VERSION "dbc-export 1 2025.20.8"

NS_ :

BS_:

BU_: ADSP APB APP APS APSB BB BMS CC CMP CMPD CP DAS DI DIF DIR DPB EPAS3P EPAS3S EPASTP EPASTS EPBL EPBR ESP EVSE FC GTW HCML HCMR HVP IBST ICR IDB LS OCS1P PARK PCS PM PMF PMR PNCD PTC RADC RCM RCM2 RCM3 RCU SCCM SCM SCS SDCR TAS TCU TPMS TRCM UI UIS UMC USM VC VCFRONT VCLEFT VCRIGHT VCSEC VEH

BO_ 1835 TAS_alertLog: 8 TAS
 SG_ TAS_alertID M : 0|9@1+ (1,0) [0|511] "" Vector__XXX
 SG_ TAS_alertState : 15|1@1+ (1,0) [0|1] "" Vector__XXX
 SG_ TAS_a001_InternalWatchdog m1 : 16|1@1+ (1,0) [0|1] "" Vector__XXX
 SG_ TAS_a002_CPUUndervoltage m2 : 16|1@1+ (1,0) [0|1] "" Vector__XXX
 SG_ TAS_a002_PowerOnReset m2 : 17|1@1+ (1,0) [0|1] "" Vector__XXX
 SG_ TAS_a003_AssertID m3 : 16|16@1+ (1,0) [0|65535] "" Vector__XXX
 SG_ TAS_a003_LineNumber m3 : 32|16@1+ (1,0) [0|65535] "" Vector__XXX
 SG_ TAS_a003_Data m3 : 48|16@1+ (1,0) [0|65535] "" Vector__XXX
 SG_ TAS_a012_ClockError m12 : 16|1@1+ (1,0) [0|1] "" Vector__XXX
 SG_ TAS_a012_FlashError m12 : 17|1@1+ (1,0) [0|1] "" Vector__XXX
 SG_ TAS_a012_SoftwareReset m12 : 18|1@1+ (1,0) [0|1] "" Vector__XXX
 SG_ TAS_a012_CheckstopReset m12 : 19|1@1+ (1,0) [0|1] "" Vector__XXX
 SG_ TAS_a012_DebugReset m12 : 20|1@1+ (1,0) [0|1] "" Vector__XXX
 SG_ TAS_a012_ExternalReset m12 : 21|1@1+ (1,0) [0|1] "" Vector__XXX
 SG_ TAS_a021_Task1msLate m21 : 16|1@1+ (1,0) [0|1] "" Vector__XXX
 SG_ TAS_a021_Task1msStarved m21 : 17|1@1+ (1,0) [0|1] "" Vector__XXX
 SG_ TAS_a021_Task1msMissed m21 : 18|1@1+ (1,0) [0|1] "" Vector__XXX
 SG_ TAS_a021_Task10msLate m21 : 19|1@1+ (1,0) [0|1] "" Vector__XXX
 SG_ TAS_a021_Task10msStarved m21 : 20|1@1+ (1,0) [0|1] "" Vector__XXX
 SG_ TAS_a021_Task10msMissed m21 : 21|1@1+ (1,0) [0|1] "" Vector__XXX
 SG_ TAS_a021_Task100msLate m21 : 22|1@1+ (1,0) [0|1] "" Vector__XXX
 SG_ TAS_a021_Task100msStarved m21 : 23|1@1+ (1,0) [0|1] "" Vector__XXX
 SG_ TAS_a021_Task100msMissed m21 : 24|1@1+ (1,0) [0|1] "" Vector__XXX
 SG_ TAS_a021_Task1000msLate m21 : 25|1@1+ (1,0) [0|1] "" Vector__XXX
 SG_ TAS_a021_Task1000msStarved m21 : 26|1@1+ (1,0) [0|1] "" Vector__XXX
 SG_ TAS_a021_Task1000msMissed m21 : 27|1@1+ (1,0) [0|1] "" Vector__XXX
 SG_ TAS_a022_TaskInitErrorCount m22 : 16|8@1+ (1,0) [0|255] "" Vector__XXX
 SG_ TAS_a022_TaskInitError0 m22 : 24|8@1+ (1,0) [0|255] "" Vector__XXX
 SG_ TAS_a022_TaskInitError1 m22 : 32|8@1+ (1,0) [0|255] "" Vector__XXX
 SG_ TAS_a022_TaskInitError2 m22 : 40|8@1+ (1,0) [0|255] "" Vector__XXX
 SG_ TAS_a022_TaskInitError3 m22 : 48|8@1+ (1,0) [0|255] "" Vector__XXX
 SG_ TAS_a022_TaskInitError4 m22 : 56|8@1+ (1,0) [0|255] "" Vector__XXX
 SG_ TAS_a025_vehicleLockAtCrash m25 : 16|1@1+ (1,0) [0|1] "" Vector__XXX
 SG_ TAS_a025_CANCrashIsActive m25 : 17|1@1+ (1,0) [0|1] "" Vector__XXX
 SG_ TAS_a025_appCrashIsActive m25 : 18|1@1+ (1,0) [0|1] "" Vector__XXX
 SG_ TAS_a025_lastCrashEvent m25 : 24|32@1+ (1,0) [0|4294967295] "" Vector__XXX
 SG_ TAS_a030_PWMdutyCycleFL m30 : 16|16@1+ (0.0025,0) [0|163.8375] "" Vector__XXX
 SG_ TAS_a030_PWMfrequencyFL m30 : 32|16@1+ (0.025,0) [0|1638.375] "" Vector__XXX
 SG_ TAS_a030_PWMfaultFL m30 : 48|4@1+ (1,0) [0|15] "" Vector__XXX
 SG_ TAS_a031_PWMdutyCycleFR m31 : 16|16@1+ (0.0025,0) [0|163.8375] "" Vector__XXX
 SG_ TAS_a031_PWMfrequencyFR m31 : 32|16@1+ (0.025,0) [0|1638.375] "" Vector__XXX
 SG_ TAS_a031_PWMfaultFR m31 : 48|4@1+ (1,0) [0|15] "" Vector__XXX
 SG_ TAS_a032_PWMdutyCycleRL m32 : 16|16@1+ (0.0025,0) [0|163.8375] "" Vector__XXX
 SG_ TAS_a032_PWMfrequencyRL m32 : 32|16@1+ (0.025,0) [0|1638.375] "" Vector__XXX
 SG_ TAS_a032_PWMfaultRL m32 : 48|4@1+ (1,0) [0|15] "" Vector__XXX
 SG_ TAS_a033_PWMdutyCycleRR m33 : 16|16@1+ (0.0025,0) [0|163.8375] "" Vector__XXX
 SG_ TAS_a033_PWMfrequencyRR m33 : 32|16@1+ (0.025,0) [0|1638.375] "" Vector__XXX
 SG_ TAS_a033_PWMfaultRR m33 : 48|4@1+ (1,0) [0|15] "" Vector__XXX
 SG_ TAS_a034_PWMdutyCycleFL m34 : 16|16@1+ (0.0025,0) [0|163.8375] "" Vector__XXX
 SG_ TAS_a034_PWMfrequencyFL m34 : 32|16@1+ (0.025,0) [0|1638.375] "" Vector__XXX
 SG_ TAS_a034_PWMfaultFL m34 : 48|4@1+ (1,0) [0|15] "" Vector__XXX
 SG_ TAS_a035_PWMdutyCycleFR m35 : 16|16@1+ (0.0025,0) [0|163.8375] "" Vector__XXX
 SG_ TAS_a035_PWMfrequencyFR m35 : 32|16@1+ (0.025,0) [0|1638.375] "" Vector__XXX
 SG_ TAS_a035_PWMfaultFR m35 : 48|4@1+ (1,0) [0|15] "" Vector__XXX
 SG_ TAS_a036_PWMdutyCycleRL m36 : 16|16@1+ (0.0025,0) [0|163.8375] "" Vector__XXX
 SG_ TAS_a036_PWMfrequencyRL m36 : 32|16@1+ (0.025,0) [0|1638.375] "" Vector__XXX
 SG_ TAS_a036_PWMfaultRL m36 : 48|4@1+ (1,0) [0|15] "" Vector__XXX
 SG_ TAS_a037_PWMdutyCycleRR m37 : 16|16@1+ (0.0025,0) [0|163.8375] "" Vector__XXX
 SG_ TAS_a037_PWMfrequencyRR m37 : 32|16@1+ (0.025,0) [0|1638.375] "" Vector__XXX
 SG_ TAS_a037_PWMfaultRR m37 : 48|4@1+ (1,0) [0|15] "" Vector__XXX
 SG_ TAS_a038_PWMdutyCycleFL m38 : 16|16@1+ (0.0025,0) [0|163.8375] "" Vector__XXX
 SG_ TAS_a038_PWMfrequencyFL m38 : 32|16@1+ (0.025,0) [0|1638.375] "" Vector__XXX
 SG_ TAS_a038_PWMfaultFL m38 : 48|4@1+ (1,0) [0|15] "" Vector__XXX
 SG_ TAS_a039_PWMdutyCycleFR m39 : 16|16@1+ (0.0025,0) [0|163.8375] "" Vector__XXX
 SG_ TAS_a039_PWMfrequencyFR m39 : 32|16@1+ (0.025,0) [0|1638.375] "" Vector__XXX
 SG_ TAS_a039_PWMfaultFR m39 : 48|4@1+ (1,0) [0|15] "" Vector__XXX
 SG_ TAS_a040_PWMdutyCycleRL m40 : 16|16@1+ (0.0025,0) [0|163.8375] "" Vector__XXX
 SG_ TAS_a040_PWMfrequencyRL m40 : 32|16@1+ (0.025,0) [0|1638.375] "" Vector__XXX
 SG_ TAS_a040_PWMfaultRL m40 : 48|4@1+ (1,0) [0|15] "" Vector__XXX
 SG_ TAS_a041_PWMdutyCycleRR m41 : 16|16@1+ (0.0025,0) [0|163.8375] "" Vector__XXX
 SG_ TAS_a041_PWMfrequencyRR m41 : 32|16@1+ (0.025,0) [0|1638.375] "" Vector__XXX
 SG_ TAS_a041_PWMfaultRR m41 : 48|4@1+ (1,0) [0|15] "" Vector__XXX
 SG_ TAS_a070_voltage12V m70 : 16|16@1+ (0.001,0) [0|65.535] "" Vector__XXX
 SG_ TAS_a071_voltage12V m71 : 16|16@1+ (0.001,0) [0|65.535] "" Vector__XXX
 SG_ TAS_a072_voltage5VOnBoard m72 : 16|16@1+ (0.001,0) [0|65.535] "" Vector__XXX
 SG_ TAS_a073_voltage5VOnBoard m73 : 16|16@1+ (0.001,0) [0|65.535] "" Vector__XXX
 SG_ TAS_a074_voltage5VOffBoard m74 : 16|16@1+ (0.001,0) [0|65.535] "" Vector__XXX
 SG_ TAS_a075_voltage5VOffBoard m75 : 16|16@1+ (0.001,0) [0|65.535] "" Vector__XXX
 SG_ TAS_a076_voltage5VOffBoard m76 : 16|16@1+ (0.001,0) [0|65.535] "" Vector__XXX
 SG_ TAS_a077_sensorVoltage m77 : 16|16@1+ (0.001,0) [0|65.535] "" Vector__XXX
 SG_ TAS_a077_sensorRefVoltage m77 : 32|16@1+ (0.001,0) [0|65.535] "" Vector__XXX
 SG_ TAS_a078_sensorVoltage m78 : 16|16@1+ (0.001,0) [0|65.535] "" Vector__XXX
 SG_ TAS_a078_sensorRefVoltage m78 : 32|16@1+ (0.001,0) [0|65.535] "" Vector__XXX
 SG_ TAS_a080_voltage5VHeight m80 : 16|16@1+ (0.001,0) [0|65.535] "" Vector__XXX
 SG_ TAS_a081_voltage5VHeight m81 : 16|16@1+ (0.001,0) [0|65.535] "" Vector__XXX
 SG_ TAS_a082_voltage5VHeight m82 : 16|16@1+ (0.001,0) [0|65.535] "" Vector__XXX
 SG_ TAS_a083_voltage5VAnalog m83 : 16|16@1+ (0.001,0) [0|65.535] "" Vector__XXX
 SG_ TAS_a084_voltage5VAnalog m84 : 16|16@1+ (0.001,0) [0|65.535] "" Vector__XXX
 SG_ TAS_a085_voltage5VAnalog m85 : 16|16@1+ (0.001,0) [0|65.535] "" Vector__XXX
 SG_ TAS_a086_voltage12VSwitched m86 : 16|16@1+ (0.001,0) [0|65.535] "" Vector__XXX
 SG_ TAS_a087_voltage12VSwitched m87 : 16|16@1+ (0.001,0) [0|65.535] "" Vector__XXX
 SG_ TAS_a093_readError m93 : 16|1@1+ (1,0) [0|1] "" Vector__XXX
 SG_ TAS_a093_IVOR2Exception m93 : 17|1@1+ (1,0) [0|1] "" Vector__XXX
 SG_ TAS_a098_VCFRONT_LVPowerState_MI m98 : 16|1@1+ (1,0) [0|1] "" Vector__XXX
 SG_ TAS_a098_VCFRONT_sensors_MIA m98 : 17|1@1+ (1,0) [0|1] "" Vector__XXX
 SG_ TAS_a098_VCFRONT_status_MIA m98 : 18|1@1+ (1,0) [0|1] "" Vector__XXX
 SG_ TAS_a098_VCFRONT_systemStatus_MI m98 : 19|1@1+ (1,0) [0|1] "" Vector__XXX
 SG_ TAS_a098_VCFRONT_vehNm_MIA m98 : 20|1@1+ (1,0) [0|1] "" Vector__XXX
 SG_ TAS_a099_UI_chassisControl_MIA m99 : 16|1@1+ (1,0) [0|1] "" Vector__XXX
 SG_ TAS_a099_UI_driverAssistMapData_ m99 : 17|1@1+ (1,0) [0|1] "" Vector__XXX
 SG_ TAS_a099_UI_suspensionControl_MI m99 : 18|1@1+ (1,0) [0|1] "" Vector__XXX
 SG_ TAS_a099_UI_vehicleModes_MIA m99 : 19|1@1+ (1,0) [0|1] "" Vector__XXX
 SG_ TAS_a100_RCM_inertial1_MIA m100 : 16|1@1+ (1,0) [0|1] "" Vector__XXX
 SG_ TAS_a100_RCM_inertial2_MIA m100 : 17|1@1+ (1,0) [0|1] "" Vector__XXX
 SG_ TAS_a101_ESP_brakeTorque_MIA m101 : 16|1@1+ (1,0) [0|1] "" Vector__XXX
 SG_ TAS_a101_ESP_status_MIA m101 : 17|1@1+ (1,0) [0|1] "" Vector__XXX
 SG_ TAS_a101_ESP_wheelRotation_MIA m101 : 18|1@1+ (1,0) [0|1] "" Vector__XXX
 SG_ TAS_a102_DI_chassisControl_MIA m102 : 16|1@1+ (1,0) [0|1] "" Vector__XXX
 SG_ TAS_a102_DI_locStatus_MIA m102 : 17|1@1+ (1,0) [0|1] "" Vector__XXX
 SG_ TAS_a102_DI_speed_MIA m102 : 18|1@1+ (1,0) [0|1] "" Vector__XXX
 SG_ TAS_a102_DI_systemStatus_MIA m102 : 19|1@1+ (1,0) [0|1] "" Vector__XXX
 SG_ TAS_a102_DI_vehicleEstimates_MIA m102 : 20|1@1+ (1,0) [0|1] "" Vector__XXX
 SG_ TAS_a102_DIF_torque_MIA m102 : 21|1@1+ (1,0) [0|1] "" Vector__XXX
 SG_ TAS_a102_DIR_torque_MIA m102 : 22|1@1+ (1,0) [0|1] "" Vector__XXX
 SG_ TAS_a103_GTW_carConfig_MIA m103 : 16|1@1+ (1,0) [0|1] "" Vector__XXX
 SG_ TAS_a103_GTW_time_MIA m103 : 17|1@1+ (1,0) [0|1] "" Vector__XXX
 SG_ TAS_a103_GTW_vehNm_MIA m103 : 18|1@1+ (1,0) [0|1] "" Vector__XXX
 SG_ TAS_a103_GTW_vin_MIA m103 : 19|1@1+ (1,0) [0|1] "" Vector__XXX
 SG_ TAS_a164_detectedDamperSolenoid m164 : 16|3@1+ (1,0) [0|7] "" Vector__XXX
 SG_ TAS_a164_expectedDamperSolenoid m164 : 19|3@1+ (1,0) [0|7] "" Vector__XXX
 SG_ TAS_a165_damperValveFault m165 : 16|4@1+ (1,0) [0|15] "" Vector__XXX
 SG_ TAS_a166_damperValveFault m166 : 16|4@1+ (1,0) [0|15] "" Vector__XXX
 SG_ TAS_a167_damperValveFault m167 : 16|4@1+ (1,0) [0|15] "" Vector__XXX
 SG_ TAS_a168_damperValveFault m168 : 16|4@1+ (1,0) [0|15] "" Vector__XXX
 SG_ TAS_a169_damperValveFault m169 : 16|4@1+ (1,0) [0|15] "" Vector__XXX
 SG_ TAS_a170_damperValveFault m170 : 16|4@1+ (1,0) [0|15] "" Vector__XXX
 SG_ TAS_a171_damperValveFault m171 : 16|4@1+ (1,0) [0|15] "" Vector__XXX
 SG_ TAS_a172_damperValveFault m172 : 16|4@1+ (1,0) [0|15] "" Vector__XXX
 SG_ TAS_a173_heightDelta_mm m173 : 16|8@1+ (1,-128) [-128|127] "" Vector__XXX
 SG_ TAS_a174_heightDelta_mm m174 : 16|8@1+ (1,-128) [-128|127] "" Vector__XXX
 SG_ TAS_a175_heightDelta_mm m175 : 16|8@1+ (1,-128) [-128|127] "" Vector__XXX
 SG_ TAS_a176_heightDelta_mm m176 : 16|8@1+ (1,-128) [-128|127] "" Vector__XXX
 SG_ TAS_a190_a2bFaultType m190 : 16|4@1+ (1,0) [0|15] "" Vector__XXX
 SG_ TAS_a190_a2bInterruptType m190 : 24|8@1+ (1,0) [0|255] "" Vector__XXX
 SG_ TAS_a190_a2bFaultSource m190 : 32|2@1+ (1,0) [0|3] "" Vector__XXX
 SG_ TAS_a191_a2bFaultType m191 : 16|4@1+ (1,0) [0|15] "" Vector__XXX
 SG_ TAS_a191_a2bInterruptType m191 : 24|8@1+ (1,0) [0|255] "" Vector__XXX
 SG_ TAS_a191_a2bFaultSource m191 : 32|2@1+ (1,0) [0|3] "" Vector__XXX
 SG_ TAS_a192_rideHeightVelDspFL m192 : 16|5@1- (0.2,0) [-3.2|3] "" Vector__XXX
 SG_ TAS_a192_rideHeightVelDspFR m192 : 24|5@1- (0.2,0) [-3.2|3] "" Vector__XXX
 SG_ TAS_a192_rideHeightVelDspRL m192 : 32|5@1- (0.2,0) [-3.2|3] "" Vector__XXX
 SG_ TAS_a192_rideHeightVelDspRR m192 : 37|5@1- (0.2,0) [-3.2|3] "" Vector__XXX
 SG_ TAS_a192_rideHeightVelObserverFL m192 : 42|5@1- (0.2,0) [-3.2|3] "" Vector__XXX
 SG_ TAS_a192_rideHeightVelObserverFR m192 : 47|5@1- (0.2,0) [-3.2|3] "" Vector__XXX
 SG_ TAS_a192_rideHeightVelObserverRL m192 : 52|5@1- (0.2,0) [-3.2|3] "" Vector__XXX
 SG_ TAS_a192_rideHeightVelObserverRR m192 : 57|5@1- (0.2,0) [-3.2|3] "" Vector__XXX
 SG_ TAS_a192_alertVersion m192 : 62|2@1+ (1,0) [0|3] "" Vector__XXX
 SG_ TAS_a193_EPAS3P_sysStatus_MIA m193 : 16|1@1+ (1,0) [0|1] "" Vector__XXX
 SG_ TAS_a210_heightSensorDeltaFL m210 : 16|8@1+ (1,-128) [-128|127] "" Vector__XXX
 SG_ TAS_a210_heightSensorDeltaFR m210 : 24|8@1+ (1,-128) [-128|127] "" Vector__XXX
 SG_ TAS_a210_heightSensorDeltaRL m210 : 32|8@1+ (1,-128) [-128|127] "" Vector__XXX
 SG_ TAS_a210_heightSensorDeltaRR m210 : 40|8@1+ (1,-128) [-128|127] "" Vector__XXX
 SG_ TAS_a220_galleryPressure m220 : 16|8@1+ (0.1,0) [0|25.5] "" Vector__XXX
 SG_ TAS_a220_timeInExhaust m220 : 24|32@1+ (1,0) [0|4294967295] "" Vector__XXX
 SG_ TAS_a221_galleryPressureDelta m221 : 16|8@1+ (0.1,0) [0|25.5] "" Vector__XXX
 SG_ TAS_a221_timeInIdle m221 : 24|32@1+ (1,0) [0|4294967295] "" Vector__XXX
 SG_ TAS_a222_galleryPressureDelta m222 : 16|8@1+ (0.1,0) [0|25.5] "" Vector__XXX
 SG_ TAS_a223_galleryPressure m223 : 16|8@1+ (0.1,0) [0|25.5] "" Vector__XXX
 SG_ TAS_a223_valveOnFL m223 : 24|1@1+ (1,0) [0|1] "" Vector__XXX
 SG_ TAS_a223_valveOnFR m223 : 25|1@1+ (1,0) [0|1] "" Vector__XXX
 SG_ TAS_a223_valveOnRL m223 : 26|1@1+ (1,0) [0|1] "" Vector__XXX
 SG_ TAS_a223_valveOnRR m223 : 27|1@1+ (1,0) [0|1] "" Vector__XXX
 SG_ TAS_a223_valveOnReservoir m223 : 28|1@1+ (1,0) [0|1] "" Vector__XXX
 SG_ TAS_a224_galleryPressure m224 : 16|8@1+ (0.1,0) [0|25.5] "" Vector__XXX
 SG_ TAS_a224_valveOnFL m224 : 24|1@1+ (1,0) [0|1] "" Vector__XXX
 SG_ TAS_a224_valveOnFR m224 : 25|1@1+ (1,0) [0|1] "" Vector__XXX
 SG_ TAS_a224_valveOnRL m224 : 26|1@1+ (1,0) [0|1] "" Vector__XXX
 SG_ TAS_a224_valveOnRR m224 : 27|1@1+ (1,0) [0|1] "" Vector__XXX
 SG_ TAS_a224_valveOnReservoir m224 : 28|1@1+ (1,0) [0|1] "" Vector__XXX
 SG_ TAS_a225_galleryPressure m225 : 16|8@1+ (0.1,0) [0|25.5] "" Vector__XXX
 SG_ TAS_a226_PWMdutyCycleFL m226 : 16|16@1+ (0.0025,0) [0|163.8375] "" Vector__XXX
 SG_ TAS_a226_PWMfrequencyFL m226 : 32|16@1+ (0.025,0) [0|1638.375] "" Vector__XXX
 SG_ TAS_a226_PWMfaultFL m226 : 48|4@1+ (1,0) [0|15] "" Vector__XXX
 SG_ TAS_a227_PWMdutyCycleFR m227 : 16|16@1+ (0.0025,0) [0|163.8375] "" Vector__XXX
 SG_ TAS_a227_PWMfrequencyFR m227 : 32|16@1+ (0.025,0) [0|1638.375] "" Vector__XXX
 SG_ TAS_a227_PWMfaultFR m227 : 48|4@1+ (1,0) [0|15] "" Vector__XXX
 SG_ TAS_a228_PWMdutyCycleRL m228 : 16|16@1+ (0.0025,0) [0|163.8375] "" Vector__XXX
 SG_ TAS_a228_PWMfrequencyRL m228 : 32|16@1+ (0.025,0) [0|1638.375] "" Vector__XXX
 SG_ TAS_a228_PWMfaultRL m228 : 48|4@1+ (1,0) [0|15] "" Vector__XXX
 SG_ TAS_a229_PWMdutyCycleRR m229 : 16|16@1+ (0.0025,0) [0|163.8375] "" Vector__XXX
 SG_ TAS_a229_PWMfrequencyRR m229 : 32|16@1+ (0.025,0) [0|1638.375] "" Vector__XXX
 SG_ TAS_a229_PWMfaultRR m229 : 48|4@1+ (1,0) [0|15] "" Vector__XXX
 SG_ TAS_a232_detectedSuspensionType m232 : 16|3@1+ (1,0) [0|7] "" Vector__XXX
 SG_ TAS_a232_expectedSuspensionType m232 : 19|3@1+ (1,0) [0|7] "" Vector__XXX
 SG_ TAS_a234_detectedDamperHydraulic m234 : 16|2@1+ (1,0) [0|3] "" Vector__XXX
 SG_ TAS_a234_expectedDamperHydraulic m234 : 18|2@1+ (1,0) [0|3] "" Vector__XXX
 SG_ TAS_a240_highAdjustCountRatio m240 : 16|1@1+ (1,0) [0|1] "" Vector__XXX
 SG_ TAS_a240_highAdjustTimeRatio m240 : 17|1@1+ (1,0) [0|1] "" Vector__XXX
 SG_ TAS_a240_highCrossPressure m240 : 18|1@1+ (1,0) [0|1] "" Vector__XXX
 SG_ TAS_a240_highCompExhTimeRatio m240 : 19|1@1+ (1,0) [0|1] "" Vector__XXX
 SG_ TAS_a240_adjustCountRatioSpring m240 : 20|3@1+ (1,0) [0|7] "" Vector__XXX
 SG_ TAS_a240_adjustCountRatio m240 : 24|8@1+ (0.02952756,0) [0|7.5295278] "" Vector__XXX
 SG_ TAS_a240_adjustTimeRatioSpring m240 : 32|3@1+ (1,0) [0|7] "" Vector__XXX
 SG_ TAS_a240_adjustTimeRatio m240 : 40|8@1+ (0.02952756,0) [0|7.5295278] "" Vector__XXX
 SG_ TAS_a240_compExhTimeRatio m240 : 48|8@1+ (0.0294117648154,0) [0|7.50000002793] "" Vector__XXX
 SG_ TAS_a240_crossPressure m240 : 56|8@1- (0.1,0) [-12.8|12.7] "" Vector__XXX
 SG_ TAS_a285_twistLevel m285 : 16|8@1+ (1,-128) [-128|127] "" Vector__XXX
 SG_ TAS_a290_twistLevel m290 : 16|8@1+ (1,-128) [-128|127] "" Vector__XXX
 SG_ TAS_a291_frontAxleHeight m291 : 16|8@1+ (1,-128) [-128|127] "" Vector__XXX
 SG_ TAS_a292_rearAxleHeight m292 : 16|8@1+ (1,-128) [-128|127] "" Vector__XXX
 SG_ TAS_a293_frontAxleHeight m293 : 16|8@1+ (1,-128) [-128|127] "" Vector__XXX
 SG_ TAS_a294_rearAxleHeight m294 : 16|8@1+ (1,-128) [-128|127] "" Vector__XXX
 SG_ TAS_a295_targetHeight m295 : 16|8@1+ (1,-128) [-128|127] "" Vector__XXX
 SG_ TAS_a296_detectedChassisType m296 : 16|3@1+ (1,0) [0|7] "" Vector__XXX
 SG_ TAS_a296_expectedChassisType m296 : 19|3@1+ (1,0) [0|7] "" Vector__XXX
 SG_ TAS_a319_detectedDrivetrainType m319 : 16|2@1+ (1,0) [0|3] "" Vector__XXX
 SG_ TAS_a319_expectedDrivetrainType m319 : 18|2@1+ (1,0) [0|3] "" Vector__XXX

BO_ 852 TAS_alertMatrix: 8 TAS
 SG_ TAS_matrixIndex M : 0|4@1+ (1,0) [0|15] "" Vector__XXX
 SG_ TAS_a001_WatchdogReset m0 : 4|1@1+ (1,0) [0|1] "" Vector__XXX
 SG_ TAS_a002_PowerLossReset m0 : 5|1@1+ (1,0) [0|1] "" Vector__XXX
 SG_ TAS_a003_SWAssertion m0 : 6|1@1+ (1,0) [0|1] "" Vector__XXX
 SG_ TAS_a012_CPUReset m0 : 15|1@1+ (1,0) [0|1] "" Vector__XXX
 SG_ TAS_a015_NVMMError m0 : 18|1@1+ (1,0) [0|1] "" Vector__XXX
 SG_ TAS_a016_NVMMRecordError m0 : 19|1@1+ (1,0) [0|1] "" Vector__XXX
 SG_ TAS_a021_TaskSchedulerError m0 : 24|1@1+ (1,0) [0|1] "" Vector__XXX
 SG_ TAS_a022_TaskInitError m0 : 25|1@1+ (1,0) [0|1] "" Vector__XXX
 SG_ TAS_a023_rtosResetRequested m0 : 26|1@1+ (1,0) [0|1] "" Vector__XXX
 SG_ TAS_a024_prefetchAbort m0 : 27|1@1+ (1,0) [0|1] "" Vector__XXX
 SG_ TAS_a025_CrashEvent m0 : 28|1@1+ (1,0) [0|1] "" Vector__XXX
 SG_ TAS_a030_PWMerrorFL m0 : 33|1@1+ (1,0) [0|1] "" Vector__XXX
 SG_ TAS_a031_PWMerrorFR m0 : 34|1@1+ (1,0) [0|1] "" Vector__XXX
 SG_ TAS_a032_PWMerrorRL m0 : 35|1@1+ (1,0) [0|1] "" Vector__XXX
 SG_ TAS_a033_PWMerrorRR m0 : 36|1@1+ (1,0) [0|1] "" Vector__XXX
 SG_ TAS_a034_PWMshortFL m0 : 37|1@1+ (1,0) [0|1] "" Vector__XXX
 SG_ TAS_a035_PWMshortFR m0 : 38|1@1+ (1,0) [0|1] "" Vector__XXX
 SG_ TAS_a036_PWMshortRL m0 : 39|1@1+ (1,0) [0|1] "" Vector__XXX
 SG_ TAS_a037_PWMshortRR m0 : 40|1@1+ (1,0) [0|1] "" Vector__XXX
 SG_ TAS_a038_PWMopenFL m0 : 41|1@1+ (1,0) [0|1] "" Vector__XXX
 SG_ TAS_a039_PWMopenFR m0 : 42|1@1+ (1,0) [0|1] "" Vector__XXX
 SG_ TAS_a040_PWMopenRL m0 : 43|1@1+ (1,0) [0|1] "" Vector__XXX
 SG_ TAS_a041_PWMopenRR m0 : 44|1@1+ (1,0) [0|1] "" Vector__XXX
 SG_ TAS_a043_Task1msError m0 : 46|1@1+ (1,0) [0|1] "" Vector__XXX
 SG_ TAS_a044_Task10msError m0 : 47|1@1+ (1,0) [0|1] "" Vector__XXX
 SG_ TAS_a045_Task100msError m0 : 48|1@1+ (1,0) [0|1] "" Vector__XXX
 SG_ TAS_a046_Task1000msError m0 : 49|1@1+ (1,0) [0|1] "" Vector__XXX
 SG_ TAS_a061_XCPConnected m1 : 4|1@1+ (1,0) [0|1] "" Vector__XXX
 SG_ TAS_a062_XCPWasConnected m1 : 5|1@1+ (1,0) [0|1] "" Vector__XXX
 SG_ TAS_a063_abortFault m1 : 6|1@1+ (1,0) [0|1] "" Vector__XXX
 SG_ TAS_a064_abortFaultExt m1 : 7|1@1+ (1,0) [0|1] "" Vector__XXX
 SG_ TAS_a065_ahbWriteFault m1 : 8|1@1+ (1,0) [0|1] "" Vector__XXX
 SG_ TAS_a066_undefinedInstructionAbo m1 : 9|1@1+ (1,0) [0|1] "" Vector__XXX
 SG_ TAS_a067_reservedHandlerAbort m1 : 10|1@1+ (1,0) [0|1] "" Vector__XXX
 SG_ TAS_a070_underVoltage12V m1 : 13|1@1+ (1,0) [0|1] "" Vector__XXX
 SG_ TAS_a071_overVoltage12V m1 : 14|1@1+ (1,0) [0|1] "" Vector__XXX
 SG_ TAS_a072_shortCircuit5VOnBoard m1 : 15|1@1+ (1,0) [0|1] "" Vector__XXX
 SG_ TAS_a073_underVoltage5VOnBoard m1 : 16|1@1+ (1,0) [0|1] "" Vector__XXX
 SG_ TAS_a074_shortCircuit5VOffBoard m1 : 17|1@1+ (1,0) [0|1] "" Vector__XXX
 SG_ TAS_a075_underVoltage5VOffBoard m1 : 18|1@1+ (1,0) [0|1] "" Vector__XXX
 SG_ TAS_a076_overVoltage5VOffBoard m1 : 19|1@1+ (1,0) [0|1] "" Vector__XXX
 SG_ TAS_a077_pressureSigVTooLow m1 : 20|1@1+ (1,0) [0|1] "" Vector__XXX
 SG_ TAS_a078_pressureSigVTooHigh m1 : 21|1@1+ (1,0) [0|1] "" Vector__XXX
 SG_ TAS_a080_shortCircuit5VHeight m1 : 23|1@1+ (1,0) [0|1] "" Vector__XXX
 SG_ TAS_a081_underVoltage5VHeight m1 : 24|1@1+ (1,0) [0|1] "" Vector__XXX
 SG_ TAS_a082_overVoltage5VHeight m1 : 25|1@1+ (1,0) [0|1] "" Vector__XXX
 SG_ TAS_a083_shortCircuit5VAnalog m1 : 26|1@1+ (1,0) [0|1] "" Vector__XXX
 SG_ TAS_a084_underVoltage5VAnalog m1 : 27|1@1+ (1,0) [0|1] "" Vector__XXX
 SG_ TAS_a085_overVoltage5VAnalog m1 : 28|1@1+ (1,0) [0|1] "" Vector__XXX
 SG_ TAS_a086_underVoltage12VSwtchd m1 : 29|1@1+ (1,0) [0|1] "" Vector__XXX
 SG_ TAS_a087_overVoltage12VSwtchd m1 : 30|1@1+ (1,0) [0|1] "" Vector__XXX
 SG_ TAS_a093_OTPError m1 : 36|1@1+ (1,0) [0|1] "" Vector__XXX
 SG_ TAS_a098_VCFRONT_MIA m1 : 41|1@1+ (1,0) [0|1] "" Vector__XXX
 SG_ TAS_a099_UI_MIA m1 : 42|1@1+ (1,0) [0|1] "" Vector__XXX
 SG_ TAS_a100_RCM_MIA m1 : 43|1@1+ (1,0) [0|1] "" Vector__XXX
 SG_ TAS_a101_ESP_MIA m1 : 44|1@1+ (1,0) [0|1] "" Vector__XXX
 SG_ TAS_a102_DI_MIA m1 : 45|1@1+ (1,0) [0|1] "" Vector__XXX
 SG_ TAS_a103_GTW_MIA m1 : 46|1@1+ (1,0) [0|1] "" Vector__XXX
 SG_ TAS_a105_ECUDebugMode m1 : 48|1@1+ (1,0) [0|1] "" Vector__XXX
 SG_ TAS_a106_HighCPULoad m1 : 49|1@1+ (1,0) [0|1] "" Vector__XXX
 SG_ TAS_a107_HighStackUsage m1 : 50|1@1+ (1,0) [0|1] "" Vector__XXX
 SG_ TAS_a150_accelAvgImplausible_FL_ m2 : 33|1@1+ (1,0) [0|1] "" Vector__XXX
 SG_ TAS_a151_accelAvgImplausible_FL_ m2 : 34|1@1+ (1,0) [0|1] "" Vector__XXX
 SG_ TAS_a152_accelAvgImplausible_FL_ m2 : 35|1@1+ (1,0) [0|1] "" Vector__XXX
 SG_ TAS_a153_accelAvgImplausible_FR_ m2 : 36|1@1+ (1,0) [0|1] "" Vector__XXX
 SG_ TAS_a154_accelAvgImplausible_FR_ m2 : 37|1@1+ (1,0) [0|1] "" Vector__XXX
 SG_ TAS_a155_accelAvgImplausible_FR_ m2 : 38|1@1+ (1,0) [0|1] "" Vector__XXX
 SG_ TAS_a156_accelAvgImplausible_RL_ m2 : 39|1@1+ (1,0) [0|1] "" Vector__XXX
 SG_ TAS_a157_accelAvgImplausible_RL_ m2 : 40|1@1+ (1,0) [0|1] "" Vector__XXX
 SG_ TAS_a158_accelAvgImplausible_RL_ m2 : 41|1@1+ (1,0) [0|1] "" Vector__XXX
 SG_ TAS_a159_accelAvgImplausible_RR_ m2 : 42|1@1+ (1,0) [0|1] "" Vector__XXX
 SG_ TAS_a160_accelAvgImplausible_RR_ m2 : 43|1@1+ (1,0) [0|1] "" Vector__XXX
 SG_ TAS_a161_accelAvgImplausible_RR_ m2 : 44|1@1+ (1,0) [0|1] "" Vector__XXX
 SG_ TAS_a164_damperSolenoidMismatch m2 : 47|1@1+ (1,0) [0|1] "" Vector__XXX
 SG_ TAS_a165_damperValveCompFL m2 : 48|1@1+ (1,0) [0|1] "" Vector__XXX
 SG_ TAS_a166_damperValveRbndFL m2 : 49|1@1+ (1,0) [0|1] "" Vector__XXX
 SG_ TAS_a167_damperValveCompFR m2 : 50|1@1+ (1,0) [0|1] "" Vector__XXX
 SG_ TAS_a168_damperValveRbndFR m2 : 51|1@1+ (1,0) [0|1] "" Vector__XXX
 SG_ TAS_a169_damperValveCompRL m2 : 52|1@1+ (1,0) [0|1] "" Vector__XXX
 SG_ TAS_a170_damperValveRbndRL m2 : 53|1@1+ (1,0) [0|1] "" Vector__XXX
 SG_ TAS_a171_damperValveCompRR m2 : 54|1@1+ (1,0) [0|1] "" Vector__XXX
 SG_ TAS_a172_damperValveRbndRR m2 : 55|1@1+ (1,0) [0|1] "" Vector__XXX
 SG_ TAS_a173_staticLeakDetectFL m2 : 56|1@1+ (1,0) [0|1] "" Vector__XXX
 SG_ TAS_a174_staticLeakDetectFR m2 : 57|1@1+ (1,0) [0|1] "" Vector__XXX
 SG_ TAS_a175_staticLeakDetectRL m2 : 58|1@1+ (1,0) [0|1] "" Vector__XXX
 SG_ TAS_a176_staticLeakDetectRR m2 : 59|1@1+ (1,0) [0|1] "" Vector__XXX
 SG_ TAS_a190_a2bFrontAxleFault m3 : 13|1@1+ (1,0) [0|1] "" Vector__XXX
 SG_ TAS_a191_a2bRearAxleFault m3 : 14|1@1+ (1,0) [0|1] "" Vector__XXX
 SG_ TAS_a192_rideHeightObserverDiver m3 : 15|1@1+ (1,0) [0|1] "" Vector__XXX
 SG_ TAS_a193_EPAS3P_MIA m3 : 16|1@1+ (1,0) [0|1] "" Vector__XXX
 SG_ TAS_a194_a2bFrontAxleDataError m3 : 17|1@1+ (1,0) [0|1] "" Vector__XXX
 SG_ TAS_a195_a2bRearAxleDataError m3 : 18|1@1+ (1,0) [0|1] "" Vector__XXX
 SG_ TAS_a196_adaptiveDampingUsingDSP m3 : 19|1@1+ (1,0) [0|1] "" Vector__XXX
 SG_ TAS_a197_invalidAdaptiveModeRequ m3 : 20|1@1+ (1,0) [0|1] "" Vector__XXX
 SG_ TAS_a200_jackModeActive m3 : 23|1@1+ (1,0) [0|1] "" Vector__XXX
 SG_ TAS_a201_low12VBattery m3 : 24|1@1+ (1,0) [0|1] "" Vector__XXX
 SG_ TAS_a210_outOfRangeCalibration m3 : 33|1@1+ (1,0) [0|1] "" Vector__XXX
 SG_ TAS_a211_noRideHeightCalib m3 : 34|1@1+ (1,0) [0|1] "" Vector__XXX
 SG_ TAS_a213_yellowWarningLamp m3 : 36|1@1+ (1,0) [0|1] "" Vector__XXX
 SG_ TAS_a214_redWarningLamp m3 : 37|1@1+ (1,0) [0|1] "" Vector__XXX
 SG_ TAS_a215_limpHomeMode10 m3 : 38|1@1+ (1,0) [0|1] "" Vector__XXX
 SG_ TAS_a216_limpHomeMode20 m3 : 39|1@1+ (1,0) [0|1] "" Vector__XXX
 SG_ TAS_a217_limpHomeMode30 m3 : 40|1@1+ (1,0) [0|1] "" Vector__XXX
 SG_ TAS_a218_limpHomeMode40 m3 : 41|1@1+ (1,0) [0|1] "" Vector__XXX
 SG_ TAS_a220_exhaustGalleryFault m3 : 43|1@1+ (1,0) [0|1] "" Vector__XXX
 SG_ TAS_a221_valveLeakDetected m3 : 44|1@1+ (1,0) [0|1] "" Vector__XXX
 SG_ TAS_a222_compressorPrefillFault m3 : 45|1@1+ (1,0) [0|1] "" Vector__XXX
 SG_ TAS_a223_blockedAirline m3 : 46|1@1+ (1,0) [0|1] "" Vector__XXX
 SG_ TAS_a224_openAirline m3 : 47|1@1+ (1,0) [0|1] "" Vector__XXX
 SG_ TAS_a225_galleryPressureTooHigh m3 : 48|1@1+ (1,0) [0|1] "" Vector__XXX
 SG_ TAS_a226_PWMfastDetectFL m3 : 49|1@1+ (1,0) [0|1] "" Vector__XXX
 SG_ TAS_a227_PWMfastDetectFR m3 : 50|1@1+ (1,0) [0|1] "" Vector__XXX
 SG_ TAS_a228_PWMfastDetectRL m3 : 51|1@1+ (1,0) [0|1] "" Vector__XXX
 SG_ TAS_a229_PWMfastDetectRR m3 : 52|1@1+ (1,0) [0|1] "" Vector__XXX
 SG_ TAS_a230_notifyGeofence m3 : 53|1@1+ (1,0) [0|1] "" Vector__XXX
 SG_ TAS_a231_notifyRoughRoadRaise m3 : 54|1@1+ (1,0) [0|1] "" Vector__XXX
 SG_ TAS_a232_suspensionTypeMismatch m3 : 55|1@1+ (1,0) [0|1] "" Vector__XXX
 SG_ TAS_a233_compressorStuckOn m3 : 56|1@1+ (1,0) [0|1] "" Vector__XXX
 SG_ TAS_a234_damperHydraulicMismatch m3 : 57|1@1+ (1,0) [0|1] "" Vector__XXX
 SG_ TAS_a240_airSpringLeak m3 : 63|1@1+ (1,0) [0|1] "" Vector__XXX
 SG_ TAS_a284_serviceRunModeActive m4 : 47|1@1+ (1,0) [0|1] "" Vector__XXX
 SG_ TAS_a285_twistSustainedUserVis m4 : 48|1@1+ (1,0) [0|1] "" Vector__XXX
 SG_ TAS_a286_driveCycleStats1 m4 : 49|1@1+ (1,0) [0|1] "" Vector__XXX
 SG_ TAS_a287_driveCycleStats2 m4 : 50|1@1+ (1,0) [0|1] "" Vector__XXX
 SG_ TAS_a288_driveCycleStats3 m4 : 51|1@1+ (1,0) [0|1] "" Vector__XXX
 SG_ TAS_a289_driveCycleStats4 m4 : 52|1@1+ (1,0) [0|1] "" Vector__XXX
 SG_ TAS_a290_twistSustainedAtSpeed m4 : 53|1@1+ (1,0) [0|1] "" Vector__XXX
 SG_ TAS_a291_frontAxleTooHigh m4 : 54|1@1+ (1,0) [0|1] "" Vector__XXX
 SG_ TAS_a292_rearAxleTooHigh m4 : 55|1@1+ (1,0) [0|1] "" Vector__XXX
 SG_ TAS_a293_frontAxleTooLow m4 : 56|1@1+ (1,0) [0|1] "" Vector__XXX
 SG_ TAS_a294_rearAxleTooLow m4 : 57|1@1+ (1,0) [0|1] "" Vector__XXX
 SG_ TAS_a295_targetHeightNotMet m4 : 58|1@1+ (1,0) [0|1] "" Vector__XXX
 SG_ TAS_a296_chassisTypeMismatch m4 : 59|1@1+ (1,0) [0|1] "" Vector__XXX
 SG_ TAS_a297_vinMismatch m4 : 60|1@1+ (1,0) [0|1] "" Vector__XXX
 SG_ TAS_a298_vinNotLearned m4 : 61|1@1+ (1,0) [0|1] "" Vector__XXX
 SG_ TAS_a299_offsetEstimateTooLarge m4 : 62|1@1+ (1,0) [0|1] "" Vector__XXX
 SG_ TAS_a300_offsetEstimateData1 m4 : 63|1@1+ (1,0) [0|1] "" Vector__XXX
 SG_ TAS_a301_offsetEstimateData2 m5 : 4|1@1+ (1,0) [0|1] "" Vector__XXX
 SG_ TAS_a303_massEstimateFrozen m5 : 6|1@1+ (1,0) [0|1] "" Vector__XXX
 SG_ TAS_a304_massEstimateFrozenData m5 : 7|1@1+ (1,0) [0|1] "" Vector__XXX
 SG_ TAS_a305_newEndstopPosition m5 : 8|1@1+ (1,0) [0|1] "" Vector__XXX
 SG_ TAS_a306_hardwareProtectFrozen m5 : 9|1@1+ (1,0) [0|1] "" Vector__XXX
 SG_ TAS_a307_endstopBoundaryComp m5 : 10|1@1+ (1,0) [0|1] "" Vector__XXX
 SG_ TAS_a308_endstopBoundaryRbnd m5 : 11|1@1+ (1,0) [0|1] "" Vector__XXX
 SG_ TAS_a309_controlFrozen m5 : 12|1@1+ (1,0) [0|1] "" Vector__XXX
 SG_ TAS_a310_controlFrozenData m5 : 13|1@1+ (1,0) [0|1] "" Vector__XXX
 SG_ TAS_a311_accelsMIA m5 : 14|1@1+ (1,0) [0|1] "" Vector__XXX
 SG_ TAS_a312_rotationalRatesMIA m5 : 15|1@1+ (1,0) [0|1] "" Vector__XXX
 SG_ TAS_a313_dampingCntrlDisabled m5 : 16|1@1+ (1,0) [0|1] "" Vector__XXX
 SG_ TAS_a314_dampingReduced m5 : 17|1@1+ (1,0) [0|1] "" Vector__XXX
 SG_ TAS_a315_pcbaHighTemp m5 : 18|1@1+ (1,0) [0|1] "" Vector__XXX
 SG_ TAS_a316_offsetsAccels m5 : 19|1@1+ (1,0) [0|1] "" Vector__XXX
 SG_ TAS_a317_offsetsRotationalRates m5 : 20|1@1+ (1,0) [0|1] "" Vector__XXX
 SG_ TAS_a318_dampingCntrlInputMIA m5 : 21|1@1+ (1,0) [0|1] "" Vector__XXX
 SG_ TAS_a319_drivetrainTypeMismatch m5 : 22|1@1+ (1,0) [0|1] "" Vector__XXX
 SG_ TAS_a320_offsetsRotationalRates m5 : 23|1@1+ (1,0) [0|1] "" Vector__XXX
 SG_ TAS_a321_speedBumpAttributes1 m5 : 24|1@1+ (1,0) [0|1] "" Vector__XXX
 SG_ TAS_a322_speedBumpAttributes2 m5 : 25|1@1+ (1,0) [0|1] "" Vector__XXX
 SG_ TAS_a332_levelingThresholds1 m5 : 35|1@1+ (1,0) [0|1] "" Vector__XXX
 SG_ TAS_a333_levelingThresholds2 m5 : 36|1@1+ (1,0) [0|1] "" Vector__XXX

BO_ 523 TAS_axleData: 8 TAS
 SG_ TAS_axleIndex M : 0|1@1+ (1,0) [0|1] "" Vector__XXX
 SG_ TAS_rawHeightFL m0 : 4|10@1+ (1,-512) [-512|511] "mm" Vector__XXX
 SG_ TAS_staticHeightEstimateFL m0 : 14|10@1+ (1,-512) [-512|511] "mm" Vector__XXX
 SG_ TAS_componentPressureFL m0 : 24|8@1+ (0.1,0) [0|25.5] "bara" Vector__XXX
 SG_ TAS_rawHeightFR m0 : 32|10@1+ (1,-512) [-512|511] "mm" Vector__XXX
 SG_ TAS_staticHeightEstimateFR m0 : 42|10@1+ (1,-512) [-512|511] "mm" Vector__XXX
 SG_ TAS_componentPressureFR m0 : 52|8@1+ (0.1,0) [0|25.5] "bara" Vector__XXX
 SG_ TAS_rawHeightRL m1 : 4|10@1+ (1,-512) [-512|511] "mm" Vector__XXX
 SG_ TAS_staticHeightEstimateRL m1 : 14|10@1+ (1,-512) [-512|511] "mm" Vector__XXX
 SG_ TAS_componentPressureRL m1 : 24|8@1+ (0.1,0) [0|25.5] "bara" Vector__XXX
 SG_ TAS_rawHeightRR m1 : 32|10@1+ (1,-512) [-512|511] "mm" Vector__XXX
 SG_ TAS_staticHeightEstimateRR m1 : 42|10@1+ (1,-512) [-512|511] "mm" Vector__XXX
 SG_ TAS_componentPressureRR m1 : 52|8@1+ (0.1,0) [0|25.5] "bara" Vector__XXX

BO_ 1398 TAS_dampingStates: 8 TAS
 SG_ TAS_endstopState : 0|1@1+ (1,0) [0|1] "" Vector__XXX
 SG_ TAS_continuousControlState : 1|1@1+ (1,0) [0|1] "" Vector__XXX
 SG_ TAS_activeTireTune : 2|1@1+ (1,0) [0|1] "" Vector__XXX
 SG_ TAS_roughnessRaiseReason : 3|2@1+ (1,0) [0|3] "" Vector__XXX
 SG_ TAS_frontMetricDrivesRear : 5|2@1+ (1,0) [0|3] "" Vector__XXX
 SG_ TAS_roadCondition : 8|8@1+ (0.005,0) [0|1.275] "-" Vector__XXX
 SG_ TAS_bellyProtect : 16|2@1+ (1,0) [0|3] "" Vector__XXX
 SG_ TAS_frontMetricDrivesFront : 18|2@1+ (1,0) [0|3] "" Vector__XXX
 SG_ TAS_speedBumpAxleFront : 20|3@1+ (1,0) [0|7] "" Vector__XXX
 SG_ TAS_speedBumpAxleRear : 23|3@1+ (1,0) [0|7] "" Vector__XXX
 SG_ TAS_holeProtectFL : 26|2@1+ (1,0) [0|3] "" Vector__XXX
 SG_ TAS_holeProtectFR : 28|2@1+ (1,0) [0|3] "" Vector__XXX
 SG_ TAS_holeProtectRL : 30|2@1+ (1,0) [0|3] "" Vector__XXX
 SG_ TAS_holeProtectRR : 32|2@1+ (1,0) [0|3] "" Vector__XXX
 SG_ TAS_stepProtectFL : 34|2@1+ (1,0) [0|3] "" Vector__XXX
 SG_ TAS_stepProtectFR : 36|2@1+ (1,0) [0|3] "" Vector__XXX
 SG_ TAS_stepProtectRL : 38|2@1+ (1,0) [0|3] "" Vector__XXX
 SG_ TAS_stepProtectRR : 40|2@1+ (1,0) [0|3] "" Vector__XXX
 SG_ TAS_FDUTorqueCorruptionScale : 42|4@1+ (0.075,0) [0|1.125] "-" Vector__XXX
 SG_ TAS_sprungMassEstimate : 46|5@1+ (64,1800) [1800|3784] "kg" Vector__XXX
 SG_ TAS_anyDamperActive : 51|1@1+ (1,0) [0|1] "" Vector__XXX
 SG_ TAS_dampingStatesCounter : 52|4@1+ (1,0) [0|15] "" Vector__XXX
 SG_ TAS_dampingStatesChecksum : 56|8@1+ (1,0) [0|255] "" Vector__XXX

BO_ 1357 TAS_info: 8 TAS
 SG_ TAS_infoIndex M : 0|8@1+ (1,0) [0|255] "" Vector__XXX
 SG_ TAS_infoBuildType m10 : 8|8@1+ (1,0) [0|255] "" Vector__XXX
 SG_ TAS_infoBuildConfigId m10 : 16|16@1+ (1,0) [0|65535] "" Vector__XXX
 SG_ TAS_infoHardwareId m10 : 32|1@1+ (1,0) [0|1] "" Vector__XXX
 SG_ TAS_infoComponentId m10 : 48|16@1+ (1,0) [0|65535] "" Vector__XXX
 SG_ TAS_infoPcbaId m11 : 16|8@1+ (1,0) [0|255] "" Vector__XXX
 SG_ TAS_infoAssemblyId m11 : 24|8@1+ (1,0) [0|255] "" Vector__XXX
 SG_ TAS_infoUsageId m11 : 32|16@1+ (1,0) [0|65535] "" Vector__XXX
 SG_ TAS_infoSubUsageId m11 : 48|16@1+ (1,0) [0|65535] "" Vector__XXX
 SG_ TAS_infoAppCrc m13 : 32|32@1+ (1,0) [0|4294967295] "" Vector__XXX
 SG_ TAS_infoAppGitHash m17 : 8|56@1+ (1,0) [0|7.20575940379e+16] "" Vector__XXX
 SG_ TAS_infoBootGitHash m18 : 8|56@1+ (1,0) [0|7.20575940379e+16] "" Vector__XXX
 SG_ TAS_infoPlatformType m19 : 8|8@1+ (1,0) [0|255] "" Vector__XXX
 SG_ TAS_infoMajorVersion m19 : 16|8@1+ (1,0) [0|255] "" Vector__XXX
 SG_ TAS_infoBranchOrigin m19 : 24|8@1+ (1,0) [0|255] "" Vector__XXX
 SG_ TAS_infoMaturity m19 : 32|8@1+ (1,0) [0|255] "" Vector__XXX
 SG_ TAS_infoHardwareRevision m19 : 40|8@1+ (1,0) [0|255] "" Vector__XXX

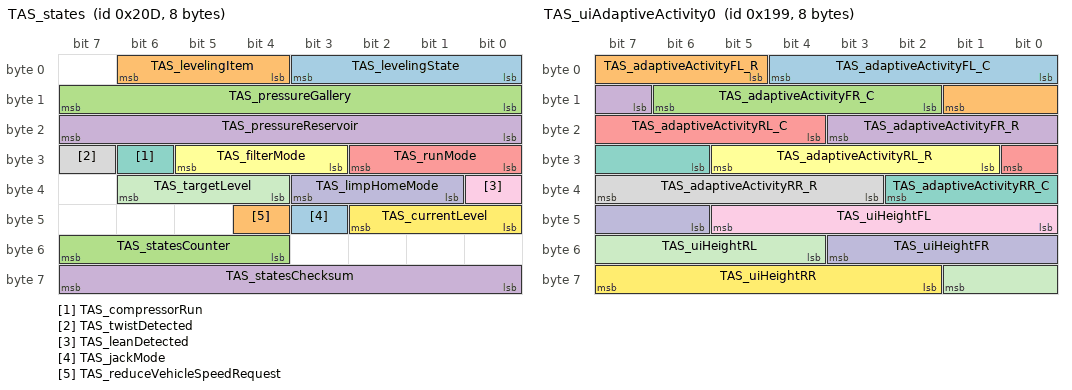
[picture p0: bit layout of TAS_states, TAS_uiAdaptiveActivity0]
BO_ 525 TAS_states: 8 TAS
 SG_ TAS_levelingState : 0|4@1+ (1,0) [0|15] "" Vector__XXX
 SG_ TAS_levelingItem : 4|3@1+ (1,0) [0|7] "" Vector__XXX
 SG_ TAS_pressureGallery : 8|8@1+ (0.1,0) [0|25.5] "bara" Vector__XXX
 SG_ TAS_pressureReservoir : 16|8@1+ (0.1,0) [0|25.5] "bara" Vector__XXX
 SG_ TAS_runMode : 24|3@1+ (1,0) [0|7] "" Vector__XXX
 SG_ TAS_filterMode : 27|3@1+ (1,0) [0|7] "" Vector__XXX
 SG_ TAS_compressorRun : 30|1@1+ (1,0) [0|1] "" Vector__XXX
 SG_ TAS_twistDetected : 31|1@1+ (1,0) [0|1] "" Vector__XXX
 SG_ TAS_leanDetected : 32|1@1+ (1,0) [0|1] "" Vector__XXX
 SG_ TAS_limpHomeMode : 33|3@1+ (1,0) [0|7] "" Vector__XXX
 SG_ TAS_targetLevel : 36|3@1+ (1,0) [0|7] "" Vector__XXX
 SG_ TAS_currentLevel : 40|3@1+ (1,0) [0|7] "" Vector__XXX
 SG_ TAS_jackMode : 43|1@1+ (1,0) [0|1] "" Vector__XXX
 SG_ TAS_reduceVehicleSpeedRequest : 44|1@1+ (1,0) [0|1] "" Vector__XXX
 SG_ TAS_statesCounter : 52|4@1+ (1,0) [0|15] "" Vector__XXX
 SG_ TAS_statesChecksum : 56|8@1+ (1,0) [0|255] "" Vector__XXX

BO_ 409 TAS_uiAdaptiveActivity0: 8 TAS
 SG_ TAS_adaptiveActivityFL_C : 0|5@1+ (0.04,0) [0|1] "-" Vector__XXX
 SG_ TAS_adaptiveActivityFL_R : 5|5@1+ (0.04,0) [0|1] "-" Vector__XXX
 SG_ TAS_adaptiveActivityFR_C : 10|5@1+ (0.04,0) [0|1] "-" Vector__XXX
 SG_ TAS_adaptiveActivityFR_R : 15|5@1+ (0.04,0) [0|1] "-" Vector__XXX
 SG_ TAS_adaptiveActivityRL_C : 20|5@1+ (0.04,0) [0|1] "-" Vector__XXX
 SG_ TAS_adaptiveActivityRL_R : 25|5@1+ (0.04,0) [0|1] "-" Vector__XXX
 SG_ TAS_adaptiveActivityRR_C : 30|5@1+ (0.04,0) [0|1] "-" Vector__XXX
 SG_ TAS_adaptiveActivityRR_R : 35|5@1+ (0.04,0) [0|1] "-" Vector__XXX
 SG_ TAS_uiHeightFL : 40|6@1+ (4,-128) [-128|124] "mm" Vector__XXX
 SG_ TAS_uiHeightFR : 46|6@1+ (4,-128) [-128|124] "mm" Vector__XXX
 SG_ TAS_uiHeightRL : 52|6@1+ (4,-128) [-128|124] "mm" Vector__XXX
 SG_ TAS_uiHeightRR : 58|6@1+ (4,-128) [-128|124] "mm" Vector__XXX

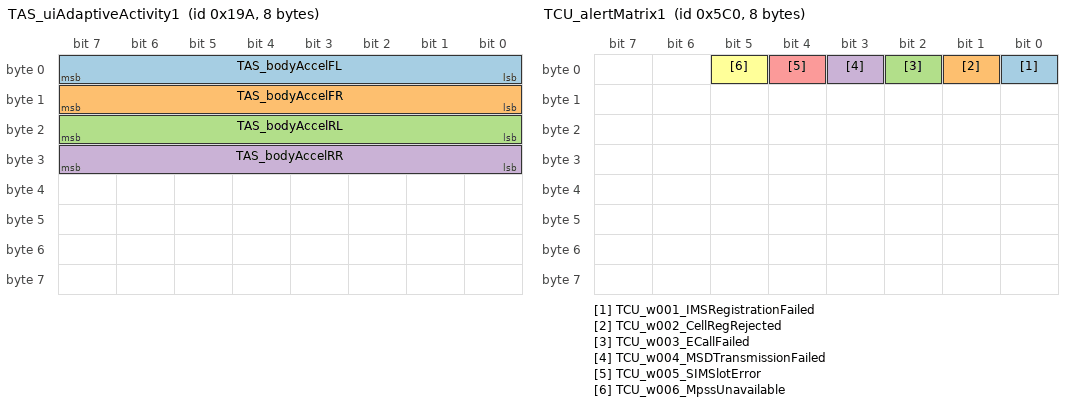
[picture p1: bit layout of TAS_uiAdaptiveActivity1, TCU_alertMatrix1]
BO_ 410 TAS_uiAdaptiveActivity1: 8 TAS
 SG_ TAS_bodyAccelFL : 0|8@1+ (0.05,-5) [-5|5] "g" Vector__XXX
 SG_ TAS_bodyAccelFR : 8|8@1+ (0.05,-5) [-5|5] "g" Vector__XXX
 SG_ TAS_bodyAccelRL : 16|8@1+ (0.05,-5) [-5|5] "g" Vector__XXX
 SG_ TAS_bodyAccelRR : 24|8@1+ (0.05,-5) [-5|5] "g" Vector__XXX

BO_ 538 TAS_uiControl: 8 TAS
 SG_ TAS_yellowWarningLamp : 0|1@1+ (1,0) [0|1] "" Vector__XXX
 SG_ TAS_redWarningLamp : 1|1@1+ (1,0) [0|1] "" Vector__XXX
 SG_ TAS_veryLowAllowed : 2|1@1+ (1,0) [0|1] "" Vector__XXX
 SG_ TAS_lowAllowed : 3|1@1+ (1,0) [0|1] "" Vector__XXX
 SG_ TAS_standardAllowed : 4|1@1+ (1,0) [0|1] "" Vector__XXX
 SG_ TAS_highAllowed : 5|1@1+ (1,0) [0|1] "" Vector__XXX
 SG_ TAS_veryHighAllowed : 6|1@1+ (1,0) [0|1] "" Vector__XXX
 SG_ TAS_extractAllowed : 7|1@1+ (1,0) [0|1] "" Vector__XXX
 SG_ TAS_showSpinner : 9|1@1+ (1,0) [0|1] "" Vector__XXX
 SG_ TAS_adaptiveRideModeOverride : 10|2@1+ (1,0) [0|3] "" Vector__XXX
 SG_ TAS_levelSelectEnabled : 12|1@1+ (1,0) [0|1] "" Vector__XXX
 SG_ TAS_jackModeToggleEnabled : 13|1@1+ (1,0) [0|1] "" Vector__XXX
 SG_ TAS_adaptiveRideSelectEnabled : 14|1@1+ (1,0) [0|1] "" Vector__XXX
 SG_ TAS_launchModeState : 16|3@1+ (1,0) [0|7] "" Vector__XXX
 SG_ TAS_restrictUpLevelingFalcons : 19|1@1+ (1,0) [0|1] "" Vector__XXX
 SG_ TAS_restrictUpLevelingTrunk : 20|1@1+ (1,0) [0|1] "" Vector__XXX
 SG_ TAS_restrictDownLevelingDoors : 21|1@1+ (1,0) [0|1] "" Vector__XXX
 SG_ TAS_restrictLevelingChargeCable : 22|1@1+ (1,0) [0|1] "" Vector__XXX
 SG_ TAS_restrictLevelingSystemCheck : 23|1@1+ (1,0) [0|1] "" Vector__XXX
 SG_ TAS_restrictLevelingTransport : 24|1@1+ (1,0) [0|1] "" Vector__XXX
 SG_ TAS_restrictLevelingShowroom : 25|1@1+ (1,0) [0|1] "" Vector__XXX
 SG_ TAS_uiControlCounter : 28|4@1+ (1,0) [0|15] "" Vector__XXX
 SG_ TAS_uiControlChecksum : 32|8@1+ (1,0) [0|255] "" Vector__XXX

BO_ 1410 TCU_alertLog: 8 TCU
 SG_ TCU_alertID M : 0|3@1+ (1,0) [0|7] "" Vector__XXX
 SG_ TCU_alertState : 15|1@1+ (1,0) [0|1] "" Vector__XXX
 SG_ TCU_w001_FailCode m1 : 16|32@1+ (1,0) [0|4294967295] "" Vector__XXX
 SG_ TCU_w002_RejCause m2 : 16|32@1+ (1,0) [0|4294967295] "" Vector__XXX
 SG_ TCU_w003_CallFailCode m3 : 16|32@1+ (1,0) [0|4294967295] "" Vector__XXX
 SG_ TCU_w004_MSDFailCode m4 : 16|32@1+ (1,0) [0|4294967295] "" Vector__XXX
 SG_ TCU_w006_Count m6 : 16|32@1+ (1,0) [0|4294967295] "" Vector__XXX

BO_ 1472 TCU_alertMatrix1: 8 TCU
 SG_ TCU_w001_IMSRegistrationFailed : 0|1@1+ (1,0) [0|1] "" Vector__XXX
 SG_ TCU_w002_CellRegRejected : 1|1@1+ (1,0) [0|1] "" Vector__XXX
 SG_ TCU_w003_ECallFailed : 2|1@1+ (1,0) [0|1] "" Vector__XXX
 SG_ TCU_w004_MSDTransmissionFailed : 3|1@1+ (1,0) [0|1] "" Vector__XXX
 SG_ TCU_w005_SIMSlotError : 4|1@1+ (1,0) [0|1] "" Vector__XXX
 SG_ TCU_w006_MpssUnavailable : 5|1@1+ (1,0) [0|1] "" Vector__XXX

BO_ 1409 TCU_log: 8 TCU
 SG_ TCU_logMux M : 0|32@1+ (1,0) [0|4294967295] "" Vector__XXX
 SG_ TCU_cpuTemp m0 : 32|32@1+ (1,0) [0|4294967295] "C" Vector__XXX
 SG_ TCU_cpuUsage m1 : 32|32@1+ (1,0) [0|4294967295] "%" Vector__XXX
 SG_ TCU_mdmCoreTemperature m2 : 32|32@1+ (1,0) [0|4294967295] "C" Vector__XXX
 SG_ TCU_availableMemory m3 : 32|32@1+ (1,0) [0|4294967295] "KB" Vector__XXX
 SG_ TCU_pwm m4 : 32|32@1+ (1,0) [0|4294967295] "" Vector__XXX
 SG_ TCU_pwmcap m5 : 32|32@1+ (1,0) [0|4294967295] "" Vector__XXX
 SG_ TCU_totalResumes m6 : 32|32@1+ (1,0) [0|4294967295] "" Vector__XXX
 SG_ TCU_mdmUplinkQueueSize m7 : 32|32@1+ (1,0) [0|4294967295] "bytes" Vector__XXX
 SG_ TCU_mdmRSRP m8 : 32|32@1- (1,0) [-2147483648|2147483647] "dBm" Vector__XXX
 SG_ TCU_mdmSINR m9 : 32|32@1- (1,0) [-2147483648|2147483647] "dBm" Vector__XXX
 SG_ TCU_mdmUplinkAllowedRate m10 : 32|32@1+ (1,0) [0|4294967295] "Kbps" Vector__XXX
 SG_ TCU_mdmUplinkAvgRage m11 : 32|32@1+ (1,0) [0|4294967295] "" Vector__XXX
 SG_ TCU_mdmServiceState m12 : 32|32@1+ (1,0) [0|4294967295] "" Vector__XXX
 SG_ TCU_mdmIMSStatus m13 : 32|32@1+ (1,0) [0|4294967295] "" Vector__XXX
 SG_ TCU_mdmSIMStatus m14 : 32|32@1+ (1,0) [0|4294967295] "" Vector__XXX
 SG_ TCU_mdmBusyActive m15 : 32|32@1+ (1,0) [0|4294967295] "" Vector__XXX

BO_ 1408 TCU_status: 8 TCU
 SG_ TCU_statusMux M : 0|32@1+ (1,0) [0|4294967295] "" Vector__XXX
 SG_ TCU_wakeUpReason m0 : 32|32@1+ (1,0) [0|4294967295] "" Vector__XXX
 SG_ TCU_tcuCmdId m1 : 32|1@1+ (1,0) [0|1] "" Vector__XXX
 SG_ TCU_goingToSleep m2 : 32|32@1+ (1,0) [0|4294967295] "" Vector__XXX

BO_ 879 TPMS_StatusC: 8 TPMS
 SG_ TPMS_c_globalHardWarning : 0|1@1+ (1,0) [0|1] "" Vector__XXX
 SG_ TPMS_c_globalSoftWarning : 1|1@1+ (1,0) [0|1] "" Vector__XXX
 SG_ TPMS_systemMalfunction : 2|1@1+ (1,0) [0|1] "" Vector__XXX
 SG_ TPMS_WA_version : 3|1@1+ (1,0) [0|1] "" Vector__XXX
 SG_ TPMS_globalDeltaPressure : 4|1@1+ (1,0) [0|1] "" Vector__XXX
 SG_ TPMS_newSensorLearnt : 5|3@1+ (1,0) [0|7] "" Vector__XXX
 SG_ TPMS_softWarningRR : 8|1@1+ (1,0) [0|1] "" Vector__XXX
 SG_ TPMS_hardWarningRR : 9|1@1+ (1,0) [0|1] "" Vector__XXX
 SG_ TPMS_softWarningRL : 10|1@1+ (1,0) [0|1] "" Vector__XXX
 SG_ TPMS_hardWarningRL : 11|1@1+ (1,0) [0|1] "" Vector__XXX
 SG_ TPMS_softWarningFR : 12|1@1+ (1,0) [0|1] "" Vector__XXX
 SG_ TPMS_hardWarningFR : 13|1@1+ (1,0) [0|1] "" Vector__XXX
 SG_ TPMS_softWarningFL : 14|1@1+ (1,0) [0|1] "" Vector__XXX
 SG_ TPMS_hardWarningFL : 15|1@1+ (1,0) [0|1] "" Vector__XXX
 SG_ TPMS_learningStatus : 16|2@1+ (1,0) [0|3] "" Vector__XXX
 SG_ TPMS_localisationStatus : 18|2@1+ (1,0) [0|3] "" Vector__XXX
 SG_ TPMS_deltaPressWarningFL : 20|1@1+ (1,0) [0|1] "" Vector__XXX
 SG_ TPMS_deltaPressWarningFR : 21|1@1+ (1,0) [0|1] "" Vector__XXX
 SG_ TPMS_deltaPressWarningRL : 22|1@1+ (1,0) [0|1] "" Vector__XXX
 SG_ TPMS_deltaPressWarningRR : 23|1@1+ (1,0) [0|1] "" Vector__XXX
 SG_ TPMS_sensorNoResponseFL : 24|1@1+ (1,0) [0|1] "" Vector__XXX
 SG_ TPMS_sensorNoResponseFR : 25|1@1+ (1,0) [0|1] "" Vector__XXX
 SG_ TPMS_sensorNoResponseRL : 26|1@1+ (1,0) [0|1] "" Vector__XXX
 SG_ TPMS_sensorNoResponseRR : 27|1@1+ (1,0) [0|1] "" Vector__XXX
 SG_ TPMS_sensorThermShutdownFL : 28|1@1+ (1,0) [0|1] "" Vector__XXX
 SG_ TPMS_sensorThermShutdownFR : 29|1@1+ (1,0) [0|1] "" Vector__XXX
 SG_ TPMS_sensorThermShutdownRL : 30|1@1+ (1,0) [0|1] "" Vector__XXX
 SG_ TPMS_sensorThermShutdownRR : 31|1@1+ (1,0) [0|1] "" Vector__XXX
 SG_ TPMS_sensorBatteryLowFL : 32|1@1+ (1,0) [0|1] "" Vector__XXX
 SG_ TPMS_sensorBatteryLowFR : 33|1@1+ (1,0) [0|1] "" Vector__XXX
 SG_ TPMS_sensorBatteryLowRL : 34|1@1+ (1,0) [0|1] "" Vector__XXX
 SG_ TPMS_sensorBatteryLowRR : 35|1@1+ (1,0) [0|1] "" Vector__XXX
 SG_ TPMS_sensorDefectiveFL : 36|1@1+ (1,0) [0|1] "" Vector__XXX
 SG_ TPMS_sensorDefectiveFR : 37|1@1+ (1,0) [0|1] "" Vector__XXX
 SG_ TPMS_sensorDefectiveRL : 38|1@1+ (1,0) [0|1] "" Vector__XXX
 SG_ TPMS_sensorDefectiveRR : 39|1@1+ (1,0) [0|1] "" Vector__XXX
 SG_ TPMS_ecuUnderVoltage : 40|1@1+ (1,0) [0|1] "" Vector__XXX
 SG_ TPMS_ecuOverVoltage : 41|1@1+ (1,0) [0|1] "" Vector__XXX
 SG_ TPMS_ecuRamRomNvMFail : 42|1@1+ (1,0) [0|1] "" Vector__XXX
 SG_ TPMS_rfReceiverFail : 43|1@1+ (1,0) [0|1] "" Vector__XXX
 SG_ TPMS_wheelPulseMissing : 44|1@1+ (1,0) [0|1] "" Vector__XXX
 SG_ TPMS_vehicleSpeedFail : 45|1@1+ (1,0) [0|1] "" Vector__XXX
 SG_ TPMS_externalTemperatureFail : 46|1@1+ (1,0) [0|1] "" Vector__XXX
 SG_ TPMS_eolNotCompleted : 47|1@1+ (1,0) [0|1] "" Vector__XXX
 SG_ TPMS_rcpFront : 48|8@1+ (0.025,0) [0|6.375] "bar" Vector__XXX
 SG_ TPMS_rcpRear : 56|8@1+ (0.025,0) [0|6.375] "bar" Vector__XXX

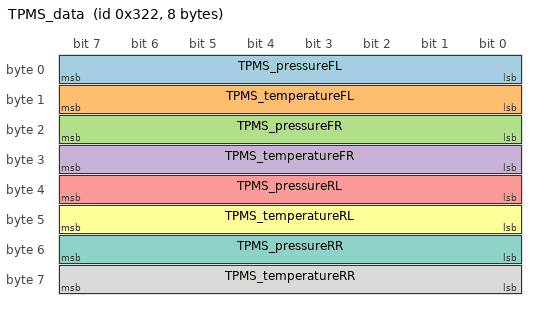
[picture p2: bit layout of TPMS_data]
BO_ 802 TPMS_data: 8 TPMS
 SG_ TPMS_pressureFL : 0|8@1+ (0.025,0) [0|6.375] "bar" Vector__XXX
 SG_ TPMS_temperatureFL : 8|8@1+ (1,-40) [-40|215] "degC" Vector__XXX
 SG_ TPMS_pressureFR : 16|8@1+ (0.025,0) [0|6.375] "bar" Vector__XXX
 SG_ TPMS_temperatureFR : 24|8@1+ (1,-40) [-40|215] "degC" Vector__XXX
 SG_ TPMS_pressureRL : 32|8@1+ (0.025,0) [0|6.375] "bar" Vector__XXX
 SG_ TPMS_temperatureRL : 40|8@1+ (1,-40) [-40|215] "degC" Vector__XXX
 SG_ TPMS_pressureRR : 48|8@1+ (0.025,0) [0|6.375] "bar" Vector__XXX
 SG_ TPMS_temperatureRR : 56|8@1+ (1,-40) [-40|215] "degC" Vector__XXX

BO_ 1519 TPMS_info: 8 TPMS
 SG_ TPMS_infoIndex M : 0|8@1+ (1,0) [0|255] "" Vector__XXX
 SG_ TPMS_infoComponentID m10 : 48|16@1+ (1,0) [0|65535] "" Vector__XXX
 SG_ TPMS_infoPcbaID m11 : 16|8@1+ (1,0) [0|255] "" Vector__XXX
 SG_ TPMS_infoAssemblyID m11 : 24|8@1+ (1,0) [0|255] "" Vector__XXX
 SG_ TPMS_infoUsageID m11 : 32|16@1+ (1,0) [0|65535] "" Vector__XXX
 SG_ TPMS_infoApplicationCRC m13 : 32|32@1+ (1,0) [0|4294967295] "" Vector__XXX
 SG_ TPMS_infoBootUdsProtoVersion m20 : 8|8@1+ (1,0) [0|255] "" Vector__XXX
 SG_ TPMS_infoBootloaderCRC m20 : 32|32@1+ (1,0) [0|4294967295] "" Vector__XXX

BO_ 1298 TRCM_alertLog: 8 TRCM
 SG_ TRCM_alertID M : 0|10@1+ (1,0) [0|1023] "" Vector__XXX
 SG_ TRCM_alertState : 15|1@1+ (1,0) [0|1] "" Vector__XXX
 SG_ TRCM_a015_NVMMMemOverflow m15 : 16|1@1+ (1,0) [0|1] "" Vector__XXX
 SG_ TRCM_a015_NVMMFilesystemError m15 : 17|1@1+ (1,0) [0|1] "" Vector__XXX
 SG_ TRCM_a015_NVMMRecordIDError m15 : 18|1@1+ (1,0) [0|1] "" Vector__XXX
 SG_ TRCM_a057_VEH_cpControl m57 : 16|1@1+ (1,0) [0|1] "" Vector__XXX
 SG_ TRCM_a059_voltageDrop m59 : 16|12@1+ (0.005443676,0) [0|22.29185322] "" Vector__XXX
 SG_ TRCM_a059_resistanceEstimate m59 : 28|12@1+ (0.00244,0) [0|9.9918] "" Vector__XXX
 SG_ TRCM_a059_current m59 : 40|12@1+ (0.05,0) [0|204.75] "" Vector__XXX
 SG_ TRCM_a063_switchChannel m63 : 16|8@1+ (1,0) [0|255] "" Vector__XXX
 SG_ TRCM_a063_switchType m63 : 24|8@1+ (1,0) [0|255] "" Vector__XXX
 SG_ TRCM_a063_ADCVoltage m63 : 32|8@1+ (0.025,0) [0|6.375] "" Vector__XXX
 SG_ TRCM_a063_disconnected m63 : 40|1@1+ (1,0) [0|1] "" Vector__XXX
 SG_ TRCM_a063_indeterminate m63 : 41|1@1+ (1,0) [0|1] "" Vector__XXX
 SG_ TRCM_a063_stuckActive m63 : 42|1@1+ (1,0) [0|1] "" Vector__XXX
 SG_ TRCM_a063_faulted m63 : 43|1@1+ (1,0) [0|1] "" Vector__XXX
 SG_ TRCM_a082_RIPC_epbPrivateState m82 : 16|1@1+ (1,0) [0|1] "" Vector__XXX
 SG_ TRCM_a082_RIPC_remoteHSD m82 : 17|1@1+ (1,0) [0|1] "" Vector__XXX
 SG_ TRCM_a082_RIPC_railStatus m82 : 18|1@1+ (1,0) [0|1] "" Vector__XXX
 SG_ TRCM_a082_RIPC_remoteMux m82 : 19|1@1+ (1,0) [0|1] "" Vector__XXX
 SG_ TRCM_a083_LIPC_epbPrivateState m83 : 16|1@1+ (1,0) [0|1] "" Vector__XXX
 SG_ TRCM_a083_LIPC_remoteHSD m83 : 17|1@1+ (1,0) [0|1] "" Vector__XXX
 SG_ TRCM_a083_LIPC_railStatus m83 : 18|1@1+ (1,0) [0|1] "" Vector__XXX
 SG_ TRCM_a083_LIPC_HSDFaults m83 : 19|1@1+ (1,0) [0|1] "" Vector__XXX
 SG_ TRCM_a084_CH_StatusC m84 : 16|1@1+ (1,0) [0|1] "" Vector__XXX
 SG_ TRCM_a085_PARTY_buttonStatus m85 : 16|1@1+ (1,0) [0|1] "" Vector__XXX
 SG_ TRCM_a086_VEH_LVBMS_statusHigh m86 : 16|1@1+ (1,0) [0|1] "" Vector__XXX
 SG_ TRCM_a086_VEH_LVBMS_statusLow m86 : 17|1@1+ (1,0) [0|1] "" Vector__XXX
 SG_ TRCM_a086_VEH_status m86 : 18|1@1+ (1,0) [0|1] "" Vector__XXX
 SG_ TRCM_a086_VEH_12VBatteryStatus m86 : 19|1@1+ (1,0) [0|1] "" Vector__XXX
 SG_ TRCM_a086_VEH_LVPowerState m86 : 20|1@1+ (1,0) [0|1] "" Vector__XXX
 SG_ TRCM_a086_VEH_lightStatus m86 : 21|1@1+ (1,0) [0|1] "" Vector__XXX
 SG_ TRCM_a086_VEH_systemStatus m86 : 22|1@1+ (1,0) [0|1] "" Vector__XXX
 SG_ TRCM_a086_VEH_thermalStatus m86 : 23|1@1+ (1,0) [0|1] "" Vector__XXX
 SG_ TRCM_a086_VEH_vehNm m86 : 24|1@1+ (1,0) [0|1] "" Vector__XXX
 SG_ TRCM_a087_VEH_temperature m87 : 16|1@1+ (1,0) [0|1] "" Vector__XXX
 SG_ TRCM_a087_VEH_thermalControl m87 : 17|1@1+ (1,0) [0|1] "" Vector__XXX
 SG_ TRCM_a087_VEH_torque m87 : 18|1@1+ (1,0) [0|1] "" Vector__XXX
 SG_ TRCM_a087_VEH_status m87 : 19|1@1+ (1,0) [0|1] "" Vector__XXX
 SG_ TRCM_a087_PARTY_torque m87 : 20|1@1+ (1,0) [0|1] "" Vector__XXX
 SG_ TRCM_a087_PARTY_status m87 : 21|1@1+ (1,0) [0|1] "" Vector__XXX
 SG_ TRCM_a087_PARTY_temperature m87 : 22|1@1+ (1,0) [0|1] "" Vector__XXX
 SG_ TRCM_a087_PARTY_thermalControl m87 : 23|1@1+ (1,0) [0|1] "" Vector__XXX
 SG_ TRCM_a088_VEH_temperature m88 : 16|1@1+ (1,0) [0|1] "" Vector__XXX
 SG_ TRCM_a088_VEH_thermalControl m88 : 17|1@1+ (1,0) [0|1] "" Vector__XXX
 SG_ TRCM_a088_VEH_torque m88 : 18|1@1+ (1,0) [0|1] "" Vector__XXX
 SG_ TRCM_a088_VEH_status m88 : 19|1@1+ (1,0) [0|1] "" Vector__XXX
 SG_ TRCM_a088_PARTY_torque m88 : 20|1@1+ (1,0) [0|1] "" Vector__XXX
 SG_ TRCM_a088_PARTY_status m88 : 21|1@1+ (1,0) [0|1] "" Vector__XXX
 SG_ TRCM_a088_PARTY_temperature m88 : 22|1@1+ (1,0) [0|1] "" Vector__XXX
 SG_ TRCM_a088_PARTY_thermalControl m88 : 23|1@1+ (1,0) [0|1] "" Vector__XXX
 SG_ TRCM_a089_PARTY_party1 m89 : 16|1@1+ (1,0) [0|1] "" Vector__XXX
 SG_ TRCM_a089_PARTY_status m89 : 17|1@1+ (1,0) [0|1] "" Vector__XXX
 SG_ TRCM_a089_VEH_status m89 : 18|1@1+ (1,0) [0|1] "" Vector__XXX
 SG_ TRCM_a089_BDY_party1 m89 : 19|1@1+ (1,0) [0|1] "" Vector__XXX
 SG_ TRCM_a089_BDY_status m89 : 20|1@1+ (1,0) [0|1] "" Vector__XXX
 SG_ TRCM_a089_CH_status m89 : 21|1@1+ (1,0) [0|1] "" Vector__XXX
 SG_ TRCM_a089_CH_party1 m89 : 22|1@1+ (1,0) [0|1] "" Vector__XXX
 SG_ TRCM_a089_CH_party3 m89 : 23|1@1+ (1,0) [0|1] "" Vector__XXX
 SG_ TRCM_a089_VEH_party1 m89 : 24|1@1+ (1,0) [0|1] "" Vector__XXX
 SG_ TRCM_a089_VEH_party3 m89 : 25|1@1+ (1,0) [0|1] "" Vector__XXX
 SG_ TRCM_a091_VEH_faultsAndExtras m91 : 16|1@1+ (1,0) [0|1] "" Vector__XXX
 SG_ TRCM_a091_VEH_info m91 : 17|1@1+ (1,0) [0|1] "" Vector__XXX
 SG_ TRCM_a091_VEH_state m91 : 18|1@1+ (1,0) [0|1] "" Vector__XXX
 SG_ TRCM_a092_VEH_restraintStatus m92 : 16|1@1+ (1,0) [0|1] "" Vector__XXX
 SG_ TRCM_a092_VEH_switchStatus m92 : 17|1@1+ (1,0) [0|1] "" Vector__XXX
 SG_ TRCM_a092_VEH_seatStatus2 m92 : 18|1@1+ (1,0) [0|1] "" Vector__XXX
 SG_ TRCM_a092_VEH_vehNm m92 : 19|1@1+ (1,0) [0|1] "" Vector__XXX
 SG_ TRCM_a093_VEH_restraintStatus m93 : 16|1@1+ (1,0) [0|1] "" Vector__XXX
 SG_ TRCM_a093_VEH_switchStatus m93 : 17|1@1+ (1,0) [0|1] "" Vector__XXX
 SG_ TRCM_a093_VEH_seatStatus2 m93 : 18|1@1+ (1,0) [0|1] "" Vector__XXX
 SG_ TRCM_a093_VEH_vehNm m93 : 19|1@1+ (1,0) [0|1] "" Vector__XXX
 SG_ TRCM_a094_VEH_sysStatus m94 : 16|1@1+ (1,0) [0|1] "" Vector__XXX
 SG_ TRCM_a094_PARTY_sysStatus m94 : 17|1@1+ (1,0) [0|1] "" Vector__XXX
 SG_ TRCM_a095_PT_ptNm m95 : 16|1@1+ (1,0) [0|1] "" Vector__XXX
 SG_ TRCM_a095_PT_status m95 : 17|1@1+ (1,0) [0|1] "" Vector__XXX
 SG_ TRCM_a096_VEH_status m96 : 16|1@1+ (1,0) [0|1] "" Vector__XXX
 SG_ TRCM_a096_CH_status m96 : 17|1@1+ (1,0) [0|1] "" Vector__XXX
 SG_ TRCM_a098_CH_torque m98 : 16|1@1+ (1,0) [0|1] "" Vector__XXX
 SG_ TRCM_a098_VEH_hvStatus m98 : 17|1@1+ (1,0) [0|1] "" Vector__XXX
 SG_ TRCM_a098_VEH_status m98 : 18|1@1+ (1,0) [0|1] "" Vector__XXX
 SG_ TRCM_a098_VEH_thermalControl m98 : 19|1@1+ (1,0) [0|1] "" Vector__XXX
 SG_ TRCM_a098_VEH_temperature m98 : 20|1@1+ (1,0) [0|1] "" Vector__XXX
 SG_ TRCM_a098_VEH_torque m98 : 21|1@1+ (1,0) [0|1] "" Vector__XXX
 SG_ TRCM_a098_PARTY_status m98 : 22|1@1+ (1,0) [0|1] "" Vector__XXX
 SG_ TRCM_a098_PARTY_temperature m98 : 23|1@1+ (1,0) [0|1] "" Vector__XXX
 SG_ TRCM_a098_PARTY_thermalControl m98 : 24|1@1+ (1,0) [0|1] "" Vector__XXX
 SG_ TRCM_a098_PARTY_torque m98 : 25|1@1+ (1,0) [0|1] "" Vector__XXX
 SG_ TRCM_a098_PT_thermalControl m98 : 26|1@1+ (1,0) [0|1] "" Vector__XXX
 SG_ TRCM_a098_PT_temperature m98 : 27|1@1+ (1,0) [0|1] "" Vector__XXX
 SG_ TRCM_a099_VEH_oocStatus m99 : 16|1@1+ (1,0) [0|1] "" Vector__XXX
 SG_ TRCM_a100_VEH m100 : 16|1@1+ (1,0) [0|1] "" Vector__XXX
 SG_ TRCM_a100_PARTY m100 : 17|1@1+ (1,0) [0|1] "" Vector__XXX
 SG_ TRCM_a100_PT m100 : 18|1@1+ (1,0) [0|1] "" Vector__XXX
 SG_ TRCM_a100_CH m100 : 19|1@1+ (1,0) [0|1] "" Vector__XXX
 SG_ TRCM_a100_OBD m100 : 20|1@1+ (1,0) [0|1] "" Vector__XXX
 SG_ TRCM_a101_VEH_state m101 : 16|1@1+ (1,0) [0|1] "" Vector__XXX
 SG_ TRCM_a101_PARTY_locState m101 : 17|1@1+ (1,0) [0|1] "" Vector__XXX
 SG_ TRCM_a101_LIPC_externalWatchdogH m101 : 18|1@1+ (1,0) [0|1] "" Vector__XXX
 SG_ TRCM_a101_VEH_locState m101 : 19|1@1+ (1,0) [0|1] "" Vector__XXX
 SG_ TRCM_a101_BDY_locState m101 : 20|1@1+ (1,0) [0|1] "" Vector__XXX
 SG_ TRCM_a102_VEH_faultsAndExtras m102 : 16|1@1+ (1,0) [0|1] "" Vector__XXX
 SG_ TRCM_a102_VEH_feedbackStatus m102 : 17|1@1+ (1,0) [0|1] "" Vector__XXX
 SG_ TRCM_a102_VEH_sensorStatus m102 : 18|1@1+ (1,0) [0|1] "" Vector__XXX
 SG_ TRCM_a102_VEH_rods m102 : 19|1@1+ (1,0) [0|1] "" Vector__XXX
 SG_ TRCM_a103_VEH_hvsNm m103 : 16|1@1+ (1,0) [0|1] "" Vector__XXX
 SG_ TRCM_a103_VEH_vehNm m103 : 17|1@1+ (1,0) [0|1] "" Vector__XXX
 SG_ TRCM_a103_VEH_status m103 : 18|1@1+ (1,0) [0|1] "" Vector__XXX
 SG_ TRCM_a103_PT_ptNm m103 : 19|1@1+ (1,0) [0|1] "" Vector__XXX
 SG_ TRCM_a103_PT_status m103 : 20|1@1+ (1,0) [0|1] "" Vector__XXX
 SG_ TRCM_a103_VEH_evseStatus m103 : 21|1@1+ (1,0) [0|1] "" Vector__XXX
 SG_ TRCM_a105_VEH_states m105 : 16|1@1+ (1,0) [0|1] "" Vector__XXX
 SG_ TRCM_a105_VEH_chNm m105 : 17|1@1+ (1,0) [0|1] "" Vector__XXX
 SG_ TRCM_a105_VEH_dampingStates m105 : 18|1@1+ (1,0) [0|1] "" Vector__XXX
 SG_ TRCM_a106_VEH_dcdcStatus m106 : 16|1@1+ (1,0) [0|1] "" Vector__XXX
 SG_ TRCM_a106_VEH_thermalControl m106 : 17|1@1+ (1,0) [0|1] "" Vector__XXX
 SG_ TRCM_a106_VEH_thermalInterface m106 : 18|1@1+ (1,0) [0|1] "" Vector__XXX
 SG_ TRCM_a106_VEH_dcdcRailStatus m106 : 19|1@1+ (1,0) [0|1] "" Vector__XXX
 SG_ TRCM_a106_CH_dcdcRailStatus m106 : 20|1@1+ (1,0) [0|1] "" Vector__XXX
 SG_ TRCM_a106_CH_alertMatrix m106 : 21|1@1+ (1,0) [0|1] "" Vector__XXX
 SG_ TRCM_a107_VEH_hvsNm m107 : 16|1@1+ (1,0) [0|1] "" Vector__XXX
 SG_ TRCM_a107_VEH_vehNm m107 : 17|1@1+ (1,0) [0|1] "" Vector__XXX
 SG_ TRCM_a107_VEH_status m107 : 18|1@1+ (1,0) [0|1] "" Vector__XXX
 SG_ TRCM_a107_VEH_thermalStatus m107 : 19|1@1+ (1,0) [0|1] "" Vector__XXX
 SG_ TRCM_a107_VEH_thermalStatus2 m107 : 20|1@1+ (1,0) [0|1] "" Vector__XXX
 SG_ TRCM_a107_VEH_bmbMinMax m107 : 21|1@1+ (1,0) [0|1] "" Vector__XXX
 SG_ TRCM_a107_VEH_powerAvailable m107 : 22|1@1+ (1,0) [0|1] "" Vector__XXX
 SG_ TRCM_a107_PT_ptNm m107 : 23|1@1+ (1,0) [0|1] "" Vector__XXX
 SG_ TRCM_a107_PT_status m107 : 24|1@1+ (1,0) [0|1] "" Vector__XXX
 SG_ TRCM_a107_PT_thermalStatus m107 : 25|1@1+ (1,0) [0|1] "" Vector__XXX
 SG_ TRCM_a107_PT_socStatus m107 : 26|1@1+ (1,0) [0|1] "" Vector__XXX
 SG_ TRCM_a107_VEH_socStatus m107 : 27|1@1+ (1,0) [0|1] "" Vector__XXX
 SG_ TRCM_a107_VEH_packConfig m107 : 28|1@1+ (1,0) [0|1] "" Vector__XXX
 SG_ TRCM_a107_VEH_energyStatus m107 : 29|1@1+ (1,0) [0|1] "" Vector__XXX
 SG_ TRCM_a107_VEH_chargeInfo m107 : 30|1@1+ (1,0) [0|1] "" Vector__XXX
 SG_ TRCM_a108_VEH_hvStatus m108 : 16|1@1+ (1,0) [0|1] "" Vector__XXX
 SG_ TRCM_a108_VEH_temperature m108 : 17|1@1+ (1,0) [0|1] "" Vector__XXX
 SG_ TRCM_a108_VEH_thermalControl m108 : 18|1@1+ (1,0) [0|1] "" Vector__XXX
 SG_ TRCM_a108_VEH_torque m108 : 19|1@1+ (1,0) [0|1] "" Vector__XXX
 SG_ TRCM_a108_VEH_status m108 : 20|1@1+ (1,0) [0|1] "" Vector__XXX
 SG_ TRCM_a108_PARTY_torque m108 : 21|1@1+ (1,0) [0|1] "" Vector__XXX
 SG_ TRCM_a108_PARTY_status m108 : 22|1@1+ (1,0) [0|1] "" Vector__XXX
 SG_ TRCM_a108_PARTY_temperature m108 : 23|1@1+ (1,0) [0|1] "" Vector__XXX
 SG_ TRCM_a108_PARTY_thermalControl m108 : 24|1@1+ (1,0) [0|1] "" Vector__XXX
 SG_ TRCM_a108_PT_temperature m108 : 25|1@1+ (1,0) [0|1] "" Vector__XXX
 SG_ TRCM_a108_PT_thermalControl m108 : 26|1@1+ (1,0) [0|1] "" Vector__XXX
 SG_ TRCM_a109_PARTY_status m109 : 16|1@1+ (1,0) [0|1] "" Vector__XXX
 SG_ TRCM_a109_PARTY_inertial2 m109 : 17|1@1+ (1,0) [0|1] "" Vector__XXX
 SG_ TRCM_a109_PARTY_nearDeploy m109 : 18|1@1+ (1,0) [0|1] "" Vector__XXX
 SG_ TRCM_a109_PARTY_collision m109 : 19|1@1+ (1,0) [0|1] "" Vector__XXX
 SG_ TRCM_a109_VEH_status m109 : 20|1@1+ (1,0) [0|1] "" Vector__XXX
 SG_ TRCM_a109_VEH_imuOffsets m109 : 21|1@1+ (1,0) [0|1] "" Vector__XXX
 SG_ TRCM_a109_PARTY_inertial1 m109 : 22|1@1+ (1,0) [0|1] "" Vector__XXX
 SG_ TRCM_a109_BDY_imuOffsets m109 : 23|1@1+ (1,0) [0|1] "" Vector__XXX
 SG_ TRCM_a109_BDY_inertial1 m109 : 24|1@1+ (1,0) [0|1] "" Vector__XXX
 SG_ TRCM_a109_BDY_inertial2 m109 : 25|1@1+ (1,0) [0|1] "" Vector__XXX
 SG_ TRCM_a109_BDY_status m109 : 26|1@1+ (1,0) [0|1] "" Vector__XXX
 SG_ TRCM_a109_VEH_inertial1 m109 : 27|1@1+ (1,0) [0|1] "" Vector__XXX
 SG_ TRCM_a109_VEH_inertial2 m109 : 28|1@1+ (1,0) [0|1] "" Vector__XXX
 SG_ TRCM_a109_CH_inertial1 m109 : 29|1@1+ (1,0) [0|1] "" Vector__XXX
 SG_ TRCM_a109_CH_inertial2 m109 : 30|1@1+ (1,0) [0|1] "" Vector__XXX
 SG_ TRCM_a109_CH_status m109 : 31|1@1+ (1,0) [0|1] "" Vector__XXX
 SG_ TRCM_a110_VEH_carState m110 : 16|1@1+ (1,0) [0|1] "" Vector__XXX
 SG_ TRCM_a110_VEH_carConfig m110 : 17|1@1+ (1,0) [0|1] "" Vector__XXX
 SG_ TRCM_a110_VEH_time m110 : 18|1@1+ (1,0) [0|1] "" Vector__XXX
 SG_ TRCM_a110_VEH_updateStatus m110 : 19|1@1+ (1,0) [0|1] "" Vector__XXX
 SG_ TRCM_a110_VEH_vehNm m110 : 20|1@1+ (1,0) [0|1] "" Vector__XXX
 SG_ TRCM_a110_VEH_mismatchFault m110 : 21|1@1+ (1,0) [0|1] "" Vector__XXX
 SG_ TRCM_a110_VEH_vin m110 : 22|1@1+ (1,0) [0|1] "" Vector__XXX
 SG_ TRCM_a110_VEH_bmpDebug m110 : 23|1@1+ (1,0) [0|1] "" Vector__XXX
 SG_ TRCM_a110_VEH_gearControl m110 : 24|1@1+ (1,0) [0|1] "" Vector__XXX
 SG_ TRCM_a110_VEH_canLogAvailability m110 : 25|1@1+ (1,0) [0|1] "" Vector__XXX
 SG_ TRCM_a110_CH_airbagCutoffStatus m110 : 26|1@1+ (1,0) [0|1] "" Vector__XXX
 SG_ TRCM_a110_CH_carConfig m110 : 27|1@1+ (1,0) [0|1] "" Vector__XXX
 SG_ TRCM_a110_CH_carState m110 : 28|1@1+ (1,0) [0|1] "" Vector__XXX
 SG_ TRCM_a110_CH_vin m110 : 29|1@1+ (1,0) [0|1] "" Vector__XXX
 SG_ TRCM_a110_CH_chNm m110 : 30|1@1+ (1,0) [0|1] "" Vector__XXX
 SG_ TRCM_a110_CH_epochTimeGtw m110 : 31|1@1+ (1,0) [0|1] "" Vector__XXX
 SG_ TRCM_a111_VEH_internalStatus m111 : 16|1@1+ (1,0) [0|1] "" Vector__XXX
 SG_ TRCM_a111_VEH_status m111 : 17|1@1+ (1,0) [0|1] "" Vector__XXX
 SG_ TRCM_a111_VEH_vehNm m111 : 18|1@1+ (1,0) [0|1] "" Vector__XXX
 SG_ TRCM_a111_RIPC_LVPowerState m111 : 19|1@1+ (1,0) [0|1] "" Vector__XXX
 SG_ TRCM_a111_RIPC_epbPrivateState m111 : 20|1@1+ (1,0) [0|1] "" Vector__XXX
 SG_ TRCM_a111_RIPC_railStatus m111 : 21|1@1+ (1,0) [0|1] "" Vector__XXX
 SG_ TRCM_a111_RIPC_remoteADC m111 : 22|1@1+ (1,0) [0|1] "" Vector__XXX
 SG_ TRCM_a111_RIPC_switchStatus m111 : 23|1@1+ (1,0) [0|1] "" Vector__XXX
 SG_ TRCM_a111_VEH_LVPowerState m111 : 24|1@1+ (1,0) [0|1] "" Vector__XXX
 SG_ TRCM_a111_VEH_seatStatus m111 : 25|1@1+ (1,0) [0|1] "" Vector__XXX
 SG_ TRCM_a111_PARTY_status m111 : 26|1@1+ (1,0) [0|1] "" Vector__XXX
 SG_ TRCM_a111_CH_status m111 : 27|1@1+ (1,0) [0|1] "" Vector__XXX
 SG_ TRCM_a112_VEH_internalStatus m112 : 16|1@1+ (1,0) [0|1] "" Vector__XXX
 SG_ TRCM_a112_VEH_status m112 : 17|1@1+ (1,0) [0|1] "" Vector__XXX
 SG_ TRCM_a112_VEH_vehNm m112 : 18|1@1+ (1,0) [0|1] "" Vector__XXX
 SG_ TRCM_a112_LIPC_LVPowerState m112 : 19|1@1+ (1,0) [0|1] "" Vector__XXX
 SG_ TRCM_a112_LIPC_epbPrivateState m112 : 20|1@1+ (1,0) [0|1] "" Vector__XXX
 SG_ TRCM_a112_LIPC_railStatus m112 : 21|1@1+ (1,0) [0|1] "" Vector__XXX
 SG_ TRCM_a112_LIPC_remoteADC m112 : 22|1@1+ (1,0) [0|1] "" Vector__XXX
 SG_ TRCM_a112_LIPC_switchStatus m112 : 23|1@1+ (1,0) [0|1] "" Vector__XXX
 SG_ TRCM_a112_VEH_LVPowerState m112 : 24|1@1+ (1,0) [0|1] "" Vector__XXX
 SG_ TRCM_a112_PARTY_status m112 : 25|1@1+ (1,0) [0|1] "" Vector__XXX
 SG_ TRCM_a112_CH_status m112 : 26|1@1+ (1,0) [0|1] "" Vector__XXX
 SG_ TRCM_a114_PARTY_status m114 : 16|1@1+ (1,0) [0|1] "" Vector__XXX
 SG_ TRCM_a114_PARTY_wheelSpeeds m114 : 17|1@1+ (1,0) [0|1] "" Vector__XXX
 SG_ TRCM_a114_VEH_wheelSpeeds m114 : 18|1@1+ (1,0) [0|1] "" Vector__XXX
 SG_ TRCM_a114_CH_wheelSpeeds m114 : 19|1@1+ (1,0) [0|1] "" Vector__XXX
 SG_ TRCM_a114_PARTY_party3 m114 : 20|1@1+ (1,0) [0|1] "" Vector__XXX
 SG_ TRCM_a114_VEH_party3 m114 : 21|1@1+ (1,0) [0|1] "" Vector__XXX
 SG_ TRCM_a114_VEH_status m114 : 22|1@1+ (1,0) [0|1] "" Vector__XXX
 SG_ TRCM_a114_PARTY_wheelRotation m114 : 23|1@1+ (1,0) [0|1] "" Vector__XXX
 SG_ TRCM_a114_CH_wheelRotation m114 : 24|1@1+ (1,0) [0|1] "" Vector__XXX
 SG_ TRCM_a114_VEH_wheelRotation m114 : 25|1@1+ (1,0) [0|1] "" Vector__XXX
 SG_ TRCM_a114_PARTY_brakeTorque m114 : 26|1@1+ (1,0) [0|1] "" Vector__XXX
 SG_ TRCM_a114_PARTY_offsets m114 : 27|1@1+ (1,0) [0|1] "" Vector__XXX
 SG_ TRCM_a114_BDY_offsets m114 : 28|1@1+ (1,0) [0|1] "" Vector__XXX
 SG_ TRCM_a114_BDY_party3 m114 : 29|1@1+ (1,0) [0|1] "" Vector__XXX
 SG_ TRCM_a114_BDY_status m114 : 30|1@1+ (1,0) [0|1] "" Vector__XXX
 SG_ TRCM_a114_BDY_wheelRotation m114 : 31|1@1+ (1,0) [0|1] "" Vector__XXX
 SG_ TRCM_a114_BDY_wheelSpeeds m114 : 32|1@1+ (1,0) [0|1] "" Vector__XXX
 SG_ TRCM_a114_CH_party1 m114 : 33|1@1+ (1,0) [0|1] "" Vector__XXX
 SG_ TRCM_a114_CH_party3 m114 : 34|1@1+ (1,0) [0|1] "" Vector__XXX
 SG_ TRCM_a114_CH_status m114 : 35|1@1+ (1,0) [0|1] "" Vector__XXX
 SG_ TRCM_a115_VEH_vehNm m115 : 16|1@1+ (1,0) [0|1] "" Vector__XXX
 SG_ TRCM_a115_VEH_authentication m115 : 17|1@1+ (1,0) [0|1] "" Vector__XXX
 SG_ TRCM_a115_VEH_BLEResetRequest m115 : 18|1@1+ (1,0) [0|1] "" Vector__XXX
 SG_ TRCM_a115_VEH_requests m115 : 19|1@1+ (1,0) [0|1] "" Vector__XXX
 SG_ TRCM_a115_VEH_requests2 m115 : 20|1@1+ (1,0) [0|1] "" Vector__XXX
 SG_ TRCM_a115_REM_authentication m115 : 21|1@1+ (1,0) [0|1] "" Vector__XXX
 SG_ TRCM_a115_UI_corianderVehicleCon m115 : 22|1@1+ (1,0) [0|1] "" Vector__XXX
 SG_ TRCM_a115_CH_TPMSDisplay m115 : 23|1@1+ (1,0) [0|1] "" Vector__XXX
 SG_ TRCM_a116_PARTY_epbmStatus m116 : 16|1@1+ (1,0) [0|1] "" Vector__XXX
 SG_ TRCM_a116_VEH_vehNm m116 : 17|1@1+ (1,0) [0|1] "" Vector__XXX
 SG_ TRCM_a116_VEH_hvacRequest m116 : 18|1@1+ (1,0) [0|1] "" Vector__XXX
 SG_ TRCM_a116_VEH_hvacStatus m116 : 19|1@1+ (1,0) [0|1] "" Vector__XXX
 SG_ TRCM_a116_VEH_LVPowerState m116 : 20|1@1+ (1,0) [0|1] "" Vector__XXX
 SG_ TRCM_a116_VEH_lightStatus m116 : 21|1@1+ (1,0) [0|1] "" Vector__XXX
 SG_ TRCM_a116_VEH_seatStatus m116 : 22|1@1+ (1,0) [0|1] "" Vector__XXX
 SG_ TRCM_a116_VEH_thsStatus m116 : 23|1@1+ (1,0) [0|1] "" Vector__XXX
 SG_ TRCM_a116_VEH_doorStatus m116 : 24|1@1+ (1,0) [0|1] "" Vector__XXX
 SG_ TRCM_a116_VEH_seatHeatStatus m116 : 25|1@1+ (1,0) [0|1] "" Vector__XXX
 SG_ TRCM_a116_VEH_restraintStatus m116 : 26|1@1+ (1,0) [0|1] "" Vector__XXX
 SG_ TRCM_a116_VEH_switchStatus m116 : 27|1@1+ (1,0) [0|1] "" Vector__XXX
 SG_ TRCM_a116_VEH_logging1Hz m116 : 28|1@1+ (1,0) [0|1] "" Vector__XXX
 SG_ TRCM_a116_VEH_seatStatus2 m116 : 29|1@1+ (1,0) [0|1] "" Vector__XXX
 SG_ TRCM_a116_VEH_status m116 : 30|1@1+ (1,0) [0|1] "" Vector__XXX
 SG_ TRCM_a116_VEH_thermalCommand m116 : 31|1@1+ (1,0) [0|1] "" Vector__XXX
 SG_ TRCM_a116_VEH_windowStatus m116 : 32|1@1+ (1,0) [0|1] "" Vector__XXX
 SG_ TRCM_a116_PARTY_restraintStatus m116 : 33|1@1+ (1,0) [0|1] "" Vector__XXX
 SG_ TRCM_a116_PARTY_doorStatus m116 : 34|1@1+ (1,0) [0|1] "" Vector__XXX
 SG_ TRCM_a116_BDY_epbmStatus m116 : 35|1@1+ (1,0) [0|1] "" Vector__XXX
 SG_ TRCM_a116_BDY_restraintStatus m116 : 36|1@1+ (1,0) [0|1] "" Vector__XXX
 SG_ TRCM_a117_BDY_epbmStatus m117 : 16|1@1+ (1,0) [0|1] "" Vector__XXX
 SG_ TRCM_a117_BDY_restraintStatus m117 : 17|1@1+ (1,0) [0|1] "" Vector__XXX
 SG_ TRCM_a117_VEH_prndStatus m117 : 18|1@1+ (1,0) [0|1] "" Vector__XXX
 SG_ TRCM_a117_PARTY_epbmStatus m117 : 19|1@1+ (1,0) [0|1] "" Vector__XXX
 SG_ TRCM_a117_VEH_vehNm m117 : 20|1@1+ (1,0) [0|1] "" Vector__XXX
 SG_ TRCM_a117_VEH_hvacBlowerFdb m117 : 21|1@1+ (1,0) [0|1] "" Vector__XXX
 SG_ TRCM_a117_VEH_LVPowerState m117 : 22|1@1+ (1,0) [0|1] "" Vector__XXX
 SG_ TRCM_a117_VEH_restraintStatus m117 : 23|1@1+ (1,0) [0|1] "" Vector__XXX
 SG_ TRCM_a117_VEH_lightStatus m117 : 24|1@1+ (1,0) [0|1] "" Vector__XXX
 SG_ TRCM_a117_VEH_seatStatus m117 : 25|1@1+ (1,0) [0|1] "" Vector__XXX
 SG_ TRCM_a117_BDY_falconSwitchStatus m117 : 26|1@1+ (1,0) [0|1] "" Vector__XXX
 SG_ TRCM_a117_VEH_doorStatus m117 : 27|1@1+ (1,0) [0|1] "" Vector__XXX
 SG_ TRCM_a117_VEH_doorStatus2 m117 : 28|1@1+ (1,0) [0|1] "" Vector__XXX
 SG_ TRCM_a117_VEH_windowStatus m117 : 29|1@1+ (1,0) [0|1] "" Vector__XXX
 SG_ TRCM_a117_VEH_switchStatus m117 : 30|1@1+ (1,0) [0|1] "" Vector__XXX
 SG_ TRCM_a117_VEH_intrusionSensorSta m117 : 31|1@1+ (1,0) [0|1] "" Vector__XXX
 SG_ TRCM_a117_VEH_liftgateStatus m117 : 32|1@1+ (1,0) [0|1] "" Vector__XXX
 SG_ TRCM_a117_VEH_seatStatus2 m117 : 33|1@1+ (1,0) [0|1] "" Vector__XXX
 SG_ TRCM_a117_PARTY_restraintStatus m117 : 34|1@1+ (1,0) [0|1] "" Vector__XXX
 SG_ TRCM_a117_VEH_thermalStatus m117 : 35|1@1+ (1,0) [0|1] "" Vector__XXX
 SG_ TRCM_a117_PARTY_doorStatus m117 : 36|1@1+ (1,0) [0|1] "" Vector__XXX
 SG_ TRCM_a117_VEH_status m117 : 37|1@1+ (1,0) [0|1] "" Vector__XXX
 SG_ TRCM_a117_PARTY_prndStatus m117 : 38|1@1+ (1,0) [0|1] "" Vector__XXX
 SG_ TRCM_a118_VEH_vehNm m118 : 16|1@1+ (1,0) [0|1] "" Vector__XXX
 SG_ TRCM_a118_VEH_lighting m118 : 17|1@1+ (1,0) [0|1] "" Vector__XXX
 SG_ TRCM_a118_VEH_sensors m118 : 18|1@1+ (1,0) [0|1] "" Vector__XXX
 SG_ TRCM_a118_VEH_status m118 : 19|1@1+ (1,0) [0|1] "" Vector__XXX
 SG_ TRCM_a118_VEH_okToUseHighPwr m118 : 20|1@1+ (1,0) [0|1] "" Vector__XXX
 SG_ TRCM_a118_VEH_LVPowerState m118 : 21|1@1+ (1,0) [0|1] "" Vector__XXX
 SG_ TRCM_a118_VEH_coolant m118 : 22|1@1+ (1,0) [0|1] "" Vector__XXX
 SG_ TRCM_a118_VEH_vehicleStatus m118 : 23|1@1+ (1,0) [0|1] "" Vector__XXX
 SG_ TRCM_a118_VEH_12VBatteryStatus m118 : 24|1@1+ (1,0) [0|1] "" Vector__XXX
 SG_ TRCM_a118_VEH_systemStatus m118 : 25|1@1+ (1,0) [0|1] "" Vector__XXX
 SG_ TRCM_a118_PARTY_LVPowerState m118 : 26|1@1+ (1,0) [0|1] "" Vector__XXX
 SG_ TRCM_a118_PARTY_outputPowerStatu m118 : 27|1@1+ (1,0) [0|1] "" Vector__XXX
 SG_ TRCM_a118_PARTY_vehicleTime m118 : 28|1@1+ (1,0) [0|1] "" Vector__XXX
 SG_ TRCM_a118_VEH_thermalCommand m118 : 29|1@1+ (1,0) [0|1] "" Vector__XXX
 SG_ TRCM_a118_CH_LVPowerState m118 : 30|1@1+ (1,0) [0|1] "" Vector__XXX
 SG_ TRCM_a118_PARTY_sensors m118 : 31|1@1+ (1,0) [0|1] "" Vector__XXX
 SG_ TRCM_a118_CH_sensors m118 : 32|1@1+ (1,0) [0|1] "" Vector__XXX
 SG_ TRCM_a118_VEH_interNodeResistanc m118 : 33|1@1+ (1,0) [0|1] "" Vector__XXX
 SG_ TRCM_a118_CH_lighting m118 : 34|1@1+ (1,0) [0|1] "" Vector__XXX
 SG_ TRCM_a118_VEH_lightStatus m118 : 35|1@1+ (1,0) [0|1] "" Vector__XXX
 SG_ TRCM_a118_PARTY_vehNm m118 : 36|1@1+ (1,0) [0|1] "" Vector__XXX
 SG_ TRCM_a118_CH_12VBatteryStatus m118 : 37|1@1+ (1,0) [0|1] "" Vector__XXX
 SG_ TRCM_a118_CH_LVBMS_statusHigh m118 : 38|1@1+ (1,0) [0|1] "" Vector__XXX
 SG_ TRCM_a118_CH_alertMatrix m118 : 39|1@1+ (1,0) [0|1] "" Vector__XXX
 SG_ TRCM_a118_BDY_outputPowerStatus m118 : 40|1@1+ (1,0) [0|1] "" Vector__XXX
 SG_ TRCM_a118_BDY_vehicleTime m118 : 41|1@1+ (1,0) [0|1] "" Vector__XXX
 SG_ TRCM_a118_PARTY_AP_vehicleState1 m118 : 42|1@1+ (1,0) [0|1] "" Vector__XXX
 SG_ TRCM_a118_BDY_AP_vehicleState1Hz m118 : 43|1@1+ (1,0) [0|1] "" Vector__XXX
 SG_ TRCM_a119_VEH_steerAngle m119 : 16|1@1+ (1,0) [0|1] "" Vector__XXX
 SG_ TRCM_a119_VEH_leftStalk m119 : 17|1@1+ (1,0) [0|1] "" Vector__XXX
 SG_ TRCM_a119_VEH_rightStalk m119 : 18|1@1+ (1,0) [0|1] "" Vector__XXX
 SG_ TRCM_a119_PARTY_rightStalk m119 : 19|1@1+ (1,0) [0|1] "" Vector__XXX
 SG_ TRCM_a119_CH_steerAngle m119 : 20|1@1+ (1,0) [0|1] "" Vector__XXX
 SG_ TRCM_a119_PARTY_steerAngle m119 : 21|1@1+ (1,0) [0|1] "" Vector__XXX
 SG_ TRCM_a120_PARTY_chassisCntl m120 : 16|1@1+ (1,0) [0|1] "" Vector__XXX
 SG_ TRCM_a120_VEH_systemStatus m120 : 17|1@1+ (1,0) [0|1] "" Vector__XXX
 SG_ TRCM_a120_CH_chassisCntl m120 : 18|1@1+ (1,0) [0|1] "" Vector__XXX
 SG_ TRCM_a120_PARTY_systemStatus m120 : 19|1@1+ (1,0) [0|1] "" Vector__XXX
 SG_ TRCM_a120_PARTY_torque m120 : 20|1@1+ (1,0) [0|1] "" Vector__XXX
 SG_ TRCM_a120_VEH_torque m120 : 21|1@1+ (1,0) [0|1] "" Vector__XXX
 SG_ TRCM_a120_PARTY_locStatus m120 : 22|1@1+ (1,0) [0|1] "" Vector__XXX
 SG_ TRCM_a120_PARTY_speed m120 : 23|1@1+ (1,0) [0|1] "" Vector__XXX
 SG_ TRCM_a120_VEH_speed m120 : 24|1@1+ (1,0) [0|1] "" Vector__XXX
 SG_ TRCM_a120_PARTY_status m120 : 25|1@1+ (1,0) [0|1] "" Vector__XXX
 SG_ TRCM_a120_PT_speed m120 : 26|1@1+ (1,0) [0|1] "" Vector__XXX
 SG_ TRCM_a120_PT_systemStatus m120 : 27|1@1+ (1,0) [0|1] "" Vector__XXX
 SG_ TRCM_a120_PARTY_vehicleEstimates m120 : 28|1@1+ (1,0) [0|1] "" Vector__XXX
 SG_ TRCM_a120_VEH_aggregatedAxleSpee m120 : 29|1@1+ (1,0) [0|1] "" Vector__XXX
 SG_ TRCM_a120_PARTY_aggregatedAxleSp m120 : 30|1@1+ (1,0) [0|1] "" Vector__XXX
 SG_ TRCM_a120_VEH_systemPower m120 : 31|1@1+ (1,0) [0|1] "" Vector__XXX
 SG_ TRCM_a120_PT_systemPower m120 : 32|1@1+ (1,0) [0|1] "" Vector__XXX
 SG_ TRCM_a120_PARTY_stalklessInterfa m120 : 33|1@1+ (1,0) [0|1] "" Vector__XXX
 SG_ TRCM_a120_CH_speed m120 : 34|1@1+ (1,0) [0|1] "" Vector__XXX
 SG_ TRCM_a120_VEH_estimatedBrakeTemp m120 : 35|1@1+ (1,0) [0|1] "" Vector__XXX
 SG_ TRCM_a120_PARTY_prndControl m120 : 36|1@1+ (1,0) [0|1] "" Vector__XXX
 SG_ TRCM_a120_PARTY_locStatus2 m120 : 37|1@1+ (1,0) [0|1] "" Vector__XXX
 SG_ TRCM_a120_VEH_chassisCntl m120 : 38|1@1+ (1,0) [0|1] "" Vector__XXX
 SG_ TRCM_a120_VEH_locStatus m120 : 39|1@1+ (1,0) [0|1] "" Vector__XXX
 SG_ TRCM_a120_VEH_locStatus2 m120 : 40|1@1+ (1,0) [0|1] "" Vector__XXX
 SG_ TRCM_a120_VEH_prndControl m120 : 41|1@1+ (1,0) [0|1] "" Vector__XXX
 SG_ TRCM_a120_VEH_vehicleEstimates m120 : 42|1@1+ (1,0) [0|1] "" Vector__XXX

CM_ BO_ 1835 "Air suspension controller message: alert log";
CM_ SG_ 1835 TAS_alertID "Air suspension controller: alert ID";
CM_ SG_ 1835 TAS_alertState "Air suspension controller: alert state";
CM_ SG_ 1835 TAS_a001_InternalWatchdog "Air suspension controller: a001 internal watchdog";
CM_ SG_ 1835 TAS_a002_CPUUndervoltage "Air suspension controller: a002 CPU undervoltage";
CM_ SG_ 1835 TAS_a002_PowerOnReset "Air suspension controller: a002 power on reset";
CM_ SG_ 1835 TAS_a003_AssertID "Air suspension controller: a003 assert ID";
CM_ SG_ 1835 TAS_a003_LineNumber "Air suspension controller: a003 line number";
CM_ SG_ 1835 TAS_a003_Data "Air suspension controller: a003 data";
CM_ SG_ 1835 TAS_a012_ClockError "Air suspension controller: a012 clock error";
CM_ SG_ 1835 TAS_a012_FlashError "Air suspension controller: a012 flash error";
CM_ SG_ 1835 TAS_a012_SoftwareReset "Air suspension controller: a012 software reset";
CM_ SG_ 1835 TAS_a012_CheckstopReset "Air suspension controller: a012 checkstop reset";
CM_ SG_ 1835 TAS_a012_DebugReset "Air suspension controller: a012 debug reset";
CM_ SG_ 1835 TAS_a012_ExternalReset "Air suspension controller: a012 external reset";
CM_ SG_ 1835 TAS_a021_Task1msLate "Air suspension controller: a021 task1ms late";
CM_ SG_ 1835 TAS_a021_Task1msStarved "Air suspension controller: a021 task1ms starved";
CM_ SG_ 1835 TAS_a021_Task1msMissed "Air suspension controller: a021 task1ms missed";
CM_ SG_ 1835 TAS_a021_Task10msLate "Air suspension controller: a021 task10ms late";
CM_ SG_ 1835 TAS_a021_Task10msStarved "Air suspension controller: a021 task10ms starved";
CM_ SG_ 1835 TAS_a021_Task10msMissed "Air suspension controller: a021 task10ms missed";
CM_ SG_ 1835 TAS_a021_Task100msLate "Air suspension controller: a021 task100ms late";
CM_ SG_ 1835 TAS_a021_Task100msStarved "Air suspension controller: a021 task100ms starved";
CM_ SG_ 1835 TAS_a021_Task100msMissed "Air suspension controller: a021 task100ms missed";
CM_ SG_ 1835 TAS_a021_Task1000msLate "Air suspension controller: a021 task1000ms late";
CM_ SG_ 1835 TAS_a021_Task1000msStarved "Air suspension controller: a021 task1000ms starved";
CM_ SG_ 1835 TAS_a021_Task1000msMissed "Air suspension controller: a021 task1000ms missed";
CM_ SG_ 1835 TAS_a022_TaskInitErrorCount "Air suspension controller: a022 task init error count";
CM_ SG_ 1835 TAS_a022_TaskInitError0 "Air suspension controller: a022 task init error0";
CM_ SG_ 1835 TAS_a022_TaskInitError1 "Air suspension controller: a022 task init error1";
CM_ SG_ 1835 TAS_a022_TaskInitError2 "Air suspension controller: a022 task init error2";
CM_ SG_ 1835 TAS_a022_TaskInitError3 "Air suspension controller: a022 task init error3";
CM_ SG_ 1835 TAS_a022_TaskInitError4 "Air suspension controller: a022 task init error4";
CM_ SG_ 1835 TAS_a025_vehicleLockAtCrash "Air suspension controller: a025 vehicle lock at crash";
CM_ SG_ 1835 TAS_a025_CANCrashIsActive "Air suspension controller: a025 CAN crash is active";
CM_ SG_ 1835 TAS_a025_appCrashIsActive "Air suspension controller: a025 app crash is active";
CM_ SG_ 1835 TAS_a025_lastCrashEvent "Air suspension controller: a025 last crash event";
CM_ SG_ 1835 TAS_a030_PWMdutyCycleFL "Air suspension controller: a030 PW mduty cycle FL";
CM_ SG_ 1835 TAS_a030_PWMfrequencyFL "Air suspension controller: a030 PW mfrequency FL";
CM_ SG_ 1835 TAS_a030_PWMfaultFL "Air suspension controller: a030 PW mfault FL";
CM_ SG_ 1835 TAS_a031_PWMdutyCycleFR "Air suspension controller: a031 PW mduty cycle FR";
CM_ SG_ 1835 TAS_a031_PWMfrequencyFR "Air suspension controller: a031 PW mfrequency FR";
CM_ SG_ 1835 TAS_a031_PWMfaultFR "Air suspension controller: a031 PW mfault FR";
CM_ SG_ 1835 TAS_a032_PWMdutyCycleRL "Air suspension controller: a032 PW mduty cycle RL";
CM_ SG_ 1835 TAS_a032_PWMfrequencyRL "Air suspension controller: a032 PW mfrequency RL";
CM_ SG_ 1835 TAS_a032_PWMfaultRL "Air suspension controller: a032 PW mfault RL";
CM_ SG_ 1835 TAS_a033_PWMdutyCycleRR "Air suspension controller: a033 PW mduty cycle RR";
CM_ SG_ 1835 TAS_a033_PWMfrequencyRR "Air suspension controller: a033 PW mfrequency RR";
CM_ SG_ 1835 TAS_a033_PWMfaultRR "Air suspension controller: a033 PW mfault RR";
CM_ SG_ 1835 TAS_a034_PWMdutyCycleFL "Air suspension controller: a034 PW mduty cycle FL";
CM_ SG_ 1835 TAS_a034_PWMfrequencyFL "Air suspension controller: a034 PW mfrequency FL";
CM_ SG_ 1835 TAS_a034_PWMfaultFL "Air suspension controller: a034 PW mfault FL";
CM_ SG_ 1835 TAS_a035_PWMdutyCycleFR "Air suspension controller: a035 PW mduty cycle FR";
CM_ SG_ 1835 TAS_a035_PWMfrequencyFR "Air suspension controller: a035 PW mfrequency FR";
CM_ SG_ 1835 TAS_a035_PWMfaultFR "Air suspension controller: a035 PW mfault FR";
CM_ SG_ 1835 TAS_a036_PWMdutyCycleRL "Air suspension controller: a036 PW mduty cycle RL";
CM_ SG_ 1835 TAS_a036_PWMfrequencyRL "Air suspension controller: a036 PW mfrequency RL";
CM_ SG_ 1835 TAS_a036_PWMfaultRL "Air suspension controller: a036 PW mfault RL";
CM_ SG_ 1835 TAS_a037_PWMdutyCycleRR "Air suspension controller: a037 PW mduty cycle RR";
CM_ SG_ 1835 TAS_a037_PWMfrequencyRR "Air suspension controller: a037 PW mfrequency RR";
CM_ SG_ 1835 TAS_a037_PWMfaultRR "Air suspension controller: a037 PW mfault RR";
CM_ SG_ 1835 TAS_a038_PWMdutyCycleFL "Air suspension controller: a038 PW mduty cycle FL";
CM_ SG_ 1835 TAS_a038_PWMfrequencyFL "Air suspension controller: a038 PW mfrequency FL";
CM_ SG_ 1835 TAS_a038_PWMfaultFL "Air suspension controller: a038 PW mfault FL";
CM_ SG_ 1835 TAS_a039_PWMdutyCycleFR "Air suspension controller: a039 PW mduty cycle FR";
CM_ SG_ 1835 TAS_a039_PWMfrequencyFR "Air suspension controller: a039 PW mfrequency FR";
CM_ SG_ 1835 TAS_a039_PWMfaultFR "Air suspension controller: a039 PW mfault FR";
CM_ SG_ 1835 TAS_a040_PWMdutyCycleRL "Air suspension controller: a040 PW mduty cycle RL";
CM_ SG_ 1835 TAS_a040_PWMfrequencyRL "Air suspension controller: a040 PW mfrequency RL";
CM_ SG_ 1835 TAS_a040_PWMfaultRL "Air suspension controller: a040 PW mfault RL";
CM_ SG_ 1835 TAS_a041_PWMdutyCycleRR "Air suspension controller: a041 PW mduty cycle RR";
CM_ SG_ 1835 TAS_a041_PWMfrequencyRR "Air suspension controller: a041 PW mfrequency RR";
CM_ SG_ 1835 TAS_a041_PWMfaultRR "Air suspension controller: a041 PW mfault RR";
CM_ SG_ 1835 TAS_a070_voltage12V "Air suspension controller: a070 voltage12 v";
CM_ SG_ 1835 TAS_a071_voltage12V "Air suspension controller: a071 voltage12 v";
CM_ SG_ 1835 TAS_a072_voltage5VOnBoard "Air suspension controller: a072 voltage5 v on board";
CM_ SG_ 1835 TAS_a073_voltage5VOnBoard "Air suspension controller: a073 voltage5 v on board";
CM_ SG_ 1835 TAS_a074_voltage5VOffBoard "Air suspension controller: a074 voltage5 v off board";
CM_ SG_ 1835 TAS_a075_voltage5VOffBoard "Air suspension controller: a075 voltage5 v off board";
CM_ SG_ 1835 TAS_a076_voltage5VOffBoard "Air suspension controller: a076 voltage5 v off board";
CM_ SG_ 1835 TAS_a077_sensorVoltage "Air suspension controller: a077 sensor voltage";
CM_ SG_ 1835 TAS_a077_sensorRefVoltage "Air suspension controller: a077 sensor ref voltage";
CM_ SG_ 1835 TAS_a078_sensorVoltage "Air suspension controller: a078 sensor voltage";
CM_ SG_ 1835 TAS_a078_sensorRefVoltage "Air suspension controller: a078 sensor ref voltage";
CM_ SG_ 1835 TAS_a080_voltage5VHeight "Air suspension controller: a080 voltage5 v height";
CM_ SG_ 1835 TAS_a081_voltage5VHeight "Air suspension controller: a081 voltage5 v height";
CM_ SG_ 1835 TAS_a082_voltage5VHeight "Air suspension controller: a082 voltage5 v height";
CM_ SG_ 1835 TAS_a083_voltage5VAnalog "Air suspension controller: a083 voltage5 v analog";
CM_ SG_ 1835 TAS_a084_voltage5VAnalog "Air suspension controller: a084 voltage5 v analog";
CM_ SG_ 1835 TAS_a085_voltage5VAnalog "Air suspension controller: a085 voltage5 v analog";
CM_ SG_ 1835 TAS_a086_voltage12VSwitched "Air suspension controller: a086 voltage12 v switched";
CM_ SG_ 1835 TAS_a087_voltage12VSwitched "Air suspension controller: a087 voltage12 v switched";
CM_ SG_ 1835 TAS_a093_readError "Air suspension controller: a093 read error";
CM_ SG_ 1835 TAS_a093_IVOR2Exception "Air suspension controller: a093 IVOR2 exception";
CM_ SG_ 1835 TAS_a098_VCFRONT_LVPowerState_MI "Air suspension controller: a098 VCFRONT LV power state MIA";
CM_ SG_ 1835 TAS_a098_VCFRONT_sensors_MIA "Air suspension controller: a098 VCFRONT sensors MIA";
CM_ SG_ 1835 TAS_a098_VCFRONT_status_MIA "Air suspension controller: a098 VCFRONT status MIA";
CM_ SG_ 1835 TAS_a098_VCFRONT_systemStatus_MI "Air suspension controller: a098 VCFRONT system status MIA";
CM_ SG_ 1835 TAS_a098_VCFRONT_vehNm_MIA "Air suspension controller: a098 VCFRONT veh nm MIA";
CM_ SG_ 1835 TAS_a099_UI_chassisControl_MIA "Air suspension controller: a099 UI chassis control MIA";
CM_ SG_ 1835 TAS_a099_UI_driverAssistMapData_ "Air suspension controller: a099 UI driver assist map data MIA";
CM_ SG_ 1835 TAS_a099_UI_suspensionControl_MI "Air suspension controller: a099 UI suspension control MIA";
CM_ SG_ 1835 TAS_a099_UI_vehicleModes_MIA "Air suspension controller: a099 UI vehicle modes MIA";
CM_ SG_ 1835 TAS_a100_RCM_inertial1_MIA "Air suspension controller: a100 RCM inertial1 MIA";
CM_ SG_ 1835 TAS_a100_RCM_inertial2_MIA "Air suspension controller: a100 RCM inertial2 MIA";
CM_ SG_ 1835 TAS_a101_ESP_brakeTorque_MIA "Air suspension controller: a101 ESP brake torque MIA";
CM_ SG_ 1835 TAS_a101_ESP_status_MIA "Air suspension controller: a101 ESP status MIA";
CM_ SG_ 1835 TAS_a101_ESP_wheelRotation_MIA "Air suspension controller: a101 ESP wheel rotation MIA";
CM_ SG_ 1835 TAS_a102_DI_chassisControl_MIA "Air suspension controller: a102 DI chassis control MIA";
CM_ SG_ 1835 TAS_a102_DI_locStatus_MIA "Air suspension controller: a102 DI loc status MIA";
CM_ SG_ 1835 TAS_a102_DI_speed_MIA "Air suspension controller: a102 DI speed MIA";
CM_ SG_ 1835 TAS_a102_DI_systemStatus_MIA "Air suspension controller: a102 DI system status MIA";
CM_ SG_ 1835 TAS_a102_DI_vehicleEstimates_MIA "Air suspension controller: a102 DI vehicle estimates MIA";
CM_ SG_ 1835 TAS_a102_DIF_torque_MIA "Air suspension controller: a102 DIF torque MIA";
CM_ SG_ 1835 TAS_a102_DIR_torque_MIA "Air suspension controller: a102 DIR torque MIA";
CM_ SG_ 1835 TAS_a103_GTW_carConfig_MIA "Air suspension controller: a103 GTW car config MIA";
CM_ SG_ 1835 TAS_a103_GTW_time_MIA "Air suspension controller: a103 GTW time MIA";
CM_ SG_ 1835 TAS_a103_GTW_vehNm_MIA "Air suspension controller: a103 GTW veh nm MIA";
CM_ SG_ 1835 TAS_a103_GTW_vin_MIA "Air suspension controller: a103 GTW vin MIA";
CM_ SG_ 1835 TAS_a164_detectedDamperSolenoid "Air suspension controller: a164 detected damper solenoid";
CM_ SG_ 1835 TAS_a164_expectedDamperSolenoid "Air suspension controller: a164 expected damper solenoid";
CM_ SG_ 1835 TAS_a165_damperValveFault "Air suspension controller: a165 damper valve fault";
CM_ SG_ 1835 TAS_a166_damperValveFault "Air suspension controller: a166 damper valve fault";
CM_ SG_ 1835 TAS_a167_damperValveFault "Air suspension controller: a167 damper valve fault";
CM_ SG_ 1835 TAS_a168_damperValveFault "Air suspension controller: a168 damper valve fault";
CM_ SG_ 1835 TAS_a169_damperValveFault "Air suspension controller: a169 damper valve fault";
CM_ SG_ 1835 TAS_a170_damperValveFault "Air suspension controller: a170 damper valve fault";
CM_ SG_ 1835 TAS_a171_damperValveFault "Air suspension controller: a171 damper valve fault";
CM_ SG_ 1835 TAS_a172_damperValveFault "Air suspension controller: a172 damper valve fault";
CM_ SG_ 1835 TAS_a173_heightDelta_mm "Air suspension controller: a173 height delta mm";
CM_ SG_ 1835 TAS_a174_heightDelta_mm "Air suspension controller: a174 height delta mm";
CM_ SG_ 1835 TAS_a175_heightDelta_mm "Air suspension controller: a175 height delta mm";
CM_ SG_ 1835 TAS_a176_heightDelta_mm "Air suspension controller: a176 height delta mm";
CM_ SG_ 1835 TAS_a190_a2bFaultType "Air suspension controller: a190 a2b fault type";
CM_ SG_ 1835 TAS_a190_a2bInterruptType "Air suspension controller: a190 a2b interrupt type";
CM_ SG_ 1835 TAS_a190_a2bFaultSource "Air suspension controller: a190 a2b fault source";
CM_ SG_ 1835 TAS_a191_a2bFaultType "Air suspension controller: a191 a2b fault type";
CM_ SG_ 1835 TAS_a191_a2bInterruptType "Air suspension controller: a191 a2b interrupt type";
CM_ SG_ 1835 TAS_a191_a2bFaultSource "Air suspension controller: a191 a2b fault source";
CM_ SG_ 1835 TAS_a192_rideHeightVelDspFL "Air suspension controller: a192 ride height vel dsp FL";
CM_ SG_ 1835 TAS_a192_rideHeightVelDspFR "Air suspension controller: a192 ride height vel dsp FR";
CM_ SG_ 1835 TAS_a192_rideHeightVelDspRL "Air suspension controller: a192 ride height vel dsp RL";
CM_ SG_ 1835 TAS_a192_rideHeightVelDspRR "Air suspension controller: a192 ride height vel dsp RR";
CM_ SG_ 1835 TAS_a192_rideHeightVelObserverFL "Air suspension controller: a192 ride height vel observer FL";
CM_ SG_ 1835 TAS_a192_rideHeightVelObserverFR "Air suspension controller: a192 ride height vel observer FR";
CM_ SG_ 1835 TAS_a192_rideHeightVelObserverRL "Air suspension controller: a192 ride height vel observer RL";
CM_ SG_ 1835 TAS_a192_rideHeightVelObserverRR "Air suspension controller: a192 ride height vel observer RR";
CM_ SG_ 1835 TAS_a192_alertVersion "Air suspension controller: a192 alert version";
CM_ SG_ 1835 TAS_a193_EPAS3P_sysStatus_MIA "Air suspension controller: a193 EPAS3 p sys status MIA";
CM_ SG_ 1835 TAS_a210_heightSensorDeltaFL "Air suspension controller: a210 height sensor delta FL";
CM_ SG_ 1835 TAS_a210_heightSensorDeltaFR "Air suspension controller: a210 height sensor delta FR";
CM_ SG_ 1835 TAS_a210_heightSensorDeltaRL "Air suspension controller: a210 height sensor delta RL";
CM_ SG_ 1835 TAS_a210_heightSensorDeltaRR "Air suspension controller: a210 height sensor delta RR";
CM_ SG_ 1835 TAS_a220_galleryPressure "Air suspension controller: a220 gallery pressure";
CM_ SG_ 1835 TAS_a220_timeInExhaust "Air suspension controller: a220 time in exhaust";
CM_ SG_ 1835 TAS_a221_galleryPressureDelta "Air suspension controller: a221 gallery pressure delta";
CM_ SG_ 1835 TAS_a221_timeInIdle "Air suspension controller: a221 time in idle";
CM_ SG_ 1835 TAS_a222_galleryPressureDelta "Air suspension controller: a222 gallery pressure delta";
CM_ SG_ 1835 TAS_a223_galleryPressure "Air suspension controller: a223 gallery pressure";
CM_ SG_ 1835 TAS_a223_valveOnFL "Air suspension controller: a223 valve on FL";
CM_ SG_ 1835 TAS_a223_valveOnFR "Air suspension controller: a223 valve on FR";
CM_ SG_ 1835 TAS_a223_valveOnRL "Air suspension controller: a223 valve on RL";
CM_ SG_ 1835 TAS_a223_valveOnRR "Air suspension controller: a223 valve on RR";
CM_ SG_ 1835 TAS_a223_valveOnReservoir "Air suspension controller: a223 valve on reservoir";
CM_ SG_ 1835 TAS_a224_galleryPressure "Air suspension controller: a224 gallery pressure";
CM_ SG_ 1835 TAS_a224_valveOnFL "Air suspension controller: a224 valve on FL";
CM_ SG_ 1835 TAS_a224_valveOnFR "Air suspension controller: a224 valve on FR";
CM_ SG_ 1835 TAS_a224_valveOnRL "Air suspension controller: a224 valve on RL";
CM_ SG_ 1835 TAS_a224_valveOnRR "Air suspension controller: a224 valve on RR";
CM_ SG_ 1835 TAS_a224_valveOnReservoir "Air suspension controller: a224 valve on reservoir";
CM_ SG_ 1835 TAS_a225_galleryPressure "Air suspension controller: a225 gallery pressure";
CM_ SG_ 1835 TAS_a226_PWMdutyCycleFL "Air suspension controller: a226 PW mduty cycle FL";
CM_ SG_ 1835 TAS_a226_PWMfrequencyFL "Air suspension controller: a226 PW mfrequency FL";
CM_ SG_ 1835 TAS_a226_PWMfaultFL "Air suspension controller: a226 PW mfault FL";
CM_ SG_ 1835 TAS_a227_PWMdutyCycleFR "Air suspension controller: a227 PW mduty cycle FR";
CM_ SG_ 1835 TAS_a227_PWMfrequencyFR "Air suspension controller: a227 PW mfrequency FR";
CM_ SG_ 1835 TAS_a227_PWMfaultFR "Air suspension controller: a227 PW mfault FR";
CM_ SG_ 1835 TAS_a228_PWMdutyCycleRL "Air suspension controller: a228 PW mduty cycle RL";
CM_ SG_ 1835 TAS_a228_PWMfrequencyRL "Air suspension controller: a228 PW mfrequency RL";
CM_ SG_ 1835 TAS_a228_PWMfaultRL "Air suspension controller: a228 PW mfault RL";
CM_ SG_ 1835 TAS_a229_PWMdutyCycleRR "Air suspension controller: a229 PW mduty cycle RR";
CM_ SG_ 1835 TAS_a229_PWMfrequencyRR "Air suspension controller: a229 PW mfrequency RR";
CM_ SG_ 1835 TAS_a229_PWMfaultRR "Air suspension controller: a229 PW mfault RR";
CM_ SG_ 1835 TAS_a232_detectedSuspensionType "Air suspension controller: a232 detected suspension type";
CM_ SG_ 1835 TAS_a232_expectedSuspensionType "Air suspension controller: a232 expected suspension type";
CM_ SG_ 1835 TAS_a234_detectedDamperHydraulic "Air suspension controller: a234 detected damper hydraulic";
CM_ SG_ 1835 TAS_a234_expectedDamperHydraulic "Air suspension controller: a234 expected damper hydraulic";
CM_ SG_ 1835 TAS_a240_highAdjustCountRatio "Air suspension controller: a240 high adjust count ratio";
CM_ SG_ 1835 TAS_a240_highAdjustTimeRatio "Air suspension controller: a240 high adjust time ratio";
CM_ SG_ 1835 TAS_a240_highCrossPressure "Air suspension controller: a240 high cross pressure";
CM_ SG_ 1835 TAS_a240_highCompExhTimeRatio "Air suspension controller: a240 high comp exh time ratio";
CM_ SG_ 1835 TAS_a240_adjustCountRatioSpring "Air suspension controller: a240 adjust count ratio spring";
CM_ SG_ 1835 TAS_a240_adjustCountRatio "Air suspension controller: a240 adjust count ratio";
CM_ SG_ 1835 TAS_a240_adjustTimeRatioSpring "Air suspension controller: a240 adjust time ratio spring";
CM_ SG_ 1835 TAS_a240_adjustTimeRatio "Air suspension controller: a240 adjust time ratio";
CM_ SG_ 1835 TAS_a240_compExhTimeRatio "Air suspension controller: a240 comp exh time ratio";
CM_ SG_ 1835 TAS_a240_crossPressure "Air suspension controller: a240 cross pressure";
CM_ SG_ 1835 TAS_a285_twistLevel "Air suspension controller: a285 twist level";
CM_ SG_ 1835 TAS_a290_twistLevel "Air suspension controller: a290 twist level";
CM_ SG_ 1835 TAS_a291_frontAxleHeight "Air suspension controller: a291 front axle height";
CM_ SG_ 1835 TAS_a292_rearAxleHeight "Air suspension controller: a292 rear axle height";
CM_ SG_ 1835 TAS_a293_frontAxleHeight "Air suspension controller: a293 front axle height";
CM_ SG_ 1835 TAS_a294_rearAxleHeight "Air suspension controller: a294 rear axle height";
CM_ SG_ 1835 TAS_a295_targetHeight "Air suspension controller: a295 target height";
CM_ SG_ 1835 TAS_a296_detectedChassisType "Air suspension controller: a296 detected chassis type";
CM_ SG_ 1835 TAS_a296_expectedChassisType "Air suspension controller: a296 expected chassis type";
CM_ SG_ 1835 TAS_a319_detectedDrivetrainType "Air suspension controller: a319 detected drivetrain type";
CM_ SG_ 1835 TAS_a319_expectedDrivetrainType "Air suspension controller: a319 expected drivetrain type";
CM_ BO_ 852 "Air suspension controller message: alert matrix";
CM_ SG_ 852 TAS_matrixIndex "Air suspension controller: matrix index";
CM_ SG_ 852 TAS_a001_WatchdogReset "Air suspension controller: a001 watchdog reset";
CM_ SG_ 852 TAS_a002_PowerLossReset "Air suspension controller: a002 power loss reset";
CM_ SG_ 852 TAS_a003_SWAssertion "Air suspension controller: a003 SW assertion";
CM_ SG_ 852 TAS_a012_CPUReset "Air suspension controller: a012 CPU reset";
CM_ SG_ 852 TAS_a015_NVMMError "Air suspension controller: a015 NVMM error";
CM_ SG_ 852 TAS_a016_NVMMRecordError "Air suspension controller: a016 NVMM record error";
CM_ SG_ 852 TAS_a021_TaskSchedulerError "Air suspension controller: a021 task scheduler error";
CM_ SG_ 852 TAS_a022_TaskInitError "Air suspension controller: a022 task init error";
CM_ SG_ 852 TAS_a023_rtosResetRequested "Air suspension controller: a023 rtos reset requested";
CM_ SG_ 852 TAS_a024_prefetchAbort "Air suspension controller: a024 prefetch abort";
CM_ SG_ 852 TAS_a025_CrashEvent "Air suspension controller: a025 crash event";
CM_ SG_ 852 TAS_a030_PWMerrorFL "Air suspension controller: a030 PW merror FL";
CM_ SG_ 852 TAS_a031_PWMerrorFR "Air suspension controller: a031 PW merror FR";
CM_ SG_ 852 TAS_a032_PWMerrorRL "Air suspension controller: a032 PW merror RL";
CM_ SG_ 852 TAS_a033_PWMerrorRR "Air suspension controller: a033 PW merror RR";
CM_ SG_ 852 TAS_a034_PWMshortFL "Air suspension controller: a034 PW mshort FL";
CM_ SG_ 852 TAS_a035_PWMshortFR "Air suspension controller: a035 PW mshort FR";
CM_ SG_ 852 TAS_a036_PWMshortRL "Air suspension controller: a036 PW mshort RL";
CM_ SG_ 852 TAS_a037_PWMshortRR "Air suspension controller: a037 PW mshort RR";
CM_ SG_ 852 TAS_a038_PWMopenFL "Air suspension controller: a038 PW mopen FL";
CM_ SG_ 852 TAS_a039_PWMopenFR "Air suspension controller: a039 PW mopen FR";
CM_ SG_ 852 TAS_a040_PWMopenRL "Air suspension controller: a040 PW mopen RL";
CM_ SG_ 852 TAS_a041_PWMopenRR "Air suspension controller: a041 PW mopen RR";
CM_ SG_ 852 TAS_a043_Task1msError "Air suspension controller: a043 task1ms error";
CM_ SG_ 852 TAS_a044_Task10msError "Air suspension controller: a044 task10ms error";
CM_ SG_ 852 TAS_a045_Task100msError "Air suspension controller: a045 task100ms error";
CM_ SG_ 852 TAS_a046_Task1000msError "Air suspension controller: a046 task1000ms error";
CM_ SG_ 852 TAS_a061_XCPConnected "Air suspension controller: a061 XCP connected";
CM_ SG_ 852 TAS_a062_XCPWasConnected "Air suspension controller: a062 XCP was connected";
CM_ SG_ 852 TAS_a063_abortFault "Air suspension controller: a063 abort fault";
CM_ SG_ 852 TAS_a064_abortFaultExt "Air suspension controller: a064 abort fault ext";
CM_ SG_ 852 TAS_a065_ahbWriteFault "Air suspension controller: a065 ahb write fault";
CM_ SG_ 852 TAS_a066_undefinedInstructionAbo "Air suspension controller: a066 undefined instruction abort";
CM_ SG_ 852 TAS_a067_reservedHandlerAbort "Air suspension controller: a067 reserved handler abort";
CM_ SG_ 852 TAS_a070_underVoltage12V "Air suspension controller: a070 under voltage12 v";
CM_ SG_ 852 TAS_a071_overVoltage12V "Air suspension controller: a071 over voltage12 v";
CM_ SG_ 852 TAS_a072_shortCircuit5VOnBoard "Air suspension controller: a072 short circuit5 v on board";
CM_ SG_ 852 TAS_a073_underVoltage5VOnBoard "Air suspension controller: a073 under voltage5 v on board";
CM_ SG_ 852 TAS_a074_shortCircuit5VOffBoard "Air suspension controller: a074 short circuit5 v off board";
CM_ SG_ 852 TAS_a075_underVoltage5VOffBoard "Air suspension controller: a075 under voltage5 v off board";
CM_ SG_ 852 TAS_a076_overVoltage5VOffBoard "Air suspension controller: a076 over voltage5 v off board";
CM_ SG_ 852 TAS_a077_pressureSigVTooLow "Air suspension controller: a077 pressure sig v too low";
CM_ SG_ 852 TAS_a078_pressureSigVTooHigh "Air suspension controller: a078 pressure sig v too high";
CM_ SG_ 852 TAS_a080_shortCircuit5VHeight "Air suspension controller: a080 short circuit5 v height";
CM_ SG_ 852 TAS_a081_underVoltage5VHeight "Air suspension controller: a081 under voltage5 v height";
CM_ SG_ 852 TAS_a082_overVoltage5VHeight "Air suspension controller: a082 over voltage5 v height";
CM_ SG_ 852 TAS_a083_shortCircuit5VAnalog "Air suspension controller: a083 short circuit5 v analog";
CM_ SG_ 852 TAS_a084_underVoltage5VAnalog "Air suspension controller: a084 under voltage5 v analog";
CM_ SG_ 852 TAS_a085_overVoltage5VAnalog "Air suspension controller: a085 over voltage5 v analog";
CM_ SG_ 852 TAS_a086_underVoltage12VSwtchd "Air suspension controller: a086 under voltage12 v swtchd";
CM_ SG_ 852 TAS_a087_overVoltage12VSwtchd "Air suspension controller: a087 over voltage12 v swtchd";
CM_ SG_ 852 TAS_a093_OTPError "Air suspension controller: a093 OTP error";
CM_ SG_ 852 TAS_a098_VCFRONT_MIA "Air suspension controller: a098 VCFRONT MIA";
CM_ SG_ 852 TAS_a099_UI_MIA "Air suspension controller: a099 UI MIA";
CM_ SG_ 852 TAS_a100_RCM_MIA "Air suspension controller: a100 RCM MIA";
CM_ SG_ 852 TAS_a101_ESP_MIA "Air suspension controller: a101 ESP MIA";
CM_ SG_ 852 TAS_a102_DI_MIA "Air suspension controller: a102 DI MIA";
CM_ SG_ 852 TAS_a103_GTW_MIA "Air suspension controller: a103 GTW MIA";
CM_ SG_ 852 TAS_a105_ECUDebugMode "Air suspension controller: a105 ECU debug mode";
CM_ SG_ 852 TAS_a106_HighCPULoad "Air suspension controller: a106 high CPU load";
CM_ SG_ 852 TAS_a107_HighStackUsage "Air suspension controller: a107 high stack usage";
CM_ SG_ 852 TAS_a150_accelAvgImplausible_FL_ "Air suspension controller: a150 accel avg implausible FL x";
CM_ SG_ 852 TAS_a151_accelAvgImplausible_FL_ "Air suspension controller: a151 accel avg implausible FL y";
CM_ SG_ 852 TAS_a152_accelAvgImplausible_FL_ "Air suspension controller: a152 accel avg implausible FL z";
CM_ SG_ 852 TAS_a153_accelAvgImplausible_FR_ "Air suspension controller: a153 accel avg implausible FR x";
CM_ SG_ 852 TAS_a154_accelAvgImplausible_FR_ "Air suspension controller: a154 accel avg implausible FR y";
CM_ SG_ 852 TAS_a155_accelAvgImplausible_FR_ "Air suspension controller: a155 accel avg implausible FR z";
CM_ SG_ 852 TAS_a156_accelAvgImplausible_RL_ "Air suspension controller: a156 accel avg implausible RL x";
CM_ SG_ 852 TAS_a157_accelAvgImplausible_RL_ "Air suspension controller: a157 accel avg implausible RL y";
CM_ SG_ 852 TAS_a158_accelAvgImplausible_RL_ "Air suspension controller: a158 accel avg implausible RL z";
CM_ SG_ 852 TAS_a159_accelAvgImplausible_RR_ "Air suspension controller: a159 accel avg implausible RR x";
CM_ SG_ 852 TAS_a160_accelAvgImplausible_RR_ "Air suspension controller: a160 accel avg implausible RR y";
CM_ SG_ 852 TAS_a161_accelAvgImplausible_RR_ "Air suspension controller: a161 accel avg implausible RR z";
CM_ SG_ 852 TAS_a164_damperSolenoidMismatch "Air suspension controller: a164 damper solenoid mismatch";
CM_ SG_ 852 TAS_a165_damperValveCompFL "Air suspension controller: a165 damper valve comp FL";
CM_ SG_ 852 TAS_a166_damperValveRbndFL "Air suspension controller: a166 damper valve rbnd FL";
CM_ SG_ 852 TAS_a167_damperValveCompFR "Air suspension controller: a167 damper valve comp FR";
CM_ SG_ 852 TAS_a168_damperValveRbndFR "Air suspension controller: a168 damper valve rbnd FR";
CM_ SG_ 852 TAS_a169_damperValveCompRL "Air suspension controller: a169 damper valve comp RL";
CM_ SG_ 852 TAS_a170_damperValveRbndRL "Air suspension controller: a170 damper valve rbnd RL";
CM_ SG_ 852 TAS_a171_damperValveCompRR "Air suspension controller: a171 damper valve comp RR";
CM_ SG_ 852 TAS_a172_damperValveRbndRR "Air suspension controller: a172 damper valve rbnd RR";
CM_ SG_ 852 TAS_a173_staticLeakDetectFL "Air suspension controller: a173 static leak detect FL";
CM_ SG_ 852 TAS_a174_staticLeakDetectFR "Air suspension controller: a174 static leak detect FR";
CM_ SG_ 852 TAS_a175_staticLeakDetectRL "Air suspension controller: a175 static leak detect RL";
CM_ SG_ 852 TAS_a176_staticLeakDetectRR "Air suspension controller: a176 static leak detect RR";
CM_ SG_ 852 TAS_a190_a2bFrontAxleFault "Air suspension controller: a190 a2b front axle fault";
CM_ SG_ 852 TAS_a191_a2bRearAxleFault "Air suspension controller: a191 a2b rear axle fault";
CM_ SG_ 852 TAS_a192_rideHeightObserverDiver "Air suspension controller: a192 ride height observer divergence";
CM_ SG_ 852 TAS_a193_EPAS3P_MIA "Air suspension controller: a193 EPAS3 p MIA";
CM_ SG_ 852 TAS_a194_a2bFrontAxleDataError "Air suspension controller: a194 a2b front axle data error";
CM_ SG_ 852 TAS_a195_a2bRearAxleDataError "Air suspension controller: a195 a2b rear axle data error";
CM_ SG_ 852 TAS_a196_adaptiveDampingUsingDSP "Air suspension controller: a196 adaptive damping using DSP";
CM_ SG_ 852 TAS_a197_invalidAdaptiveModeRequ "Air suspension controller: a197 invalid adaptive mode requested";
CM_ SG_ 852 TAS_a200_jackModeActive "Air suspension controller: a200 jack mode active";
CM_ SG_ 852 TAS_a201_low12VBattery "Air suspension controller: a201 low12 v battery";
CM_ SG_ 852 TAS_a210_outOfRangeCalibration "Air suspension controller: a210 out of range calibration";
CM_ SG_ 852 TAS_a211_noRideHeightCalib "Air suspension controller: a211 no ride height calib";
CM_ SG_ 852 TAS_a213_yellowWarningLamp "Air suspension controller: a213 yellow warning lamp";
CM_ SG_ 852 TAS_a214_redWarningLamp "Air suspension controller: a214 red warning lamp";
CM_ SG_ 852 TAS_a215_limpHomeMode10 "Air suspension controller: a215 limp home mode10";
CM_ SG_ 852 TAS_a216_limpHomeMode20 "Air suspension controller: a216 limp home mode20";
CM_ SG_ 852 TAS_a217_limpHomeMode30 "Air suspension controller: a217 limp home mode30";
CM_ SG_ 852 TAS_a218_limpHomeMode40 "Air suspension controller: a218 limp home mode40";
CM_ SG_ 852 TAS_a220_exhaustGalleryFault "Air suspension controller: a220 exhaust gallery fault";
CM_ SG_ 852 TAS_a221_valveLeakDetected "Air suspension controller: a221 valve leak detected";
CM_ SG_ 852 TAS_a222_compressorPrefillFault "Air suspension controller: a222 compressor prefill fault";
CM_ SG_ 852 TAS_a223_blockedAirline "Air suspension controller: a223 blocked airline";
CM_ SG_ 852 TAS_a224_openAirline "Air suspension controller: a224 open airline";
CM_ SG_ 852 TAS_a225_galleryPressureTooHigh "Air suspension controller: a225 gallery pressure too high";
CM_ SG_ 852 TAS_a226_PWMfastDetectFL "Air suspension controller: a226 PW mfast detect FL";
CM_ SG_ 852 TAS_a227_PWMfastDetectFR "Air suspension controller: a227 PW mfast detect FR";
CM_ SG_ 852 TAS_a228_PWMfastDetectRL "Air suspension controller: a228 PW mfast detect RL";
CM_ SG_ 852 TAS_a229_PWMfastDetectRR "Air suspension controller: a229 PW mfast detect RR";
CM_ SG_ 852 TAS_a230_notifyGeofence "Air suspension controller: a230 notify geofence";
CM_ SG_ 852 TAS_a231_notifyRoughRoadRaise "Air suspension controller: a231 notify rough road raise";
CM_ SG_ 852 TAS_a232_suspensionTypeMismatch "Air suspension controller: a232 suspension type mismatch";
CM_ SG_ 852 TAS_a233_compressorStuckOn "Air suspension controller: a233 compressor stuck on";
CM_ SG_ 852 TAS_a234_damperHydraulicMismatch "Air suspension controller: a234 damper hydraulic mismatch";
CM_ SG_ 852 TAS_a240_airSpringLeak "Air suspension controller: a240 air spring leak";
CM_ SG_ 852 TAS_a284_serviceRunModeActive "Air suspension controller: a284 service run mode active";
CM_ SG_ 852 TAS_a285_twistSustainedUserVis "Air suspension controller: a285 twist sustained user vis";
CM_ SG_ 852 TAS_a286_driveCycleStats1 "Air suspension controller: a286 drive cycle stats1";
CM_ SG_ 852 TAS_a287_driveCycleStats2 "Air suspension controller: a287 drive cycle stats2";
CM_ SG_ 852 TAS_a288_driveCycleStats3 "Air suspension controller: a288 drive cycle stats3";
CM_ SG_ 852 TAS_a289_driveCycleStats4 "Air suspension controller: a289 drive cycle stats4";
CM_ SG_ 852 TAS_a290_twistSustainedAtSpeed "Air suspension controller: a290 twist sustained at speed";
CM_ SG_ 852 TAS_a291_frontAxleTooHigh "Air suspension controller: a291 front axle too high";
CM_ SG_ 852 TAS_a292_rearAxleTooHigh "Air suspension controller: a292 rear axle too high";
CM_ SG_ 852 TAS_a293_frontAxleTooLow "Air suspension controller: a293 front axle too low";
CM_ SG_ 852 TAS_a294_rearAxleTooLow "Air suspension controller: a294 rear axle too low";
CM_ SG_ 852 TAS_a295_targetHeightNotMet "Air suspension controller: a295 target height not met";
CM_ SG_ 852 TAS_a296_chassisTypeMismatch "Air suspension controller: a296 chassis type mismatch";
CM_ SG_ 852 TAS_a297_vinMismatch "Air suspension controller: a297 vin mismatch";
CM_ SG_ 852 TAS_a298_vinNotLearned "Air suspension controller: a298 vin not learned";
CM_ SG_ 852 TAS_a299_offsetEstimateTooLarge "Air suspension controller: a299 offset estimate too large";
CM_ SG_ 852 TAS_a300_offsetEstimateData1 "Air suspension controller: a300 offset estimate data1";
CM_ SG_ 852 TAS_a301_offsetEstimateData2 "Air suspension controller: a301 offset estimate data2";
CM_ SG_ 852 TAS_a303_massEstimateFrozen "Air suspension controller: a303 mass estimate frozen";
CM_ SG_ 852 TAS_a304_massEstimateFrozenData "Air suspension controller: a304 mass estimate frozen data";
CM_ SG_ 852 TAS_a305_newEndstopPosition "Air suspension controller: a305 new endstop position";
CM_ SG_ 852 TAS_a306_hardwareProtectFrozen "Air suspension controller: a306 hardware protect frozen";
CM_ SG_ 852 TAS_a307_endstopBoundaryComp "Air suspension controller: a307 endstop boundary comp";
CM_ SG_ 852 TAS_a308_endstopBoundaryRbnd "Air suspension controller: a308 endstop boundary rbnd";
CM_ SG_ 852 TAS_a309_controlFrozen "Air suspension controller: a309 control frozen";
CM_ SG_ 852 TAS_a310_controlFrozenData "Air suspension controller: a310 control frozen data";
CM_ SG_ 852 TAS_a311_accelsMIA "Air suspension controller: a311 accels MIA";
CM_ SG_ 852 TAS_a312_rotationalRatesMIA "Air suspension controller: a312 rotational rates MIA";
CM_ SG_ 852 TAS_a313_dampingCntrlDisabled "Air suspension controller: a313 damping cntrl disabled";
CM_ SG_ 852 TAS_a314_dampingReduced "Air suspension controller: a314 damping reduced";
CM_ SG_ 852 TAS_a315_pcbaHighTemp "Air suspension controller: a315 pcba high temp";
CM_ SG_ 852 TAS_a316_offsetsAccels "Air suspension controller: a316 offsets accels";
CM_ SG_ 852 TAS_a317_offsetsRotationalRates "Air suspension controller: a317 offsets rotational rates";
CM_ SG_ 852 TAS_a318_dampingCntrlInputMIA "Air suspension controller: a318 damping cntrl input MIA";
CM_ SG_ 852 TAS_a319_drivetrainTypeMismatch "Air suspension controller: a319 drivetrain type mismatch";
CM_ SG_ 852 TAS_a320_offsetsRotationalRates "Air suspension controller: a320 offsets rotational rates";
CM_ SG_ 852 TAS_a321_speedBumpAttributes1 "Air suspension controller: a321 speed bump attributes1";
CM_ SG_ 852 TAS_a322_speedBumpAttributes2 "Air suspension controller: a322 speed bump attributes2";
CM_ SG_ 852 TAS_a332_levelingThresholds1 "Air suspension controller: a332 leveling thresholds1";
CM_ SG_ 852 TAS_a333_levelingThresholds2 "Air suspension controller: a333 leveling thresholds2";
CM_ BO_ 523 "Air suspension controller message: axle data";
CM_ SG_ 523 TAS_axleIndex "Air suspension controller: axle index";
CM_ SG_ 523 TAS_rawHeightFL "Current height of the FL air spring.";
CM_ SG_ 523 TAS_staticHeightEstimateFL "Current static height estimate of the FL air spring.";
CM_ SG_ 523 TAS_componentPressureFL "Current static pressure of the FL air spring.";
CM_ SG_ 523 TAS_rawHeightFR "Current height of the FR air spring.";
CM_ SG_ 523 TAS_staticHeightEstimateFR "Current static height estimate of the FR air spring.";
CM_ SG_ 523 TAS_componentPressureFR "Current static pressure of the FR air spring.";
CM_ SG_ 523 TAS_rawHeightRL "Current height of the RL air spring.";
CM_ SG_ 523 TAS_staticHeightEstimateRL "Current static height estimate of the RL air spring.";
CM_ SG_ 523 TAS_componentPressureRL "Current static pressure of the RL air spring.";
CM_ SG_ 523 TAS_rawHeightRR "Current height of the RR air spring.";
CM_ SG_ 523 TAS_staticHeightEstimateRR "Current static height estimate of the RR air spring.";
CM_ SG_ 523 TAS_componentPressureRR "Current static pressure of the RR air spring.";
CM_ BO_ 1398 "Air suspension controller message: damping states";
CM_ SG_ 1398 TAS_endstopState "Air suspension controller: endstop state";
CM_ SG_ 1398 TAS_continuousControlState "SW-237496";
CM_ SG_ 1398 TAS_activeTireTune "Air suspension controller: active tire tune";
CM_ SG_ 1398 TAS_roughnessRaiseReason "Air suspension controller: roughness raise reason";
CM_ SG_ 1398 TAS_frontMetricDrivesRear "Air suspension controller: front metric drives rear";
CM_ SG_ 1398 TAS_roadCondition "Air suspension controller: road condition";
CM_ SG_ 1398 TAS_bellyProtect "Air suspension controller: belly protect";
CM_ SG_ 1398 TAS_frontMetricDrivesFront "Air suspension controller: front metric drives front";
CM_ SG_ 1398 TAS_speedBumpAxleFront "Air suspension controller: speed bump axle front";
CM_ SG_ 1398 TAS_speedBumpAxleRear "Air suspension controller: speed bump axle rear";
CM_ SG_ 1398 TAS_holeProtectFL "Air suspension controller: hole protect FL";
CM_ SG_ 1398 TAS_holeProtectFR "Air suspension controller: hole protect FR";
CM_ SG_ 1398 TAS_holeProtectRL "Air suspension controller: hole protect RL";
CM_ SG_ 1398 TAS_holeProtectRR "Air suspension controller: hole protect RR";
CM_ SG_ 1398 TAS_stepProtectFL "Air suspension controller: step protect FL";
CM_ SG_ 1398 TAS_stepProtectFR "Air suspension controller: step protect FR";
CM_ SG_ 1398 TAS_stepProtectRL "Air suspension controller: step protect RL";
CM_ SG_ 1398 TAS_stepProtectRR "Air suspension controller: step protect RR";
CM_ SG_ 1398 TAS_FDUTorqueCorruptionScale "Air suspension controller: FDU torque corruption scale";
CM_ SG_ 1398 TAS_sprungMassEstimate "Air suspension controller: sprung mass estimate";
CM_ SG_ 1398 TAS_anyDamperActive "Air suspension controller: any damper active";
CM_ SG_ 1398 TAS_dampingStatesCounter "Air suspension controller: damping states counter";
CM_ SG_ 1398 TAS_dampingStatesChecksum "Air suspension controller: damping states checksum";
CM_ BO_ 1357 "Air suspension controller message: info";
CM_ SG_ 1357 TAS_infoIndex "Air suspension controller: info index";
CM_ SG_ 1357 TAS_infoBuildType "Air suspension controller: info build type";
CM_ SG_ 1357 TAS_infoBuildConfigId "Air suspension controller: info build config id";
CM_ SG_ 1357 TAS_infoHardwareId "Air suspension controller: info hardware id";
CM_ SG_ 1357 TAS_infoComponentId "Air suspension controller: info component id";
CM_ SG_ 1357 TAS_infoPcbaId "Air suspension controller: info pcba id";
CM_ SG_ 1357 TAS_infoAssemblyId "Air suspension controller: info assembly id";
CM_ SG_ 1357 TAS_infoUsageId "Air suspension controller: info usage id";
CM_ SG_ 1357 TAS_infoSubUsageId "Air suspension controller: info sub usage id";
CM_ SG_ 1357 TAS_infoAppCrc "Air suspension controller: info app crc";
CM_ SG_ 1357 TAS_infoAppGitHash "Air suspension controller: info app git hash";
CM_ SG_ 1357 TAS_infoBootGitHash "Air suspension controller: info boot git hash";
CM_ SG_ 1357 TAS_infoPlatformType "Air suspension controller: info platform type";
CM_ SG_ 1357 TAS_infoMajorVersion "Air suspension controller: info major version";
CM_ SG_ 1357 TAS_infoBranchOrigin "Air suspension controller: info branch origin";
CM_ SG_ 1357 TAS_infoMaturity "Air suspension controller: info maturity";
CM_ SG_ 1357 TAS_infoHardwareRevision "Air suspension controller: info hardware revision";
CM_ BO_ 525 "Air suspension controller message: states";
CM_ SG_ 525 TAS_levelingState "Indicates air suspension leveling state.";
CM_ SG_ 525 TAS_levelingItem "Indicates the currently active air suspension components.";
CM_ SG_ 525 TAS_pressureGallery "Current air suspension valve block gallery pressure.";
CM_ SG_ 525 TAS_pressureReservoir "Indicates the latest valid reservoir pressure.";
CM_ SG_ 525 TAS_runMode "Indicates the status of run mode.";
CM_ SG_ 525 TAS_filterMode "Indicates the status of filter mode.";
CM_ SG_ 525 TAS_compressorRun "Either an indication that the compressor is running or a request to run the air compressor";
CM_ SG_ 525 TAS_twistDetected "TAS has detected large amount of twist.";
CM_ SG_ 525 TAS_leanDetected "TAS has detected vehicle to be leaning left or right.";
CM_ SG_ 525 TAS_limpHomeMode "Indicates which limp home mode is active.";
CM_ SG_ 525 TAS_targetLevel "Indicates target ride height.";
CM_ SG_ 525 TAS_currentLevel "Indicates current ride height.";
CM_ SG_ 525 TAS_jackMode "Indicates the status of Jack mode.";
CM_ SG_ 525 TAS_reduceVehicleSpeedRequest "Air suspension controller: reduce vehicle speed request";
CM_ SG_ 525 TAS_statesCounter "Air suspension controller: states counter";
CM_ SG_ 525 TAS_statesChecksum "Air suspension controller: states checksum";
CM_ BO_ 409 "Air suspension controller message: ui adaptive activity0";
CM_ SG_ 409 TAS_adaptiveActivityFL_C "Air suspension controller: adaptive activity FL c";
CM_ SG_ 409 TAS_adaptiveActivityFL_R "Air suspension controller: adaptive activity FL r";
CM_ SG_ 409 TAS_adaptiveActivityFR_C "Air suspension controller: adaptive activity FR c";
CM_ SG_ 409 TAS_adaptiveActivityFR_R "Air suspension controller: adaptive activity FR r";
CM_ SG_ 409 TAS_adaptiveActivityRL_C "Air suspension controller: adaptive activity RL c";
CM_ SG_ 409 TAS_adaptiveActivityRL_R "Air suspension controller: adaptive activity RL r";
CM_ SG_ 409 TAS_adaptiveActivityRR_C "Air suspension controller: adaptive activity RR c";
CM_ SG_ 409 TAS_adaptiveActivityRR_R "Air suspension controller: adaptive activity RR r";
CM_ SG_ 409 TAS_uiHeightFL "Air suspension controller: ui height FL";
CM_ SG_ 409 TAS_uiHeightFR "Air suspension controller: ui height FR";
CM_ SG_ 409 TAS_uiHeightRL "Air suspension controller: ui height RL";
CM_ SG_ 409 TAS_uiHeightRR "Air suspension controller: ui height RR";
CM_ BO_ 410 "Air suspension controller message: ui adaptive activity1";
CM_ SG_ 410 TAS_bodyAccelFL "Air suspension controller: body accel FL";
CM_ SG_ 410 TAS_bodyAccelFR "Air suspension controller: body accel FR";
CM_ SG_ 410 TAS_bodyAccelRL "Air suspension controller: body accel RL";
CM_ SG_ 410 TAS_bodyAccelRR "Air suspension controller: body accel RR";
CM_ BO_ 538 "Air suspension controller message: ui control";
CM_ SG_ 538 TAS_yellowWarningLamp "Air suspension controller: yellow warning lamp";
CM_ SG_ 538 TAS_redWarningLamp "Air suspension controller: red warning lamp";
CM_ SG_ 538 TAS_veryLowAllowed "Air suspension controller: very low allowed";
CM_ SG_ 538 TAS_lowAllowed "Air suspension controller: low allowed";
CM_ SG_ 538 TAS_standardAllowed "Air suspension controller: standard allowed";
CM_ SG_ 538 TAS_highAllowed "Air suspension controller: high allowed";
CM_ SG_ 538 TAS_veryHighAllowed "Air suspension controller: very high allowed";
CM_ SG_ 538 TAS_extractAllowed "Air suspension controller: extract allowed";
CM_ SG_ 538 TAS_showSpinner "Air suspension controller: show spinner";
CM_ SG_ 538 TAS_adaptiveRideModeOverride "Air suspension controller: adaptive ride mode override";
CM_ SG_ 538 TAS_levelSelectEnabled "Air suspension controller: level select enabled";
CM_ SG_ 538 TAS_jackModeToggleEnabled "Air suspension controller: jack mode toggle enabled";
CM_ SG_ 538 TAS_adaptiveRideSelectEnabled "Air suspension controller: adaptive ride select enabled";
CM_ SG_ 538 TAS_launchModeState "Air suspension controller: launch mode state";
CM_ SG_ 538 TAS_restrictUpLevelingFalcons "Air suspension controller: restrict up leveling falcons";
CM_ SG_ 538 TAS_restrictUpLevelingTrunk "Air suspension controller: restrict up leveling trunk";
CM_ SG_ 538 TAS_restrictDownLevelingDoors "Air suspension controller: restrict down leveling doors";
CM_ SG_ 538 TAS_restrictLevelingChargeCable "Air suspension controller: restrict leveling charge cable";
CM_ SG_ 538 TAS_restrictLevelingSystemCheck "Air suspension controller: restrict leveling system check";
CM_ SG_ 538 TAS_restrictLevelingTransport "Air suspension controller: restrict leveling transport";
CM_ SG_ 538 TAS_restrictLevelingShowroom "Indication that up and down leveling are restricted while showroom mode is active.";
CM_ SG_ 538 TAS_uiControlCounter "Air suspension controller: ui control counter";
CM_ SG_ 538 TAS_uiControlChecksum "Air suspension controller: ui control checksum";
CM_ BO_ 1410 "TCU ECU message: alert log";
CM_ SG_ 1410 TCU_alertID "TCU ECU: alert ID";
CM_ SG_ 1410 TCU_alertState "TCU ECU: alert state";
CM_ SG_ 1410 TCU_w001_FailCode "TCU ECU: w001 fail code";
CM_ SG_ 1410 TCU_w002_RejCause "TCU ECU: w002 rej cause";
CM_ SG_ 1410 TCU_w003_CallFailCode "TCU ECU: w003 call fail code";
CM_ SG_ 1410 TCU_w004_MSDFailCode "TCU ECU: w004 MSD fail code";
CM_ SG_ 1410 TCU_w006_Count "TCU ECU: w006 count";
CM_ BO_ 1472 "TCU ECU message: alert matrix1";
CM_ SG_ 1472 TCU_w001_IMSRegistrationFailed "TCU ECU: w001 IMS registration failed";
CM_ SG_ 1472 TCU_w002_CellRegRejected "TCU ECU: w002 cell reg rejected";
CM_ SG_ 1472 TCU_w003_ECallFailed "TCU ECU: w003 e call failed";
CM_ SG_ 1472 TCU_w004_MSDTransmissionFailed "TCU ECU: w004 MSD transmission failed";
CM_ SG_ 1472 TCU_w005_SIMSlotError "TCU ECU: w005 SIM slot error";
CM_ SG_ 1472 TCU_w006_MpssUnavailable "TCU ECU: w006 mpss unavailable";
CM_ BO_ 1409 "TCU ECU message: log";
CM_ SG_ 1409 TCU_logMux "TCU ECU: log mux";
CM_ SG_ 1409 TCU_cpuTemp "Indicates the current temperature reported by the Central Processing Unit (CPU) in the modem application processor";
CM_ SG_ 1409 TCU_cpuUsage "Indicates the current CPU usage in percentage reported by the modem application processor";
CM_ SG_ 1409 TCU_mdmCoreTemperature "Indicates the current Communication Processor (CP) temperature reported by the modem CP.";
CM_ SG_ 1409 TCU_availableMemory "Indicates the currently available Random Access Memory in the modem application processor";
CM_ SG_ 1409 TCU_pwm "Indicates the active Pulse Width Modulation (PWM) duty cycle applied to the modem fan.";
CM_ SG_ 1409 TCU_pwmcap "Indicates the active Pulse Width Modulation (PWM) duty cycle restriciton applied to the modem fan.";
CM_ SG_ 1409 TCU_totalResumes "Indicates the total amount of times the modem has been resumed";
CM_ SG_ 1409 TCU_mdmUplinkQueueSize "TCU ECU: mdm uplink queue size";
CM_ SG_ 1409 TCU_mdmRSRP "TCU ECU: mdm RSRP";
CM_ SG_ 1409 TCU_mdmSINR "TCU ECU: mdm SINR";
CM_ SG_ 1409 TCU_mdmUplinkAllowedRate "TCU ECU: mdm uplink allowed rate";
CM_ SG_ 1409 TCU_mdmUplinkAvgRage "TCU ECU: mdm uplink avg rage";
CM_ SG_ 1409 TCU_mdmServiceState "TCU ECU: mdm service state";
CM_ SG_ 1409 TCU_mdmIMSStatus "Indicates the current IP Multimedia System (IMS) registration state.";
CM_ SG_ 1409 TCU_mdmSIMStatus "TCU ECU: mdm SIM status";
CM_ SG_ 1409 TCU_mdmBusyActive "Reports whether the modem busy service is active on the modem application processor.";
CM_ BO_ 1408 "TCU ECU message: status";
CM_ SG_ 1408 TCU_statusMux "TCU ECU: status mux";
CM_ SG_ 1408 TCU_wakeUpReason "TCU ECU: wake up reason";
CM_ SG_ 1408 TCU_tcuCmdId "TCU ECU: tcu cmd id";
CM_ SG_ 1408 TCU_goingToSleep "TCU ECU: going to sleep";
CM_ BO_ 879 "Tire pressure monitoring message: status c";
CM_ SG_ 879 TPMS_c_globalHardWarning "Tire pressure monitoring: c global hard warning";
CM_ SG_ 879 TPMS_c_globalSoftWarning "Tire pressure monitoring: c global soft warning";
CM_ SG_ 879 TPMS_systemMalfunction "Tire pressure monitoring: system malfunction";
CM_ SG_ 879 TPMS_WA_version "Tire pressure monitoring: WA version";
CM_ SG_ 879 TPMS_globalDeltaPressure "Tire pressure monitoring: global delta pressure";
CM_ SG_ 879 TPMS_newSensorLearnt "Tire pressure monitoring: new sensor learnt";
CM_ SG_ 879 TPMS_softWarningRR "Tire pressure monitoring: soft warning RR";
CM_ SG_ 879 TPMS_hardWarningRR "Tire pressure monitoring: hard warning RR";
CM_ SG_ 879 TPMS_softWarningRL "Tire pressure monitoring: soft warning RL";
CM_ SG_ 879 TPMS_hardWarningRL "Tire pressure monitoring: hard warning RL";
CM_ SG_ 879 TPMS_softWarningFR "Tire pressure monitoring: soft warning FR";
CM_ SG_ 879 TPMS_hardWarningFR "Tire pressure monitoring: hard warning FR";
CM_ SG_ 879 TPMS_softWarningFL "Tire pressure monitoring: soft warning FL";
CM_ SG_ 879 TPMS_hardWarningFL "Tire pressure monitoring: hard warning FL";
CM_ SG_ 879 TPMS_learningStatus "Monitors Tire Pressure Monitoring System (TPMS) Learn Status and evaluates issues.";
CM_ SG_ 879 TPMS_localisationStatus "Monitors Tire Pressure Monitoring System (TPMS) Localization Status and evaluates issues.";
CM_ SG_ 879 TPMS_deltaPressWarningFL "Tire pressure monitoring: delta press warning FL";
CM_ SG_ 879 TPMS_deltaPressWarningFR "Tire pressure monitoring: delta press warning FR";
CM_ SG_ 879 TPMS_deltaPressWarningRL "Tire pressure monitoring: delta press warning RL";
CM_ SG_ 879 TPMS_deltaPressWarningRR "Tire pressure monitoring: delta press warning RR";
CM_ SG_ 879 TPMS_sensorNoResponseFL "Count of times Front Left sensor did not respond to message";
CM_ SG_ 879 TPMS_sensorNoResponseFR "Count of times Front Right sensor did not respond to message";
CM_ SG_ 879 TPMS_sensorNoResponseRL "Count of times Rear Left sensor did not respond to message";
CM_ SG_ 879 TPMS_sensorNoResponseRR "Count of times Rear Right sensor did not respond to message";
CM_ SG_ 879 TPMS_sensorThermShutdownFL "Tire pressure monitoring: sensor therm shutdown FL";
CM_ SG_ 879 TPMS_sensorThermShutdownFR "Tire pressure monitoring: sensor therm shutdown FR";
CM_ SG_ 879 TPMS_sensorThermShutdownRL "Tire pressure monitoring: sensor therm shutdown RL";
CM_ SG_ 879 TPMS_sensorThermShutdownRR "Tire pressure monitoring: sensor therm shutdown RR";
CM_ SG_ 879 TPMS_sensorBatteryLowFL "Tracks near end of life sensor batteries in the fleet.";
CM_ SG_ 879 TPMS_sensorBatteryLowFR "Tracks near end of life sensor batteries in the fleet.";
CM_ SG_ 879 TPMS_sensorBatteryLowRL "Tracks near end of life sensor batteries in the fleet.";
CM_ SG_ 879 TPMS_sensorBatteryLowRR "Tracks near end of life sensor batteries in the fleet.";
CM_ SG_ 879 TPMS_sensorDefectiveFL "Tracks malfunctioning sensors in the fleet.";
CM_ SG_ 879 TPMS_sensorDefectiveFR "Tracks malfunctioning sensors in the fleet.";
CM_ SG_ 879 TPMS_sensorDefectiveRL "Tracks malfunctioning sensors in the fleet.";
CM_ SG_ 879 TPMS_sensorDefectiveRR "Tracks malfunctioning sensors in the fleet.";
CM_ SG_ 879 TPMS_ecuUnderVoltage "Tire pressure monitoring: ecu under voltage";
CM_ SG_ 879 TPMS_ecuOverVoltage "Tire pressure monitoring: ecu over voltage";
CM_ SG_ 879 TPMS_ecuRamRomNvMFail "Tire pressure monitoring: ecu ram rom nv m fail";
CM_ SG_ 879 TPMS_rfReceiverFail "Tire pressure monitoring: rf receiver fail";
CM_ SG_ 879 TPMS_wheelPulseMissing "Tire pressure monitoring: wheel pulse missing";
CM_ SG_ 879 TPMS_vehicleSpeedFail "Tire pressure monitoring: vehicle speed fail";
CM_ SG_ 879 TPMS_externalTemperatureFail "Tire pressure monitoring: external temperature fail";
CM_ SG_ 879 TPMS_eolNotCompleted "Monitors sensor completion of End of Line (EOL) routine.";
CM_ SG_ 879 TPMS_rcpFront "Front tire recommended cold pressure";
CM_ SG_ 879 TPMS_rcpRear "Rear tire recommended cold pressure";
CM_ BO_ 802 "Tire pressure monitoring message: data";
CM_ SG_ 802 TPMS_pressureFL "front left tire pressure";
CM_ SG_ 802 TPMS_temperatureFL "front left tire temperature";
CM_ SG_ 802 TPMS_pressureFR "front right tire pressure";
CM_ SG_ 802 TPMS_temperatureFR "front right tire temperature";
CM_ SG_ 802 TPMS_pressureRL "rear left tire pressure";
CM_ SG_ 802 TPMS_temperatureRL "rear left tire temperature";
CM_ SG_ 802 TPMS_pressureRR "rear right tire pressure";
CM_ SG_ 802 TPMS_temperatureRR "rear right tire temperature";
CM_ BO_ 1519 "Tire pressure monitoring message: info";
CM_ SG_ 1519 TPMS_infoIndex "Tire pressure monitoring: info index";
CM_ SG_ 1519 TPMS_infoComponentID "Tire pressure monitoring: info component ID";
CM_ SG_ 1519 TPMS_infoPcbaID "Tire pressure monitoring: info pcba ID";
CM_ SG_ 1519 TPMS_infoAssemblyID "Tire pressure monitoring: info assembly ID";
CM_ SG_ 1519 TPMS_infoUsageID "Tire pressure monitoring: info usage ID";
CM_ SG_ 1519 TPMS_infoApplicationCRC "Tire pressure monitoring: info application CRC";
CM_ SG_ 1519 TPMS_infoBootUdsProtoVersion "Tire pressure monitoring: info boot uds proto version";
CM_ SG_ 1519 TPMS_infoBootloaderCRC "Tire pressure monitoring: info bootloader CRC";
CM_ BO_ 1298 "TRCM ECU message: alert log";
CM_ SG_ 1298 TRCM_alertID "TRCM ECU: alert ID";
CM_ SG_ 1298 TRCM_alertState "TRCM ECU: alert state";
CM_ SG_ 1298 TRCM_a015_NVMMMemOverflow "TRCM ECU: a015 NVMM mem overflow";
CM_ SG_ 1298 TRCM_a015_NVMMFilesystemError "TRCM ECU: a015 NVMM filesystem error";
CM_ SG_ 1298 TRCM_a015_NVMMRecordIDError "TRCM ECU: a015 NVMM record ID error";
CM_ SG_ 1298 TRCM_a057_VEH_cpControl "TRCM ECU: a057 VEH cp control";
CM_ SG_ 1298 TRCM_a059_voltageDrop "TRCM ECU: a059 voltage drop";
CM_ SG_ 1298 TRCM_a059_resistanceEstimate "TRCM ECU: a059 resistance estimate";
CM_ SG_ 1298 TRCM_a059_current "TRCM ECU: a059 current";
CM_ SG_ 1298 TRCM_a063_switchChannel "TRCM ECU: a063 switch channel";
CM_ SG_ 1298 TRCM_a063_switchType "TRCM ECU: a063 switch type";
CM_ SG_ 1298 TRCM_a063_ADCVoltage "TRCM ECU: a063 ADC voltage";
CM_ SG_ 1298 TRCM_a063_disconnected "TRCM ECU: a063 disconnected";
CM_ SG_ 1298 TRCM_a063_indeterminate "TRCM ECU: a063 indeterminate";
CM_ SG_ 1298 TRCM_a063_stuckActive "TRCM ECU: a063 stuck active";
CM_ SG_ 1298 TRCM_a063_faulted "TRCM ECU: a063 faulted";
CM_ SG_ 1298 TRCM_a082_RIPC_epbPrivateState "TRCM ECU: a082 RIPC epb private state";
CM_ SG_ 1298 TRCM_a082_RIPC_remoteHSD "TRCM ECU: a082 RIPC remote HSD";
CM_ SG_ 1298 TRCM_a082_RIPC_railStatus "TRCM ECU: a082 RIPC rail status";
CM_ SG_ 1298 TRCM_a082_RIPC_remoteMux "TRCM ECU: a082 RIPC remote mux";
CM_ SG_ 1298 TRCM_a083_LIPC_epbPrivateState "TRCM ECU: a083 LIPC epb private state";
CM_ SG_ 1298 TRCM_a083_LIPC_remoteHSD "TRCM ECU: a083 LIPC remote HSD";
CM_ SG_ 1298 TRCM_a083_LIPC_railStatus "TRCM ECU: a083 LIPC rail status";
CM_ SG_ 1298 TRCM_a083_LIPC_HSDFaults "TRCM ECU: a083 LIPC HSD faults";
CM_ SG_ 1298 TRCM_a084_CH_StatusC "TRCM ECU: a084 CH status c";
CM_ SG_ 1298 TRCM_a085_PARTY_buttonStatus "TRCM ECU: a085 PARTY button status";
CM_ SG_ 1298 TRCM_a086_VEH_LVBMS_statusHigh "TRCM ECU: a086 VEH LVBMS status high";
CM_ SG_ 1298 TRCM_a086_VEH_LVBMS_statusLow "TRCM ECU: a086 VEH LVBMS status low";
CM_ SG_ 1298 TRCM_a086_VEH_status "TRCM ECU: a086 VEH status";
CM_ SG_ 1298 TRCM_a086_VEH_12VBatteryStatus "TRCM ECU: a086 VEH 12 v battery status";
CM_ SG_ 1298 TRCM_a086_VEH_LVPowerState "TRCM ECU: a086 VEH LV power state";
CM_ SG_ 1298 TRCM_a086_VEH_lightStatus "TRCM ECU: a086 VEH light status";
CM_ SG_ 1298 TRCM_a086_VEH_systemStatus "TRCM ECU: a086 VEH system status";
CM_ SG_ 1298 TRCM_a086_VEH_thermalStatus "TRCM ECU: a086 VEH thermal status";
CM_ SG_ 1298 TRCM_a086_VEH_vehNm "TRCM ECU: a086 VEH veh nm";
CM_ SG_ 1298 TRCM_a087_VEH_temperature "TRCM ECU: a087 VEH temperature";
CM_ SG_ 1298 TRCM_a087_VEH_thermalControl "TRCM ECU: a087 VEH thermal control";
CM_ SG_ 1298 TRCM_a087_VEH_torque "TRCM ECU: a087 VEH torque";
CM_ SG_ 1298 TRCM_a087_VEH_status "TRCM ECU: a087 VEH status";
CM_ SG_ 1298 TRCM_a087_PARTY_torque "TRCM ECU: a087 PARTY torque";
CM_ SG_ 1298 TRCM_a087_PARTY_status "TRCM ECU: a087 PARTY status";
CM_ SG_ 1298 TRCM_a087_PARTY_temperature "TRCM ECU: a087 PARTY temperature";
CM_ SG_ 1298 TRCM_a087_PARTY_thermalControl "TRCM ECU: a087 PARTY thermal control";
CM_ SG_ 1298 TRCM_a088_VEH_temperature "TRCM ECU: a088 VEH temperature";
CM_ SG_ 1298 TRCM_a088_VEH_thermalControl "TRCM ECU: a088 VEH thermal control";
CM_ SG_ 1298 TRCM_a088_VEH_torque "TRCM ECU: a088 VEH torque";
CM_ SG_ 1298 TRCM_a088_VEH_status "TRCM ECU: a088 VEH status";
CM_ SG_ 1298 TRCM_a088_PARTY_torque "TRCM ECU: a088 PARTY torque";
CM_ SG_ 1298 TRCM_a088_PARTY_status "TRCM ECU: a088 PARTY status";
CM_ SG_ 1298 TRCM_a088_PARTY_temperature "TRCM ECU: a088 PARTY temperature";
CM_ SG_ 1298 TRCM_a088_PARTY_thermalControl "TRCM ECU: a088 PARTY thermal control";
CM_ SG_ 1298 TRCM_a089_PARTY_party1 "TRCM ECU: a089 PARTY party1";
CM_ SG_ 1298 TRCM_a089_PARTY_status "TRCM ECU: a089 PARTY status";
CM_ SG_ 1298 TRCM_a089_VEH_status "TRCM ECU: a089 VEH status";
CM_ SG_ 1298 TRCM_a089_BDY_party1 "TRCM ECU: a089 BDY party1";
CM_ SG_ 1298 TRCM_a089_BDY_status "TRCM ECU: a089 BDY status";
CM_ SG_ 1298 TRCM_a089_CH_status "TRCM ECU: a089 CH status";
CM_ SG_ 1298 TRCM_a089_CH_party1 "TRCM ECU: a089 CH party1";
CM_ SG_ 1298 TRCM_a089_CH_party3 "TRCM ECU: a089 CH party3";
CM_ SG_ 1298 TRCM_a089_VEH_party1 "TRCM ECU: a089 VEH party1";
CM_ SG_ 1298 TRCM_a089_VEH_party3 "TRCM ECU: a089 VEH party3";
CM_ SG_ 1298 TRCM_a091_VEH_faultsAndExtras "TRCM ECU: a091 VEH faults and extras";
CM_ SG_ 1298 TRCM_a091_VEH_info "TRCM ECU: a091 VEH info";
CM_ SG_ 1298 TRCM_a091_VEH_state "TRCM ECU: a091 VEH state";
CM_ SG_ 1298 TRCM_a092_VEH_restraintStatus "TRCM ECU: a092 VEH restraint status";
CM_ SG_ 1298 TRCM_a092_VEH_switchStatus "TRCM ECU: a092 VEH switch status";
CM_ SG_ 1298 TRCM_a092_VEH_seatStatus2 "TRCM ECU: a092 VEH seat status2";
CM_ SG_ 1298 TRCM_a092_VEH_vehNm "TRCM ECU: a092 VEH veh nm";
CM_ SG_ 1298 TRCM_a093_VEH_restraintStatus "TRCM ECU: a093 VEH restraint status";
CM_ SG_ 1298 TRCM_a093_VEH_switchStatus "TRCM ECU: a093 VEH switch status";
CM_ SG_ 1298 TRCM_a093_VEH_seatStatus2 "TRCM ECU: a093 VEH seat status2";
CM_ SG_ 1298 TRCM_a093_VEH_vehNm "TRCM ECU: a093 VEH veh nm";
CM_ SG_ 1298 TRCM_a094_VEH_sysStatus "TRCM ECU: a094 VEH sys status";
CM_ SG_ 1298 TRCM_a094_PARTY_sysStatus "TRCM ECU: a094 PARTY sys status";
CM_ SG_ 1298 TRCM_a095_PT_ptNm "TRCM ECU: a095 PT pt nm";
CM_ SG_ 1298 TRCM_a095_PT_status "TRCM ECU: a095 PT status";
CM_ SG_ 1298 TRCM_a096_VEH_status "TRCM ECU: a096 VEH status";
CM_ SG_ 1298 TRCM_a096_CH_status "TRCM ECU: a096 CH status";
CM_ SG_ 1298 TRCM_a098_CH_torque "TRCM ECU: a098 CH torque";
CM_ SG_ 1298 TRCM_a098_VEH_hvStatus "TRCM ECU: a098 VEH hv status";
CM_ SG_ 1298 TRCM_a098_VEH_status "TRCM ECU: a098 VEH status";
CM_ SG_ 1298 TRCM_a098_VEH_thermalControl "TRCM ECU: a098 VEH thermal control";
CM_ SG_ 1298 TRCM_a098_VEH_temperature "TRCM ECU: a098 VEH temperature";
CM_ SG_ 1298 TRCM_a098_VEH_torque "TRCM ECU: a098 VEH torque";
CM_ SG_ 1298 TRCM_a098_PARTY_status "TRCM ECU: a098 PARTY status";
CM_ SG_ 1298 TRCM_a098_PARTY_temperature "TRCM ECU: a098 PARTY temperature";
CM_ SG_ 1298 TRCM_a098_PARTY_thermalControl "TRCM ECU: a098 PARTY thermal control";
CM_ SG_ 1298 TRCM_a098_PARTY_torque "TRCM ECU: a098 PARTY torque";
CM_ SG_ 1298 TRCM_a098_PT_thermalControl "TRCM ECU: a098 PT thermal control";
CM_ SG_ 1298 TRCM_a098_PT_temperature "TRCM ECU: a098 PT temperature";
CM_ SG_ 1298 TRCM_a099_VEH_oocStatus "TRCM ECU: a099 VEH ooc status";
CM_ SG_ 1298 TRCM_a100_VEH "TRCM ECU: a100 VEH";
CM_ SG_ 1298 TRCM_a100_PARTY "TRCM ECU: a100 PARTY";
CM_ SG_ 1298 TRCM_a100_PT "TRCM ECU: a100 PT";
CM_ SG_ 1298 TRCM_a100_CH "TRCM ECU: a100 CH";
CM_ SG_ 1298 TRCM_a100_OBD "TRCM ECU: a100 OBD";
CM_ SG_ 1298 TRCM_a101_VEH_state "TRCM ECU: a101 VEH state";
CM_ SG_ 1298 TRCM_a101_PARTY_locState "TRCM ECU: a101 PARTY loc state";
CM_ SG_ 1298 TRCM_a101_LIPC_externalWatchdogH "TRCM ECU: a101 LIPC external watchdog heart beat";
CM_ SG_ 1298 TRCM_a101_VEH_locState "TRCM ECU: a101 VEH loc state";
CM_ SG_ 1298 TRCM_a101_BDY_locState "TRCM ECU: a101 BDY loc state";
CM_ SG_ 1298 TRCM_a102_VEH_faultsAndExtras "TRCM ECU: a102 VEH faults and extras";
CM_ SG_ 1298 TRCM_a102_VEH_feedbackStatus "TRCM ECU: a102 VEH feedback status";
CM_ SG_ 1298 TRCM_a102_VEH_sensorStatus "TRCM ECU: a102 VEH sensor status";
CM_ SG_ 1298 TRCM_a102_VEH_rods "TRCM ECU: a102 VEH rods";
CM_ SG_ 1298 TRCM_a103_VEH_hvsNm "TRCM ECU: a103 VEH hvs nm";
CM_ SG_ 1298 TRCM_a103_VEH_vehNm "TRCM ECU: a103 VEH veh nm";
CM_ SG_ 1298 TRCM_a103_VEH_status "TRCM ECU: a103 VEH status";
CM_ SG_ 1298 TRCM_a103_PT_ptNm "TRCM ECU: a103 PT pt nm";
CM_ SG_ 1298 TRCM_a103_PT_status "TRCM ECU: a103 PT status";
CM_ SG_ 1298 TRCM_a103_VEH_evseStatus "TRCM ECU: a103 VEH evse status";
CM_ SG_ 1298 TRCM_a105_VEH_states "TRCM ECU: a105 VEH states";
CM_ SG_ 1298 TRCM_a105_VEH_chNm "TRCM ECU: a105 VEH ch nm";
CM_ SG_ 1298 TRCM_a105_VEH_dampingStates "TRCM ECU: a105 VEH damping states";
CM_ SG_ 1298 TRCM_a106_VEH_dcdcStatus "TRCM ECU: a106 VEH dcdc status";
CM_ SG_ 1298 TRCM_a106_VEH_thermalControl "TRCM ECU: a106 VEH thermal control";
CM_ SG_ 1298 TRCM_a106_VEH_thermalInterface "TRCM ECU: a106 VEH thermal interface";
CM_ SG_ 1298 TRCM_a106_VEH_dcdcRailStatus "TRCM ECU: a106 VEH dcdc rail status";
CM_ SG_ 1298 TRCM_a106_CH_dcdcRailStatus "TRCM ECU: a106 CH dcdc rail status";
CM_ SG_ 1298 TRCM_a106_CH_alertMatrix "TRCM ECU: a106 CH alert matrix";
CM_ SG_ 1298 TRCM_a107_VEH_hvsNm "TRCM ECU: a107 VEH hvs nm";
CM_ SG_ 1298 TRCM_a107_VEH_vehNm "TRCM ECU: a107 VEH veh nm";
CM_ SG_ 1298 TRCM_a107_VEH_status "TRCM ECU: a107 VEH status";
CM_ SG_ 1298 TRCM_a107_VEH_thermalStatus "TRCM ECU: a107 VEH thermal status";
CM_ SG_ 1298 TRCM_a107_VEH_thermalStatus2 "TRCM ECU: a107 VEH thermal status2";
CM_ SG_ 1298 TRCM_a107_VEH_bmbMinMax "TRCM ECU: a107 VEH bmb min max";
CM_ SG_ 1298 TRCM_a107_VEH_powerAvailable "TRCM ECU: a107 VEH power available";
CM_ SG_ 1298 TRCM_a107_PT_ptNm "TRCM ECU: a107 PT pt nm";
CM_ SG_ 1298 TRCM_a107_PT_status "TRCM ECU: a107 PT status";
CM_ SG_ 1298 TRCM_a107_PT_thermalStatus "TRCM ECU: a107 PT thermal status";
CM_ SG_ 1298 TRCM_a107_PT_socStatus "TRCM ECU: a107 PT soc status";
CM_ SG_ 1298 TRCM_a107_VEH_socStatus "TRCM ECU: a107 VEH soc status";
CM_ SG_ 1298 TRCM_a107_VEH_packConfig "TRCM ECU: a107 VEH pack config";
CM_ SG_ 1298 TRCM_a107_VEH_energyStatus "TRCM ECU: a107 VEH energy status";
CM_ SG_ 1298 TRCM_a107_VEH_chargeInfo "TRCM ECU: a107 VEH charge info";
CM_ SG_ 1298 TRCM_a108_VEH_hvStatus "TRCM ECU: a108 VEH hv status";
CM_ SG_ 1298 TRCM_a108_VEH_temperature "TRCM ECU: a108 VEH temperature";
CM_ SG_ 1298 TRCM_a108_VEH_thermalControl "TRCM ECU: a108 VEH thermal control";
CM_ SG_ 1298 TRCM_a108_VEH_torque "TRCM ECU: a108 VEH torque";
CM_ SG_ 1298 TRCM_a108_VEH_status "TRCM ECU: a108 VEH status";
CM_ SG_ 1298 TRCM_a108_PARTY_torque "TRCM ECU: a108 PARTY torque";
CM_ SG_ 1298 TRCM_a108_PARTY_status "TRCM ECU: a108 PARTY status";
CM_ SG_ 1298 TRCM_a108_PARTY_temperature "TRCM ECU: a108 PARTY temperature";
CM_ SG_ 1298 TRCM_a108_PARTY_thermalControl "TRCM ECU: a108 PARTY thermal control";
CM_ SG_ 1298 TRCM_a108_PT_temperature "TRCM ECU: a108 PT temperature";
CM_ SG_ 1298 TRCM_a108_PT_thermalControl "TRCM ECU: a108 PT thermal control";
CM_ SG_ 1298 TRCM_a109_PARTY_status "TRCM ECU: a109 PARTY status";
CM_ SG_ 1298 TRCM_a109_PARTY_inertial2 "TRCM ECU: a109 PARTY inertial2";
CM_ SG_ 1298 TRCM_a109_PARTY_nearDeploy "TRCM ECU: a109 PARTY near deploy";
CM_ SG_ 1298 TRCM_a109_PARTY_collision "TRCM ECU: a109 PARTY collision";
CM_ SG_ 1298 TRCM_a109_VEH_status "TRCM ECU: a109 VEH status";
CM_ SG_ 1298 TRCM_a109_VEH_imuOffsets "TRCM ECU: a109 VEH imu offsets";
CM_ SG_ 1298 TRCM_a109_PARTY_inertial1 "TRCM ECU: a109 PARTY inertial1";
CM_ SG_ 1298 TRCM_a109_BDY_imuOffsets "TRCM ECU: a109 BDY imu offsets";
CM_ SG_ 1298 TRCM_a109_BDY_inertial1 "TRCM ECU: a109 BDY inertial1";
CM_ SG_ 1298 TRCM_a109_BDY_inertial2 "TRCM ECU: a109 BDY inertial2";
CM_ SG_ 1298 TRCM_a109_BDY_status "TRCM ECU: a109 BDY status";
CM_ SG_ 1298 TRCM_a109_VEH_inertial1 "TRCM ECU: a109 VEH inertial1";
CM_ SG_ 1298 TRCM_a109_VEH_inertial2 "TRCM ECU: a109 VEH inertial2";
CM_ SG_ 1298 TRCM_a109_CH_inertial1 "TRCM ECU: a109 CH inertial1";
CM_ SG_ 1298 TRCM_a109_CH_inertial2 "TRCM ECU: a109 CH inertial2";
CM_ SG_ 1298 TRCM_a109_CH_status "TRCM ECU: a109 CH status";
CM_ SG_ 1298 TRCM_a110_VEH_carState "TRCM ECU: a110 VEH car state";
CM_ SG_ 1298 TRCM_a110_VEH_carConfig "TRCM ECU: a110 VEH car config";
CM_ SG_ 1298 TRCM_a110_VEH_time "TRCM ECU: a110 VEH time";
CM_ SG_ 1298 TRCM_a110_VEH_updateStatus "TRCM ECU: a110 VEH update status";
CM_ SG_ 1298 TRCM_a110_VEH_vehNm "TRCM ECU: a110 VEH veh nm";
CM_ SG_ 1298 TRCM_a110_VEH_mismatchFault "TRCM ECU: a110 VEH mismatch fault";
CM_ SG_ 1298 TRCM_a110_VEH_vin "TRCM ECU: a110 VEH vin";
CM_ SG_ 1298 TRCM_a110_VEH_bmpDebug "TRCM ECU: a110 VEH bmp debug";
CM_ SG_ 1298 TRCM_a110_VEH_gearControl "TRCM ECU: a110 VEH gear control";
CM_ SG_ 1298 TRCM_a110_VEH_canLogAvailability "TRCM ECU: a110 VEH can log availability";
CM_ SG_ 1298 TRCM_a110_CH_airbagCutoffStatus "TRCM ECU: a110 CH airbag cutoff status";
CM_ SG_ 1298 TRCM_a110_CH_carConfig "TRCM ECU: a110 CH car config";
CM_ SG_ 1298 TRCM_a110_CH_carState "TRCM ECU: a110 CH car state";
CM_ SG_ 1298 TRCM_a110_CH_vin "TRCM ECU: a110 CH vin";
CM_ SG_ 1298 TRCM_a110_CH_chNm "TRCM ECU: a110 CH ch nm";
CM_ SG_ 1298 TRCM_a110_CH_epochTimeGtw "TRCM ECU: a110 CH epoch time gtw";
CM_ SG_ 1298 TRCM_a111_VEH_internalStatus "TRCM ECU: a111 VEH internal status";
CM_ SG_ 1298 TRCM_a111_VEH_status "TRCM ECU: a111 VEH status";
CM_ SG_ 1298 TRCM_a111_VEH_vehNm "TRCM ECU: a111 VEH veh nm";
CM_ SG_ 1298 TRCM_a111_RIPC_LVPowerState "TRCM ECU: a111 RIPC LV power state";
CM_ SG_ 1298 TRCM_a111_RIPC_epbPrivateState "TRCM ECU: a111 RIPC epb private state";
CM_ SG_ 1298 TRCM_a111_RIPC_railStatus "TRCM ECU: a111 RIPC rail status";
CM_ SG_ 1298 TRCM_a111_RIPC_remoteADC "TRCM ECU: a111 RIPC remote ADC";
CM_ SG_ 1298 TRCM_a111_RIPC_switchStatus "TRCM ECU: a111 RIPC switch status";
CM_ SG_ 1298 TRCM_a111_VEH_LVPowerState "TRCM ECU: a111 VEH LV power state";
CM_ SG_ 1298 TRCM_a111_VEH_seatStatus "TRCM ECU: a111 VEH seat status";
CM_ SG_ 1298 TRCM_a111_PARTY_status "TRCM ECU: a111 PARTY status";
CM_ SG_ 1298 TRCM_a111_CH_status "TRCM ECU: a111 CH status";
CM_ SG_ 1298 TRCM_a112_VEH_internalStatus "TRCM ECU: a112 VEH internal status";
CM_ SG_ 1298 TRCM_a112_VEH_status "TRCM ECU: a112 VEH status";
CM_ SG_ 1298 TRCM_a112_VEH_vehNm "TRCM ECU: a112 VEH veh nm";
CM_ SG_ 1298 TRCM_a112_LIPC_LVPowerState "TRCM ECU: a112 LIPC LV power state";
CM_ SG_ 1298 TRCM_a112_LIPC_epbPrivateState "TRCM ECU: a112 LIPC epb private state";
CM_ SG_ 1298 TRCM_a112_LIPC_railStatus "TRCM ECU: a112 LIPC rail status";
CM_ SG_ 1298 TRCM_a112_LIPC_remoteADC "TRCM ECU: a112 LIPC remote ADC";
CM_ SG_ 1298 TRCM_a112_LIPC_switchStatus "TRCM ECU: a112 LIPC switch status";
CM_ SG_ 1298 TRCM_a112_VEH_LVPowerState "TRCM ECU: a112 VEH LV power state";
CM_ SG_ 1298 TRCM_a112_PARTY_status "TRCM ECU: a112 PARTY status";
CM_ SG_ 1298 TRCM_a112_CH_status "TRCM ECU: a112 CH status";
CM_ SG_ 1298 TRCM_a114_PARTY_status "TRCM ECU: a114 PARTY status";
CM_ SG_ 1298 TRCM_a114_PARTY_wheelSpeeds "TRCM ECU: a114 PARTY wheel speeds";
CM_ SG_ 1298 TRCM_a114_VEH_wheelSpeeds "TRCM ECU: a114 VEH wheel speeds";
CM_ SG_ 1298 TRCM_a114_CH_wheelSpeeds "TRCM ECU: a114 CH wheel speeds";
CM_ SG_ 1298 TRCM_a114_PARTY_party3 "TRCM ECU: a114 PARTY party3";
CM_ SG_ 1298 TRCM_a114_VEH_party3 "TRCM ECU: a114 VEH party3";
CM_ SG_ 1298 TRCM_a114_VEH_status "TRCM ECU: a114 VEH status";
CM_ SG_ 1298 TRCM_a114_PARTY_wheelRotation "TRCM ECU: a114 PARTY wheel rotation";
CM_ SG_ 1298 TRCM_a114_CH_wheelRotation "TRCM ECU: a114 CH wheel rotation";
CM_ SG_ 1298 TRCM_a114_VEH_wheelRotation "TRCM ECU: a114 VEH wheel rotation";
CM_ SG_ 1298 TRCM_a114_PARTY_brakeTorque "TRCM ECU: a114 PARTY brake torque";
CM_ SG_ 1298 TRCM_a114_PARTY_offsets "TRCM ECU: a114 PARTY offsets";
CM_ SG_ 1298 TRCM_a114_BDY_offsets "TRCM ECU: a114 BDY offsets";
CM_ SG_ 1298 TRCM_a114_BDY_party3 "TRCM ECU: a114 BDY party3";
CM_ SG_ 1298 TRCM_a114_BDY_status "TRCM ECU: a114 BDY status";
CM_ SG_ 1298 TRCM_a114_BDY_wheelRotation "TRCM ECU: a114 BDY wheel rotation";
CM_ SG_ 1298 TRCM_a114_BDY_wheelSpeeds "TRCM ECU: a114 BDY wheel speeds";
CM_ SG_ 1298 TRCM_a114_CH_party1 "TRCM ECU: a114 CH party1";
CM_ SG_ 1298 TRCM_a114_CH_party3 "TRCM ECU: a114 CH party3";
CM_ SG_ 1298 TRCM_a114_CH_status "TRCM ECU: a114 CH status";
CM_ SG_ 1298 TRCM_a115_VEH_vehNm "TRCM ECU: a115 VEH veh nm";
CM_ SG_ 1298 TRCM_a115_VEH_authentication "TRCM ECU: a115 VEH authentication";
CM_ SG_ 1298 TRCM_a115_VEH_BLEResetRequest "TRCM ECU: a115 VEH BLE reset request";
CM_ SG_ 1298 TRCM_a115_VEH_requests "TRCM ECU: a115 VEH requests";
CM_ SG_ 1298 TRCM_a115_VEH_requests2 "TRCM ECU: a115 VEH requests2";
CM_ SG_ 1298 TRCM_a115_REM_authentication "TRCM ECU: a115 REM authentication";
CM_ SG_ 1298 TRCM_a115_UI_corianderVehicleCon "TRCM ECU: a115 UI coriander vehicle control";
CM_ SG_ 1298 TRCM_a115_CH_TPMSDisplay "TRCM ECU: a115 CH TPMS display";
CM_ SG_ 1298 TRCM_a116_PARTY_epbmStatus "TRCM ECU: a116 PARTY epbm status";
CM_ SG_ 1298 TRCM_a116_VEH_vehNm "TRCM ECU: a116 VEH veh nm";
CM_ SG_ 1298 TRCM_a116_VEH_hvacRequest "TRCM ECU: a116 VEH hvac request";
CM_ SG_ 1298 TRCM_a116_VEH_hvacStatus "TRCM ECU: a116 VEH hvac status";
CM_ SG_ 1298 TRCM_a116_VEH_LVPowerState "TRCM ECU: a116 VEH LV power state";
CM_ SG_ 1298 TRCM_a116_VEH_lightStatus "TRCM ECU: a116 VEH light status";
CM_ SG_ 1298 TRCM_a116_VEH_seatStatus "TRCM ECU: a116 VEH seat status";
CM_ SG_ 1298 TRCM_a116_VEH_thsStatus "TRCM ECU: a116 VEH ths status";
CM_ SG_ 1298 TRCM_a116_VEH_doorStatus "TRCM ECU: a116 VEH door status";
CM_ SG_ 1298 TRCM_a116_VEH_seatHeatStatus "TRCM ECU: a116 VEH seat heat status";
CM_ SG_ 1298 TRCM_a116_VEH_restraintStatus "TRCM ECU: a116 VEH restraint status";
CM_ SG_ 1298 TRCM_a116_VEH_switchStatus "TRCM ECU: a116 VEH switch status";
CM_ SG_ 1298 TRCM_a116_VEH_logging1Hz "TRCM ECU: a116 VEH logging1 hz";
CM_ SG_ 1298 TRCM_a116_VEH_seatStatus2 "TRCM ECU: a116 VEH seat status2";
CM_ SG_ 1298 TRCM_a116_VEH_status "TRCM ECU: a116 VEH status";
CM_ SG_ 1298 TRCM_a116_VEH_thermalCommand "TRCM ECU: a116 VEH thermal command";
CM_ SG_ 1298 TRCM_a116_VEH_windowStatus "TRCM ECU: a116 VEH window status";
CM_ SG_ 1298 TRCM_a116_PARTY_restraintStatus "TRCM ECU: a116 PARTY restraint status";
CM_ SG_ 1298 TRCM_a116_PARTY_doorStatus "TRCM ECU: a116 PARTY door status";
CM_ SG_ 1298 TRCM_a116_BDY_epbmStatus "TRCM ECU: a116 BDY epbm status";
CM_ SG_ 1298 TRCM_a116_BDY_restraintStatus "TRCM ECU: a116 BDY restraint status";
CM_ SG_ 1298 TRCM_a117_BDY_epbmStatus "TRCM ECU: a117 BDY epbm status";
CM_ SG_ 1298 TRCM_a117_BDY_restraintStatus "TRCM ECU: a117 BDY restraint status";
CM_ SG_ 1298 TRCM_a117_VEH_prndStatus "TRCM ECU: a117 VEH prnd status";
CM_ SG_ 1298 TRCM_a117_PARTY_epbmStatus "TRCM ECU: a117 PARTY epbm status";
CM_ SG_ 1298 TRCM_a117_VEH_vehNm "TRCM ECU: a117 VEH veh nm";
CM_ SG_ 1298 TRCM_a117_VEH_hvacBlowerFdb "TRCM ECU: a117 VEH hvac blower fdb";
CM_ SG_ 1298 TRCM_a117_VEH_LVPowerState "TRCM ECU: a117 VEH LV power state";
CM_ SG_ 1298 TRCM_a117_VEH_restraintStatus "TRCM ECU: a117 VEH restraint status";
CM_ SG_ 1298 TRCM_a117_VEH_lightStatus "TRCM ECU: a117 VEH light status";
CM_ SG_ 1298 TRCM_a117_VEH_seatStatus "TRCM ECU: a117 VEH seat status";
CM_ SG_ 1298 TRCM_a117_BDY_falconSwitchStatus "TRCM ECU: a117 BDY falcon switch status";
CM_ SG_ 1298 TRCM_a117_VEH_doorStatus "TRCM ECU: a117 VEH door status";
CM_ SG_ 1298 TRCM_a117_VEH_doorStatus2 "TRCM ECU: a117 VEH door status2";
CM_ SG_ 1298 TRCM_a117_VEH_windowStatus "TRCM ECU: a117 VEH window status";
CM_ SG_ 1298 TRCM_a117_VEH_switchStatus "TRCM ECU: a117 VEH switch status";
CM_ SG_ 1298 TRCM_a117_VEH_intrusionSensorSta "TRCM ECU: a117 VEH intrusion sensor status";
CM_ SG_ 1298 TRCM_a117_VEH_liftgateStatus "TRCM ECU: a117 VEH liftgate status";
CM_ SG_ 1298 TRCM_a117_VEH_seatStatus2 "TRCM ECU: a117 VEH seat status2";
CM_ SG_ 1298 TRCM_a117_PARTY_restraintStatus "TRCM ECU: a117 PARTY restraint status";
CM_ SG_ 1298 TRCM_a117_VEH_thermalStatus "TRCM ECU: a117 VEH thermal status";
CM_ SG_ 1298 TRCM_a117_PARTY_doorStatus "TRCM ECU: a117 PARTY door status";
CM_ SG_ 1298 TRCM_a117_VEH_status "TRCM ECU: a117 VEH status";
CM_ SG_ 1298 TRCM_a117_PARTY_prndStatus "TRCM ECU: a117 PARTY prnd status";
CM_ SG_ 1298 TRCM_a118_VEH_vehNm "TRCM ECU: a118 VEH veh nm";
CM_ SG_ 1298 TRCM_a118_VEH_lighting "TRCM ECU: a118 VEH lighting";
CM_ SG_ 1298 TRCM_a118_VEH_sensors "TRCM ECU: a118 VEH sensors";
CM_ SG_ 1298 TRCM_a118_VEH_status "TRCM ECU: a118 VEH status";
CM_ SG_ 1298 TRCM_a118_VEH_okToUseHighPwr "TRCM ECU: a118 VEH ok to use high pwr";
CM_ SG_ 1298 TRCM_a118_VEH_LVPowerState "TRCM ECU: a118 VEH LV power state";
CM_ SG_ 1298 TRCM_a118_VEH_coolant "TRCM ECU: a118 VEH coolant";
CM_ SG_ 1298 TRCM_a118_VEH_vehicleStatus "TRCM ECU: a118 VEH vehicle status";
CM_ SG_ 1298 TRCM_a118_VEH_12VBatteryStatus "TRCM ECU: a118 VEH 12 v battery status";
CM_ SG_ 1298 TRCM_a118_VEH_systemStatus "TRCM ECU: a118 VEH system status";
CM_ SG_ 1298 TRCM_a118_PARTY_LVPowerState "TRCM ECU: a118 PARTY LV power state";
CM_ SG_ 1298 TRCM_a118_PARTY_outputPowerStatu "TRCM ECU: a118 PARTY output power status";
CM_ SG_ 1298 TRCM_a118_PARTY_vehicleTime "TRCM ECU: a118 PARTY vehicle time";
CM_ SG_ 1298 TRCM_a118_VEH_thermalCommand "TRCM ECU: a118 VEH thermal command";
CM_ SG_ 1298 TRCM_a118_CH_LVPowerState "TRCM ECU: a118 CH LV power state";
CM_ SG_ 1298 TRCM_a118_PARTY_sensors "TRCM ECU: a118 PARTY sensors";
CM_ SG_ 1298 TRCM_a118_CH_sensors "TRCM ECU: a118 CH sensors";
CM_ SG_ 1298 TRCM_a118_VEH_interNodeResistanc "TRCM ECU: a118 VEH inter node resistance";
CM_ SG_ 1298 TRCM_a118_CH_lighting "TRCM ECU: a118 CH lighting";
CM_ SG_ 1298 TRCM_a118_VEH_lightStatus "TRCM ECU: a118 VEH light status";
CM_ SG_ 1298 TRCM_a118_PARTY_vehNm "TRCM ECU: a118 PARTY veh nm";
CM_ SG_ 1298 TRCM_a118_CH_12VBatteryStatus "TRCM ECU: a118 CH 12 v battery status";
CM_ SG_ 1298 TRCM_a118_CH_LVBMS_statusHigh "TRCM ECU: a118 CH LVBMS status high";
CM_ SG_ 1298 TRCM_a118_CH_alertMatrix "TRCM ECU: a118 CH alert matrix";
CM_ SG_ 1298 TRCM_a118_BDY_outputPowerStatus "TRCM ECU: a118 BDY output power status";
CM_ SG_ 1298 TRCM_a118_BDY_vehicleTime "TRCM ECU: a118 BDY vehicle time";
CM_ SG_ 1298 TRCM_a118_PARTY_AP_vehicleState1 "TRCM ECU: a118 PARTY AP vehicle state1 hz muxed";
CM_ SG_ 1298 TRCM_a118_BDY_AP_vehicleState1Hz "TRCM ECU: a118 BDY AP vehicle state1 hz muxed";
CM_ SG_ 1298 TRCM_a119_VEH_steerAngle "TRCM ECU: a119 VEH steer angle";
CM_ SG_ 1298 TRCM_a119_VEH_leftStalk "TRCM ECU: a119 VEH left stalk";
CM_ SG_ 1298 TRCM_a119_VEH_rightStalk "TRCM ECU: a119 VEH right stalk";
CM_ SG_ 1298 TRCM_a119_PARTY_rightStalk "TRCM ECU: a119 PARTY right stalk";
CM_ SG_ 1298 TRCM_a119_CH_steerAngle "TRCM ECU: a119 CH steer angle";
CM_ SG_ 1298 TRCM_a119_PARTY_steerAngle "TRCM ECU: a119 PARTY steer angle";
CM_ SG_ 1298 TRCM_a120_PARTY_chassisCntl "TRCM ECU: a120 PARTY chassis cntl";
CM_ SG_ 1298 TRCM_a120_VEH_systemStatus "TRCM ECU: a120 VEH system status";
CM_ SG_ 1298 TRCM_a120_CH_chassisCntl "TRCM ECU: a120 CH chassis cntl";
CM_ SG_ 1298 TRCM_a120_PARTY_systemStatus "TRCM ECU: a120 PARTY system status";
CM_ SG_ 1298 TRCM_a120_PARTY_torque "TRCM ECU: a120 PARTY torque";
CM_ SG_ 1298 TRCM_a120_VEH_torque "TRCM ECU: a120 VEH torque";
CM_ SG_ 1298 TRCM_a120_PARTY_locStatus "TRCM ECU: a120 PARTY loc status";
CM_ SG_ 1298 TRCM_a120_PARTY_speed "TRCM ECU: a120 PARTY speed";
CM_ SG_ 1298 TRCM_a120_VEH_speed "TRCM ECU: a120 VEH speed";
CM_ SG_ 1298 TRCM_a120_PARTY_status "TRCM ECU: a120 PARTY status";
CM_ SG_ 1298 TRCM_a120_PT_speed "TRCM ECU: a120 PT speed";
CM_ SG_ 1298 TRCM_a120_PT_systemStatus "TRCM ECU: a120 PT system status";
CM_ SG_ 1298 TRCM_a120_PARTY_vehicleEstimates "TRCM ECU: a120 PARTY vehicle estimates";
CM_ SG_ 1298 TRCM_a120_VEH_aggregatedAxleSpee "TRCM ECU: a120 VEH aggregated axle speed";
CM_ SG_ 1298 TRCM_a120_PARTY_aggregatedAxleSp "TRCM ECU: a120 PARTY aggregated axle speed";
CM_ SG_ 1298 TRCM_a120_VEH_systemPower "TRCM ECU: a120 VEH system power";
CM_ SG_ 1298 TRCM_a120_PT_systemPower "TRCM ECU: a120 PT system power";
CM_ SG_ 1298 TRCM_a120_PARTY_stalklessInterfa "TRCM ECU: a120 PARTY stalkless interfaces";
CM_ SG_ 1298 TRCM_a120_CH_speed "TRCM ECU: a120 CH speed";
CM_ SG_ 1298 TRCM_a120_VEH_estimatedBrakeTemp "TRCM ECU: a120 VEH estimated brake temp";
CM_ SG_ 1298 TRCM_a120_PARTY_prndControl "TRCM ECU: a120 PARTY prnd control";
CM_ SG_ 1298 TRCM_a120_PARTY_locStatus2 "TRCM ECU: a120 PARTY loc status2";
CM_ SG_ 1298 TRCM_a120_VEH_chassisCntl "TRCM ECU: a120 VEH chassis cntl";
CM_ SG_ 1298 TRCM_a120_VEH_locStatus "TRCM ECU: a120 VEH loc status";
CM_ SG_ 1298 TRCM_a120_VEH_locStatus2 "TRCM ECU: a120 VEH loc status2";
CM_ SG_ 1298 TRCM_a120_VEH_prndControl "TRCM ECU: a120 VEH prnd control";
CM_ SG_ 1298 TRCM_a120_VEH_vehicleEstimates "TRCM ECU: a120 VEH vehicle estimates";
BA_DEF_ BO_ "GenMsgCycleTime" INT 0 3600000;
BA_DEF_ BO_ "GenMsgSendType" ENUM "Cyclic","NotUsed","NotUsed","NotUsed","NotUsed","NotUsed","NotUsed","IfActive","NoMsgSendType","NotUsed";
BA_DEF_ BO_ "VFrameFormat" ENUM "StandardCAN","ExtendedCAN","reserved","J1939PG","reserved","reserved","reserved","reserved","reserved","reserved","reserved","reserved","reserved","reserved","StandardCAN_FD","ExtendedCAN_FD";
BA_DEF_ BO_ "CANFD_BRS" ENUM "0","1";
BA_DEF_ SG_ "SystemSignalLongSymbol" STRING;
BA_DEF_ SG_ "Confidence" ENUM "layout-only","plausible","validated";
BA_DEF_DEF_ "GenMsgCycleTime" 0;
BA_DEF_DEF_ "GenMsgSendType" "NoMsgSendType";
BA_DEF_DEF_ "VFrameFormat" "StandardCAN";
BA_DEF_DEF_ "CANFD_BRS" "1";
BA_DEF_DEF_ "SystemSignalLongSymbol" "";
BA_DEF_DEF_ "Confidence" "layout-only";
BA_ "SystemSignalLongSymbol" SG_ 1835 TAS_a098_VCFRONT_LVPowerState_MI "TAS_a098_VCFRONT_LVPowerState_MIA";
BA_ "SystemSignalLongSymbol" SG_ 1835 TAS_a098_VCFRONT_systemStatus_MI "TAS_a098_VCFRONT_systemStatus_MIA";
BA_ "SystemSignalLongSymbol" SG_ 1835 TAS_a099_UI_driverAssistMapData_ "TAS_a099_UI_driverAssistMapData_MIA";
BA_ "SystemSignalLongSymbol" SG_ 1835 TAS_a099_UI_suspensionControl_MI "TAS_a099_UI_suspensionControl_MIA";
BA_ "SystemSignalLongSymbol" SG_ 852 TAS_a066_undefinedInstructionAbo "TAS_a066_undefinedInstructionAbort";
BA_ "SystemSignalLongSymbol" SG_ 852 TAS_a150_accelAvgImplausible_FL_ "TAS_a150_accelAvgImplausible_FL_X";
BA_ "SystemSignalLongSymbol" SG_ 852 TAS_a151_accelAvgImplausible_FL_ "TAS_a151_accelAvgImplausible_FL_Y";
BA_ "SystemSignalLongSymbol" SG_ 852 TAS_a152_accelAvgImplausible_FL_ "TAS_a152_accelAvgImplausible_FL_Z";
BA_ "SystemSignalLongSymbol" SG_ 852 TAS_a153_accelAvgImplausible_FR_ "TAS_a153_accelAvgImplausible_FR_X";
BA_ "SystemSignalLongSymbol" SG_ 852 TAS_a154_accelAvgImplausible_FR_ "TAS_a154_accelAvgImplausible_FR_Y";
BA_ "SystemSignalLongSymbol" SG_ 852 TAS_a155_accelAvgImplausible_FR_ "TAS_a155_accelAvgImplausible_FR_Z";
BA_ "SystemSignalLongSymbol" SG_ 852 TAS_a156_accelAvgImplausible_RL_ "TAS_a156_accelAvgImplausible_RL_X";
BA_ "SystemSignalLongSymbol" SG_ 852 TAS_a157_accelAvgImplausible_RL_ "TAS_a157_accelAvgImplausible_RL_Y";
BA_ "SystemSignalLongSymbol" SG_ 852 TAS_a158_accelAvgImplausible_RL_ "TAS_a158_accelAvgImplausible_RL_Z";
BA_ "SystemSignalLongSymbol" SG_ 852 TAS_a159_accelAvgImplausible_RR_ "TAS_a159_accelAvgImplausible_RR_X";
BA_ "SystemSignalLongSymbol" SG_ 852 TAS_a160_accelAvgImplausible_RR_ "TAS_a160_accelAvgImplausible_RR_Y";
BA_ "SystemSignalLongSymbol" SG_ 852 TAS_a161_accelAvgImplausible_RR_ "TAS_a161_accelAvgImplausible_RR_Z";
BA_ "SystemSignalLongSymbol" SG_ 852 TAS_a192_rideHeightObserverDiver "TAS_a192_rideHeightObserverDivergence";
BA_ "SystemSignalLongSymbol" SG_ 852 TAS_a197_invalidAdaptiveModeRequ "TAS_a197_invalidAdaptiveModeRequested";
BA_ "Confidence" SG_ 523 TAS_rawHeightFL 1;
BA_ "Confidence" SG_ 523 TAS_staticHeightEstimateFL 1;
BA_ "Confidence" SG_ 523 TAS_componentPressureFL 1;
BA_ "Confidence" SG_ 523 TAS_rawHeightFR 1;
BA_ "Confidence" SG_ 523 TAS_staticHeightEstimateFR 1;
BA_ "Confidence" SG_ 523 TAS_componentPressureFR 1;
BA_ "Confidence" SG_ 523 TAS_rawHeightRL 1;
BA_ "Confidence" SG_ 523 TAS_staticHeightEstimateRL 1;
BA_ "Confidence" SG_ 523 TAS_componentPressureRL 1;
BA_ "Confidence" SG_ 523 TAS_rawHeightRR 1;
BA_ "Confidence" SG_ 523 TAS_staticHeightEstimateRR 1;
BA_ "Confidence" SG_ 523 TAS_componentPressureRR 1;
BA_ "Confidence" SG_ 1398 TAS_endstopState 1;
BA_ "Confidence" SG_ 1398 TAS_continuousControlState 1;
BA_ "Confidence" SG_ 1398 TAS_activeTireTune 1;
BA_ "Confidence" SG_ 1398 TAS_roughnessRaiseReason 1;
BA_ "Confidence" SG_ 1398 TAS_frontMetricDrivesRear 1;
BA_ "Confidence" SG_ 1398 TAS_roadCondition 1;
BA_ "Confidence" SG_ 1398 TAS_bellyProtect 1;
BA_ "Confidence" SG_ 1398 TAS_frontMetricDrivesFront 1;
BA_ "Confidence" SG_ 1398 TAS_speedBumpAxleFront 1;
BA_ "Confidence" SG_ 1398 TAS_speedBumpAxleRear 1;
BA_ "Confidence" SG_ 1398 TAS_holeProtectFL 1;
BA_ "Confidence" SG_ 1398 TAS_holeProtectFR 1;
BA_ "Confidence" SG_ 1398 TAS_holeProtectRL 1;
BA_ "Confidence" SG_ 1398 TAS_holeProtectRR 1;
BA_ "Confidence" SG_ 1398 TAS_stepProtectFL 1;
BA_ "Confidence" SG_ 1398 TAS_stepProtectFR 1;
BA_ "Confidence" SG_ 1398 TAS_stepProtectRL 1;
BA_ "Confidence" SG_ 1398 TAS_stepProtectRR 1;
BA_ "Confidence" SG_ 1398 TAS_FDUTorqueCorruptionScale 1;
BA_ "Confidence" SG_ 1398 TAS_sprungMassEstimate 1;
BA_ "Confidence" SG_ 1357 TAS_infoBuildType 1;
BA_ "Confidence" SG_ 525 TAS_levelingState 1;
BA_ "Confidence" SG_ 525 TAS_levelingItem 1;
BA_ "Confidence" SG_ 525 TAS_pressureGallery 1;
BA_ "Confidence" SG_ 525 TAS_pressureReservoir 1;
BA_ "Confidence" SG_ 525 TAS_runMode 1;
BA_ "Confidence" SG_ 525 TAS_filterMode 1;
BA_ "Confidence" SG_ 525 TAS_compressorRun 1;
BA_ "Confidence" SG_ 525 TAS_twistDetected 1;
BA_ "Confidence" SG_ 525 TAS_leanDetected 1;
BA_ "Confidence" SG_ 525 TAS_limpHomeMode 1;
BA_ "Confidence" SG_ 525 TAS_targetLevel 1;
BA_ "Confidence" SG_ 525 TAS_currentLevel 1;
BA_ "Confidence" SG_ 525 TAS_jackMode 1;
BA_ "Confidence" SG_ 409 TAS_adaptiveActivityFL_C 1;
BA_ "Confidence" SG_ 409 TAS_adaptiveActivityFL_R 1;
BA_ "Confidence" SG_ 409 TAS_adaptiveActivityFR_C 1;
BA_ "Confidence" SG_ 409 TAS_adaptiveActivityFR_R 1;
BA_ "Confidence" SG_ 409 TAS_adaptiveActivityRL_C 1;
BA_ "Confidence" SG_ 409 TAS_adaptiveActivityRL_R 1;
BA_ "Confidence" SG_ 409 TAS_adaptiveActivityRR_C 1;
BA_ "Confidence" SG_ 409 TAS_adaptiveActivityRR_R 1;
BA_ "Confidence" SG_ 409 TAS_uiHeightFL 1;
BA_ "Confidence" SG_ 409 TAS_uiHeightFR 1;
BA_ "Confidence" SG_ 409 TAS_uiHeightRL 1;
BA_ "Confidence" SG_ 409 TAS_uiHeightRR 1;
BA_ "Confidence" SG_ 410 TAS_bodyAccelFL 1;
BA_ "Confidence" SG_ 410 TAS_bodyAccelFR 1;
BA_ "Confidence" SG_ 410 TAS_bodyAccelRL 1;
BA_ "Confidence" SG_ 410 TAS_bodyAccelRR 1;
BA_ "Confidence" SG_ 538 TAS_adaptiveRideModeOverride 1;
BA_ "Confidence" SG_ 538 TAS_launchModeState 1;
BA_ "Confidence" SG_ 538 TAS_restrictLevelingShowroom 1;
BA_ "Confidence" SG_ 1409 TCU_cpuTemp 1;
BA_ "Confidence" SG_ 1409 TCU_cpuUsage 1;
BA_ "Confidence" SG_ 1409 TCU_mdmCoreTemperature 1;
BA_ "Confidence" SG_ 1409 TCU_availableMemory 1;
BA_ "Confidence" SG_ 1409 TCU_pwm 1;
BA_ "Confidence" SG_ 1409 TCU_pwmcap 1;
BA_ "Confidence" SG_ 1409 TCU_totalResumes 1;
BA_ "Confidence" SG_ 1409 TCU_mdmUplinkQueueSize 1;
BA_ "Confidence" SG_ 1409 TCU_mdmRSRP 1;
BA_ "Confidence" SG_ 1409 TCU_mdmSINR 1;
BA_ "Confidence" SG_ 1409 TCU_mdmUplinkAllowedRate 1;
BA_ "Confidence" SG_ 1409 TCU_mdmIMSStatus 1;
BA_ "Confidence" SG_ 1409 TCU_mdmBusyActive 1;
BA_ "Confidence" SG_ 879 TPMS_learningStatus 1;
BA_ "Confidence" SG_ 879 TPMS_localisationStatus 1;
BA_ "Confidence" SG_ 879 TPMS_sensorNoResponseFL 1;
BA_ "Confidence" SG_ 879 TPMS_sensorNoResponseFR 1;
BA_ "Confidence" SG_ 879 TPMS_sensorNoResponseRL 1;
BA_ "Confidence" SG_ 879 TPMS_sensorNoResponseRR 1;
BA_ "Confidence" SG_ 879 TPMS_sensorBatteryLowFL 1;
BA_ "Confidence" SG_ 879 TPMS_sensorBatteryLowFR 1;
BA_ "Confidence" SG_ 879 TPMS_sensorBatteryLowRL 1;
BA_ "Confidence" SG_ 879 TPMS_sensorBatteryLowRR 1;
BA_ "Confidence" SG_ 879 TPMS_sensorDefectiveFL 1;
BA_ "Confidence" SG_ 879 TPMS_sensorDefectiveFR 1;
BA_ "Confidence" SG_ 879 TPMS_sensorDefectiveRL 1;
BA_ "Confidence" SG_ 879 TPMS_sensorDefectiveRR 1;
BA_ "Confidence" SG_ 879 TPMS_eolNotCompleted 1;
BA_ "Confidence" SG_ 879 TPMS_rcpFront 1;
BA_ "Confidence" SG_ 879 TPMS_rcpRear 1;
BA_ "Confidence" SG_ 802 TPMS_pressureFL 1;
BA_ "Confidence" SG_ 802 TPMS_temperatureFL 1;
BA_ "Confidence" SG_ 802 TPMS_pressureFR 1;
BA_ "Confidence" SG_ 802 TPMS_temperatureFR 1;
BA_ "Confidence" SG_ 802 TPMS_pressureRL 1;
BA_ "Confidence" SG_ 802 TPMS_temperatureRL 1;
BA_ "Confidence" SG_ 802 TPMS_pressureRR 1;
BA_ "Confidence" SG_ 802 TPMS_temperatureRR 1;
BA_ "SystemSignalLongSymbol" SG_ 1298 TRCM_a101_LIPC_externalWatchdogH "TRCM_a101_LIPC_externalWatchdogHeartBeat";
BA_ "SystemSignalLongSymbol" SG_ 1298 TRCM_a115_UI_corianderVehicleCon "TRCM_a115_UI_corianderVehicleControl";
BA_ "SystemSignalLongSymbol" SG_ 1298 TRCM_a117_VEH_intrusionSensorSta "TRCM_a117_VEH_intrusionSensorStatus";
BA_ "SystemSignalLongSymbol" SG_ 1298 TRCM_a118_PARTY_outputPowerStatu "TRCM_a118_PARTY_outputPowerStatus";
BA_ "SystemSignalLongSymbol" SG_ 1298 TRCM_a118_VEH_interNodeResistanc "TRCM_a118_VEH_interNodeResistance";
BA_ "SystemSignalLongSymbol" SG_ 1298 TRCM_a118_PARTY_AP_vehicleState1 "TRCM_a118_PARTY_AP_vehicleState1HzMuxed";
BA_ "SystemSignalLongSymbol" SG_ 1298 TRCM_a118_BDY_AP_vehicleState1Hz "TRCM_a118_BDY_AP_vehicleState1HzMuxed";
BA_ "SystemSignalLongSymbol" SG_ 1298 TRCM_a120_VEH_aggregatedAxleSpee "TRCM_a120_VEH_aggregatedAxleSpeed";
BA_ "SystemSignalLongSymbol" SG_ 1298 TRCM_a120_PARTY_aggregatedAxleSp "TRCM_a120_PARTY_aggregatedAxleSpeed";
BA_ "SystemSignalLongSymbol" SG_ 1298 TRCM_a120_PARTY_stalklessInterfa "TRCM_a120_PARTY_stalklessInterfaces";
VAL_ 1398 TAS_endstopState 1 "TAS_DAMPING_STATE_ACTIVE" 0 "TAS_DAMPING_STATE_STANDBY" ;
VAL_ 1398 TAS_continuousControlState 1 "TAS_DAMPING_STATE_ACTIVE" 0 "TAS_DAMPING_STATE_STANDBY" ;
VAL_ 1398 TAS_activeTireTune 1 "TAS_TIRE_TUNE_MICHELIN_SUMMER_21" 0 "TAS_TIRE_TUNE_DEFAULT" ;
VAL_ 1398 TAS_roughnessRaiseReason 2 "TAS_ROUGHNESS_RAISE_REASON_LOOKAHEAD" 1 "TAS_ROUGHNESS_RAISE_REASON_LEGACY" 0 "TAS_ROUGHNESS_RAISE_REASON_NONE" ;
VAL_ 1398 TAS_frontMetricDrivesRear 3 "TAS_ACTION_ACTIVE" 2 "TAS_ACTION_ARMED" 1 "TAS_ACTION_STANDBY" 0 "TAS_ACTION_DISABLED" ;
VAL_ 1398 TAS_bellyProtect 3 "TAS_ACTION_ACTIVE" 2 "TAS_ACTION_ARMED" 1 "TAS_ACTION_STANDBY" 0 "TAS_ACTION_DISABLED" ;
VAL_ 1398 TAS_frontMetricDrivesFront 3 "TAS_ACTION_ACTIVE" 2 "TAS_ACTION_ARMED" 1 "TAS_ACTION_STANDBY" 0 "TAS_ACTION_DISABLED" ;
VAL_ 1398 TAS_speedBumpAxleFront 4 "TAS_ACTION_CANCELED" 3 "TAS_ACTION_ACTIVE" 2 "TAS_ACTION_ARMED" 1 "TAS_ACTION_STANDBY" 0 "TAS_ACTION_DISABLED" ;
VAL_ 1398 TAS_speedBumpAxleRear 4 "TAS_ACTION_CANCELED" 3 "TAS_ACTION_ACTIVE" 2 "TAS_ACTION_ARMED" 1 "TAS_ACTION_STANDBY" 0 "TAS_ACTION_DISABLED" ;
VAL_ 1398 TAS_holeProtectFL 3 "TAS_ACTION_ACTIVE" 2 "TAS_ACTION_ARMED" 1 "TAS_ACTION_STANDBY" 0 "TAS_ACTION_DISABLED" ;
VAL_ 1398 TAS_holeProtectFR 3 "TAS_ACTION_ACTIVE" 2 "TAS_ACTION_ARMED" 1 "TAS_ACTION_STANDBY" 0 "TAS_ACTION_DISABLED" ;
VAL_ 1398 TAS_holeProtectRL 3 "TAS_ACTION_ACTIVE" 2 "TAS_ACTION_ARMED" 1 "TAS_ACTION_STANDBY" 0 "TAS_ACTION_DISABLED" ;
VAL_ 1398 TAS_holeProtectRR 3 "TAS_ACTION_ACTIVE" 2 "TAS_ACTION_ARMED" 1 "TAS_ACTION_STANDBY" 0 "TAS_ACTION_DISABLED" ;
VAL_ 1398 TAS_stepProtectFL 3 "TAS_ACTION_ACTIVE" 2 "TAS_ACTION_ARMED" 1 "TAS_ACTION_STANDBY" 0 "TAS_ACTION_DISABLED" ;
VAL_ 1398 TAS_stepProtectFR 3 "TAS_ACTION_ACTIVE" 2 "TAS_ACTION_ARMED" 1 "TAS_ACTION_STANDBY" 0 "TAS_ACTION_DISABLED" ;
VAL_ 1398 TAS_stepProtectRL 3 "TAS_ACTION_ACTIVE" 2 "TAS_ACTION_ARMED" 1 "TAS_ACTION_STANDBY" 0 "TAS_ACTION_DISABLED" ;
VAL_ 1398 TAS_stepProtectRR 3 "TAS_ACTION_ACTIVE" 2 "TAS_ACTION_ARMED" 1 "TAS_ACTION_STANDBY" 0 "TAS_ACTION_DISABLED" ;
VAL_ 1357 TAS_infoBuildType 4 "INFO_MFG_BUILD" 3 "INFO_TRACEABLE_CI_BUILD" 2 "INFO_LOCAL_BUILD" 1 "INFO_PLATFORM_BUILD" 0 "INFO_UNKNOWN_BUILD" ;
VAL_ 525 TAS_levelingState 15 "LEVELING_STATE_CROSSLINK" 14 "LEVELING_STATE_QUIET_EXHAUST" 13 "LEVELING_STATE_EXHAUST_RESERVOIR" 12 "LEVELING_STATE_LOWER_SPRING_WITH_COMPRESSOR" 11 "LEVELING_STATE_LOWER_SPRING" 10 "LEVELING_STATE_FILL_SPRING_RESERVOIR_FROM_COMPRESSOR" 9 "LEVELING_STATE_FILL_SPRING_FROM_RESERVOIR" 8 "LEVELING_STATE_FILL_SPRING_FROM_BOOST" 7 "LEVELING_STATE_FILL_SPRING_FROM_COMPRESSOR" 6 "LEVELING_STATE_FILL_RESERVOIR_FROM_COMPRESSOR" 5 "LEVELING_STATE_COMPRESSOR_PREFILL_GALLERY" 4 "LEVELING_STATE_COMPRESSOR_RAMPUP" 3 "LEVELING_STATE_EXHAUST_GALLERY" 2 "LEVELING_STATE_MEASURE_SPRING_PRESSURE" 1 "LEVELING_STATE_READ_P_RESERVOIR" 0 "LEVELING_STATE_IDLE" ;
VAL_ 525 TAS_levelingItem 7 "TAS_LEVELING_ITEM_ALL" 6 "TAS_LEVELING_ITEM_REAR_AXLE" 5 "TAS_LEVELING_ITEM_FRONT_AXLE" 4 "TAS_LEVELING_ITEM_RR" 3 "TAS_LEVELING_ITEM_RL" 2 "TAS_LEVELING_ITEM_FR" 1 "TAS_LEVELING_ITEM_FL" 0 "TAS_LEVELING_ITEM_NONE" ;
VAL_ 525 TAS_runMode 7 "RUN_MODE_DYNO" 6 "RUN_MODE_LOW_POWER" 5 "RUN_MODE_NORMAL" 4 "RUN_MODE_DAN" 3 "RUN_MODE_ASSEMBLY" 2 "RUN_MODE_SERVICE" 1 "RUN_MODE_SYSTEM_CHECK" 0 "RUN_MODE_INIT" ;
VAL_ 525 TAS_filterMode 7 "MODE_STOPPING" 6 "MODE_DRIVE" 5 "MODE_LOADING" 4 "MODE_READY" 3 "MODE_TEST" 2 "MODE_CALIBRATE" 1 "MODE_INIT" 0 "MODE_NONE" ;
VAL_ 525 TAS_limpHomeMode 4 "LIMP_HOME_MODE_40" 3 "LIMP_HOME_MODE_30" 2 "LIMP_HOME_MODE_20" 1 "LIMP_HOME_MODE_10" 0 "LIMP_HOME_MODE_0" ;
VAL_ 525 TAS_targetLevel 4 "TAS_VERY_LOW" 3 "TAS_LOW" 2 "TAS_STANDARD" 1 "TAS_HIGH" 0 "TAS_VERY_HIGH" ;
VAL_ 525 TAS_currentLevel 4 "TAS_VERY_LOW" 3 "TAS_LOW" 2 "TAS_STANDARD" 1 "TAS_HIGH" 0 "TAS_VERY_HIGH" ;
VAL_ 538 TAS_adaptiveRideModeOverride 3 "TAS_ADAPTIVE_RIDE_MODE_SNA" 2 "TAS_ADAPTIVE_RIDE_MODE_SPORT" 1 "TAS_ADAPTIVE_RIDE_MODE_AUTO" 0 "TAS_ADAPTIVE_RIDE_MODE_COMFORT" ;
VAL_ 538 TAS_launchModeState 4 "TAS_LAUNCH_MODE_STATE_RAISE_SUSPENSION" 3 "TAS_LAUNCH_MODE_STATE_READY" 2 "TAS_LAUNCH_MODE_STATE_LOWER_SUSPENSION" 1 "TAS_LAUNCH_MODE_STATE_IDLE" 0 "TAS_LAUNCH_MODE_STATE_BLOCKED" ;
VAL_ 879 TPMS_learningStatus 3 "PASSED" 2 "STOPPED" 1 "ONGOING" 0 "FAILED" ;
VAL_ 879 TPMS_localisationStatus 3 "PASSED" 2 "STOPPED" 1 "ONGOING" 0 "FAILED" ;
